VERSION ""

NS_ :

BS_:

BU_: SteeringControlModule SteeringController SteeringColumnUnit RearAxleSteeringController Engine ChassisController

BO_ 2583299326 GNSSSatsInView: 27 Vector__XXX
 SG_ PRNStatusN : 208|4@1+ (1,0) [0|15] "" Vector__XXX
 SG_ RangeResidualsN : 176|32@1- (1E-005,0) [-21470|21470] "m" Vector__XXX
 SG_ SNRN : 160|16@1- (0.01,0) [-327.64|327.64] "dB" Vector__XXX
 SG_ AzimuthN : 144|16@1+ (0.0001,0) [0|6.28318] "rad" Vector__XXX
 SG_ ElevationN : 128|16@1- (0.0001,0) [-3.14159|3.14159] "rad" Vector__XXX
 SG_ PRNN : 120|8@1+ (1,0) [0|252] "" Vector__XXX
 SG_ PRNStatus1 : 112|4@1+ (1,0) [0|15] "" Vector__XXX
 SG_ RangeResiduals1 : 80|32@1- (1E-005,0) [-21470|21470] "m" Vector__XXX
 SG_ SNR1 : 64|16@1- (0.01,0) [-327.64|327.64] "dB" Vector__XXX
 SG_ Azimuth1 : 48|16@1+ (0.0001,0) [0|6.28318] "rad" Vector__XXX
 SG_ Elevation1 : 32|16@1- (0.0001,0) [-3.14159|3.14159] "rad" Vector__XXX
 SG_ PRN1 : 24|8@1+ (1,0) [0|252] "" Vector__XXX
 SG_ NumberOfSVs_ : 16|8@1+ (1,0) [0|252] "" Vector__XXX
 SG_ SID : 0|8@1+ (1,0) [0|252] "" Vector__XXX
 SG_ RangeResidualMode : 8|2@1- (1,0) [0|3] "" Vector__XXX

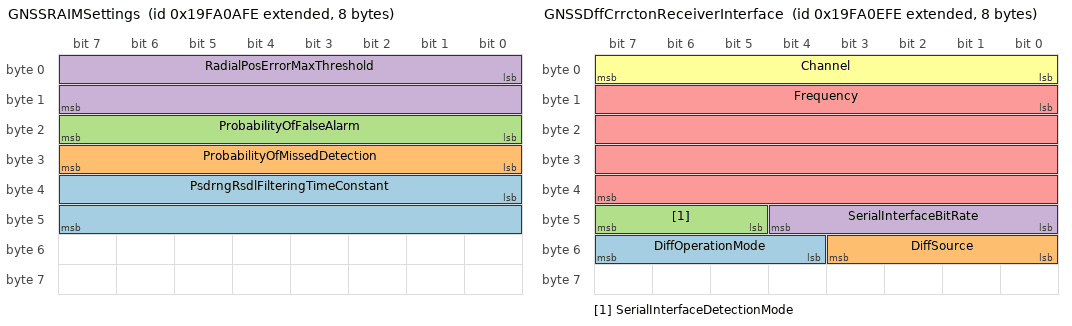
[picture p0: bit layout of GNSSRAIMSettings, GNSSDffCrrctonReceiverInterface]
BO_ 2583300862 GNSSRAIMSettings: 8 Vector__XXX
 SG_ PsdrngRsdlFilteringTimeConstant : 32|16@1+ (1,0) [0|65532] "sec" Vector__XXX
 SG_ ProbabilityOfMissedDetection : 24|8@1- (1,0) [-124|124] "%" Vector__XXX
 SG_ ProbabilityOfFalseAlarm : 16|8@1- (1,0) [-124|124] "" Vector__XXX
 SG_ RadialPosErrorMaxThreshold : 0|16@1+ (0.01,0) [0|655.32] "m" Vector__XXX

BO_ 2583300606 GNSSRAIMOutput: 15 Vector__XXX
 SG_ StdDeviationOfBias : 104|16@1- (0.01,0) [-327.64|327.64] "m" Vector__XXX
 SG_ EstimateOfPseudorangeBias : 88|16@1- (0.01,0) [-327.64|327.64] "m" Vector__XXX
 SG_ ProbabilityOfMissedDetection : 72|8@1- (1,0) [-124|124] "%" Vector__XXX
 SG_ SVIDOfMostLikelyFailedSat : 64|8@1+ (1,0) [0|252] "" Vector__XXX
 SG_ AltitudeExpectedError : 48|16@1- (0.01,0) [-327.64|327.64] "m" Vector__XXX
 SG_ LongitudeExpectedError : 32|16@1- (0.01,0) [-327.64|327.64] "m" Vector__XXX
 SG_ LatitudeExpectedError : 16|16@1- (0.01,0) [-327.64|327.64] "m" Vector__XXX
 SG_ IntegrityFlag : 8|2@1+ (1,0) [0|3] "" Vector__XXX
 SG_ SequenceID_ : 0|8@1+ (1,0) [0|252] "" Vector__XXX

BO_ 2583299838 GNSSPseudorangeNoiseStatistics: 15 Vector__XXX
 SG_ STDOfAltError : 104|16@1+ (0.01,0) [0|655.32] "m" Vector__XXX
 SG_ STDOfLonError : 88|16@1+ (0.01,0) [0|655.32] "m" Vector__XXX
 SG_ STDOfLatError : 72|16@1+ (0.01,0) [0|655.32] "m" Vector__XXX
 SG_ OrientationOfMajorAxis : 56|16@1+ (0.0001,0) [0|6.28318] "rad" Vector__XXX
 SG_ STDOfMinorAxis : 40|16@1+ (0.01,0) [0|655.32] "m" Vector__XXX
 SG_ STDOfMajorAxis : 24|16@1+ (0.01,0) [0|655.32] "m" Vector__XXX
 SG_ RMSOfPosUncertainty : 8|16@1+ (0.01,0) [0|655.32] "m" Vector__XXX
 SG_ SID : 0|8@1+ (1,0) [0|252] "" Vector__XXX

BO_ 2583301118 GNSSPseudorangeErrorStatistics: 15 Vector__XXX
 SG_ StdDevAltitudeError : 104|16@1+ (0.01,0) [0|655.32] "m" Vector__XXX
 SG_ StdDevLongitudeError : 88|16@1+ (0.01,0) [0|655.32] "m" Vector__XXX
 SG_ StdDevLatitudeError : 72|16@1+ (0.01,0) [0|655.32] "m" Vector__XXX
 SG_ OrientationOfErrorEllipse : 56|16@1+ (0.0001,0) [0|6.28318] "rad" Vector__XXX
 SG_ StdDevMinorErrorEllipse : 40|16@1+ (0.01,0) [0|655.32] "m" Vector__XXX
 SG_ StdDevMajorErrorEllipse : 24|16@1+ (0.01,0) [0|655.32] "m" Vector__XXX
 SG_ RMSStdDevOfRangeInputs : 8|16@1+ (0.01,0) [0|655.32] "m" Vector__XXX
 SG_ SequenceID_ : 0|8@1+ (1,0) [0|252] "" Vector__XXX

BO_ 2381841918 GNSSPosData: 51 Vector__XXX
 SG_ AgeOfDGNSSReferenceStationN : 392|16@1+ (0.01,0) [0|655.32] "sec" Vector__XXX
 SG_ ReferenceStationIDN : 380|12@1+ (1,0) [0|4095] "" Vector__XXX
 SG_ ReferenceStationTypeN : 376|4@1+ (1,0) [0|15] "" Vector__XXX
 SG_ AgeOfDGNSSCorrections1_ : 360|16@1+ (0.01,0) [0|655.32] "sec" Vector__XXX
 SG_ ReferenceStationID1_ : 348|12@1+ (1,0) [0|4095] "" Vector__XXX
 SG_ ReferenceStationType1 : 344|4@1+ (1,0) [0|15] "" Vector__XXX
 SG_ NumberOfReferenceStations_ : 336|8@1+ (1,0) [0|252] "" Vector__XXX
 SG_ GeoidalSeparation_ : 304|32@1- (0.01,0) [-21470000|21470000] "m" Vector__XXX
 SG_ PDOP_ : 288|16@1- (0.01,0) [-327.64|327.64] "" Vector__XXX
 SG_ HDOP_ : 272|16@1- (0.01,0) [-327.64|327.64] "" Vector__XXX
 SG_ NumberOfSVs_ : 264|8@1+ (1,0) [0|252] "" Vector__XXX
 SG_ Integrity : 256|2@1+ (1,0) [0|3] "" Vector__XXX
 SG_ MethodGNSS : 252|4@1+ (1,0) [0|15] "" Vector__XXX
 SG_ TypeOfSystem_ : 248|4@1+ (1,0) [0|15] "" Vector__XXX
 SG_ Altitude_high : 216|32@1- (4294.967296,0) [-9223000000000|9223000000000] "m" Vector__XXX
 SG_ Altitude_low : 184|32@1+ (1E-006,0) [0|4294.967295] "m" Vector__XXX
 SG_ Longitude_high : 152|32@1- (4.294967296E-007,0) [-180|180] "deg" Vector__XXX
 SG_ Longitude_low : 120|32@1+ (1E-016,0) [0|4.294967295E-007] "deg" Vector__XXX
 SG_ Latitude_high : 88|32@1- (4.294967296E-007,0) [-90|90] "deg" Vector__XXX
 SG_ Latitude_low : 56|32@1+ (1E-016,0) [0|4.294967295E-007] "deg" Vector__XXX
 SG_ PosTime : 24|32@1+ (0.0001,0) [0|86401] "sec" Vector__XXX
 SG_ PosDate : 8|16@1+ (1,0) [0|65532] "day" Vector__XXX
 SG_ SID : 0|8@1+ (1,0) [0|252] "" Vector__XXX

BO_ 2583301886 GNSSDffCrrctonReceiverInterface: 8 Vector__XXX
 SG_ DiffOperationMode : 52|4@1+ (1,0) [0|15] "" Vector__XXX
 SG_ DiffSource : 48|4@1+ (1,0) [0|15] "" Vector__XXX
 SG_ SerialInterfaceDetectionMode : 45|3@1+ (1,0) [0|7] "" Vector__XXX
 SG_ SerialInterfaceBitRate : 40|5@1+ (1,0) [0|31] "" Vector__XXX
 SG_ Frequency : 8|32@1+ (10,0) [0|327040] "Hz" Vector__XXX
 SG_ Channel : 0|8@1+ (1,0) [0|252] "" Vector__XXX

BO_ 2583302142 GNSSDffCorrectionReceiverSignal: 21 Vector__XXX
 SG_ SatelliteServiceIDNo : 147|16@1+ (1,0) [0|65535] "" Vector__XXX
 SG_ TimeSinceLastSatDiffSync : 131|16@1+ (0.01,0) [0|655.32] "sec" Vector__XXX
 SG_ DiffSource : 127|4@1+ (1,0) [0|15] "" Vector__XXX
 SG_ UsedAsCorrectionSource : 123|2@1+ (1,0) [0|3] "" Vector__XXX
 SG_ DiffSignalDetectionMode : 117|6@1+ (1,0) [0|63] "" Vector__XXX
 SG_ DiffSignalBitRate : 112|5@1+ (1,0) [0|31] "" Vector__XXX
 SG_ StationID : 100|12@1+ (1,0) [0|4095] "" Vector__XXX
 SG_ StationType : 96|4@1+ (1,0) [0|15] "" Vector__XXX
 SG_ Frequency : 64|32@1+ (10,0) [0|327040] "Hz" Vector__XXX
 SG_ SignalSNR : 48|16@1- (0.01,0) [-327.64|327.64] "dB" Vector__XXX
 SG_ SignalStrength : 16|32@1- (0.01,0) [-327.64|327.64] "dB re: uV/m" Vector__XXX
 SG_ Channel : 8|8@1+ (1,0) [0|252] "" Vector__XXX
 SG_ SID : 0|8@1+ (1,0) [0|252] "" Vector__XXX

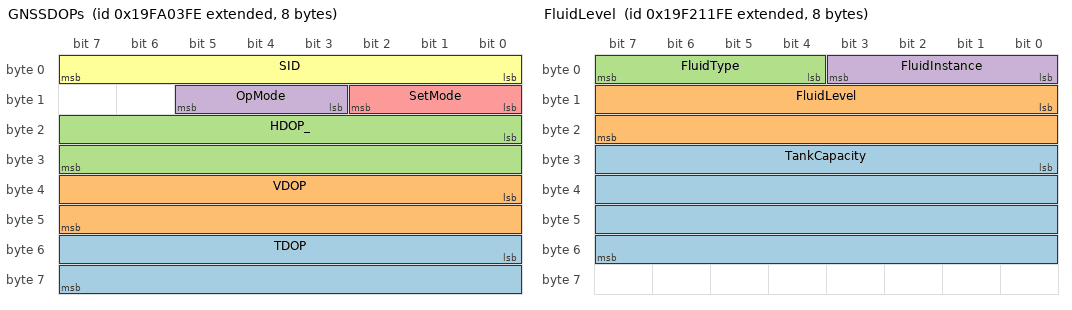
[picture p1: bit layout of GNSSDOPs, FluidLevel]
BO_ 2583299070 GNSSDOPs: 8 Vector__XXX
 SG_ TDOP : 48|16@1- (0.01,0) [-327.64|327.64] "" Vector__XXX
 SG_ VDOP : 32|16@1- (0.01,0) [-327.64|327.64] "" Vector__XXX
 SG_ HDOP_ : 16|16@1- (0.01,0) [-327.64|327.64] "" Vector__XXX
 SG_ OpMode : 11|3@1+ (1,0) [0|7] "" Vector__XXX
 SG_ SetMode : 8|3@1+ (1,0) [0|7] "" Vector__XXX
 SG_ SID : 0|8@1+ (1,0) [0|252] "" Vector__XXX

BO_ 2583298814 GNSSCtrlStatus: 16 Vector__XXX
 SG_ UseAntennaAltitudeFor2DMode : 120|2@1+ (1,0) [0|3] "" Vector__XXX
 SG_ AntennaAltitudeFor2DMode : 88|32@1- (0.01,0) [-21470000|21470000] "m" Vector__XXX
 SG_ MaxCorrectionAge : 72|16@1+ (0.01,0) [0|655.32] "sec" Vector__XXX
 SG_ Pos_VelocityFilter : 70|2@1+ (1,0) [0|3] "" Vector__XXX
 SG_ DGNSSMode : 67|3@1+ (1,0) [0|7] "" Vector__XXX
 SG_ GNSSMode : 64|3@1+ (1,0) [0|7] "" Vector__XXX
 SG_ SNRMask : 48|16@1- (0.01,0) [-327.64|327.64] "dB" Vector__XXX
 SG_ PDOPSwitch : 32|16@1- (0.01,0) [-327.64|327.64] "" Vector__XXX
 SG_ PDOPMask : 16|16@1- (0.01,0) [-327.64|327.64] "" Vector__XXX
 SG_ SVElevationMask : 0|16@1- (0.0001,0) [-3.14159|3.14159] "rad" Vector__XXX

BO_ 2583303422 GLONASSAlmanacData: 26 Vector__XXX
 SG_ tnA2 : 196|12@1+ (1,0) [0|4095] "" Vector__XXX
 SG_ tcA : 168|28@1+ (1,0) [0|268435455] "" Vector__XXX
 SG_ inA : 144|24@1+ (1,0) [0|16777215] "" Vector__XXX
 SG_ nA3 : 120|24@1+ (1,0) [0|16777215] "" Vector__XXX
 SG_ tnA : 96|24@1+ (1,0) [0|16777215] "" Vector__XXX
 SG_ TnA : 72|24@1+ (1,0) [0|16777215] "" Vector__XXX
 SG_ nA2 : 56|16@1+ (1,0) [0|65535] "" Vector__XXX
 SG_ DOT : 48|8@1+ (1,0) [0|255] "" Vector__XXX
 SG_ nA : 32|16@1+ (1,0) [0|65535] "" Vector__XXX
 SG_ HnA : 27|5@1+ (1,0) [0|31] "" Vector__XXX
 SG_ CnA : 26|1@1+ (1,0) [0|1] "" Vector__XXX
 SG_ NA : 8|16@1+ (1,0) [0|65532] "" Vector__XXX
 SG_ PRN : 0|8@1+ (1,0) [0|252] "" Vector__XXX

BO_ 2582778366 FluidLevel: 8 Vector__XXX
 SG_ TankCapacity : 24|32@1+ (0.0001,0) [0|429600] "cu m" Vector__XXX
 SG_ FluidLevel : 8|16@1- (1,0) [-124|124] "" Vector__XXX
 SG_ FluidType : 4|4@1+ (1,0) [0|15] "" Vector__XXX
 SG_ FluidInstance : 0|4@1+ (1,0) [0|15] "" Vector__XXX

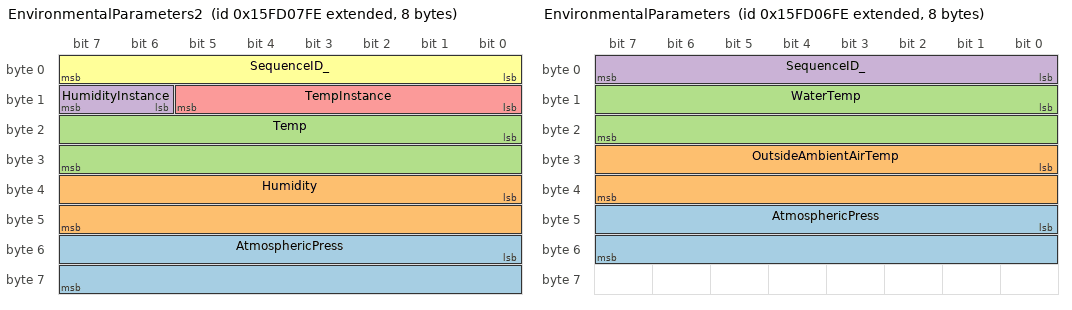
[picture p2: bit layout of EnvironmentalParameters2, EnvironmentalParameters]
BO_ 2516387838 EnvironmentalParameters2: 8 Vector__XXX
 SG_ AtmosphericPress : 48|16@1+ (100,0) [0|6553200] "Pa" Vector__XXX
 SG_ Humidity : 32|16@1- (1,0) [-124|124] "" Vector__XXX
 SG_ Temp : 16|16@1+ (0.01,0) [0|655.32] "°K" Vector__XXX
 SG_ HumidityInstance : 14|2@1+ (1,0) [0|3] "" Vector__XXX
 SG_ TempInstance : 8|6@1+ (1,0) [0|63] "" Vector__XXX
 SG_ SequenceID_ : 0|8@1+ (1,0) [0|252] "" Vector__XXX

BO_ 2516387582 EnvironmentalParameters: 8 Vector__XXX
 SG_ AtmosphericPress : 40|16@1+ (100,0) [0|6553200] "Pa" Vector__XXX
 SG_ OutsideAmbientAirTemp : 24|16@1+ (0.01,0) [0|655.32] "°K" Vector__XXX
 SG_ WaterTemp : 8|16@1+ (0.01,0) [0|655.32] "°K" Vector__XXX
 SG_ SequenceID_ : 0|8@1+ (1,0) [0|252] "" Vector__XXX

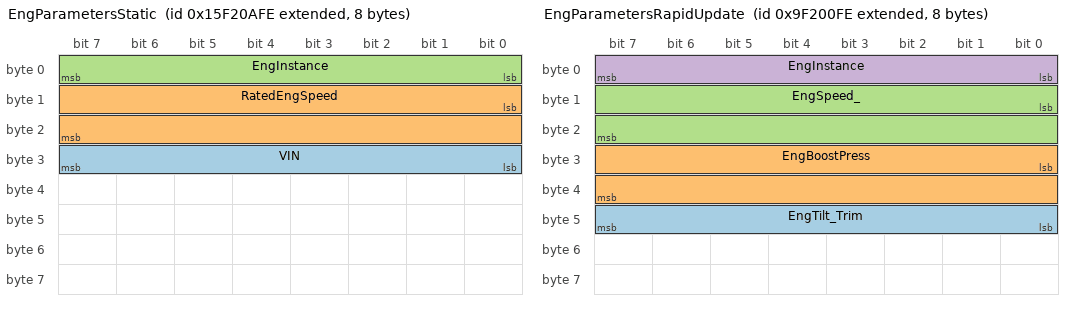
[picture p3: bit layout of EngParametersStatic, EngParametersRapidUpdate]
BO_ 2515667710 EngParametersStatic: 8 Vector__XXX
 SG_ VIN : 24|8@1+ (1,0) [0|255] "ASCII" Vector__XXX
 SG_ RatedEngSpeed : 8|16@1+ (1,0) [0|16383] "rpm" Vector__XXX
 SG_ EngInstance : 0|8@1+ (1,0) [0|255] "" Vector__XXX

BO_ 2314338558 EngParametersRapidUpdate: 8 Vector__XXX
 SG_ EngTilt_Trim : 40|8@1- (1,0) [-124|124] "" Vector__XXX
 SG_ EngBoostPress : 24|16@1+ (100,0) [0|6553200] "Pa" Vector__XXX
 SG_ EngSpeed_ : 8|16@1+ (1,0) [0|16383] "rpm" Vector__XXX
 SG_ EngInstance : 0|8@1+ (1,0) [0|255] "" Vector__XXX

BO_ 2314338814 EngParametersDynamic: 26 Vector__XXX
 SG_ PercentEngTorque : 200|8@1- (1,0) [-124|124] "" Vector__XXX
 SG_ PercentEngLoad : 192|8@1- (1,0) [-124|124] "" Vector__XXX
 SG_ EngDiscreteStatus2 : 176|16@1+ (1,0) [0|65535] "" Vector__XXX
 SG_ EngDiscreteStatus1 : 160|16@1+ (1,0) [0|65535] "" Vector__XXX
 SG_ FuelPress : 136|16@1+ (1000,0) [0|65532000] "Pa" Vector__XXX
 SG_ EngCoolantPress_ : 120|16@1+ (100,0) [0|6553200] "Pa" Vector__XXX
 SG_ TotalEngHours : 88|32@1+ (1,0) [0|32704] "sec" Vector__XXX
 SG_ FuelRate : 72|16@1- (0.0001,0) [-3.2764|3.2764] "(cu m)/hr" Vector__XXX
 SG_ AltPotential : 56|16@1- (0.01,0) [-327.64|327.64] "V" Vector__XXX
 SG_ EngTemp : 40|16@1+ (0.01,0) [0|655.32] "°K" Vector__XXX
 SG_ EngOilTemp : 24|16@1+ (0.1,0) [0|6553.2] "°K" Vector__XXX
 SG_ EngOilPress_ : 8|16@1+ (100,0) [0|6553200] "Pa" Vector__XXX
 SG_ EngInstance : 0|8@1+ (1,0) [0|255] "" Vector__XXX

BO_ 2582975486 DistanceLog: 14 Vector__XXX
 SG_ DistanceSinceLastReset : 80|32@1+ (1,0) [0|32704] "m" Vector__XXX
 SG_ TotalCumulativeDistance : 48|32@1+ (1,0) [0|32704] "m" Vector__XXX
 SG_ MeasurementTime : 16|32@1+ (0.0001,0) [0|86401] "sec" Vector__XXX
 SG_ MeasurementDate : 0|16@1+ (1,0) [0|65532] "day" Vector__XXX

BO_ 2382238206 DirectionData: 14 Vector__XXX
 SG_ Drift : 96|16@1+ (0.01,0) [0|655.32] "m/s" Vector__XXX
 SG_ Set : 80|16@1+ (0.0001,0) [0|6.28318] "rad" Vector__XXX
 SG_ SpeedThroughWater : 64|16@1+ (0.01,0) [0|655.32] "m/s" Vector__XXX
 SG_ Heading : 48|16@1+ (0.0001,0) [0|6.28318] "rad" Vector__XXX
 SG_ SpeedOverGround : 32|16@1+ (0.01,0) [0|655.32] "m/s" Vector__XXX
 SG_ CourseOverGround : 16|16@1+ (0.0001,0) [0|6.28318] "rad" Vector__XXX
 SG_ SID : 8|8@1+ (1,0) [0|252] "" Vector__XXX
 SG_ Set_COG_HeadingRef : 4|2@1+ (1,0) [0|3] "" Vector__XXX
 SG_ DataMode : 0|4@1+ (1,0) [0|15] "" Vector__XXX

BO_ 2583172350 Datum: 8 Vector__XXX
 SG_ LocalDatum : 0|8@1+ (1,0) [0|255] "ASCII" Vector__XXX

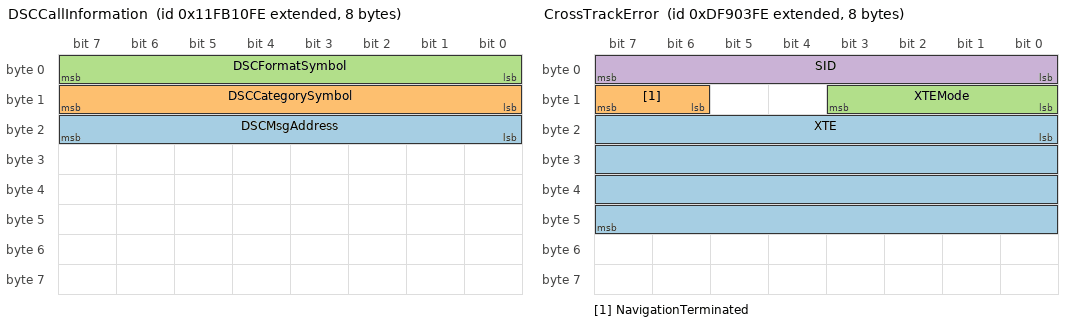
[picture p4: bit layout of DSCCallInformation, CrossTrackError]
BO_ 2449150206 DSCCallInformation: 8 Vector__XXX
 SG_ DSCMsgAddress : 16|8@1+ (1,0) [0|255] "ASCII" Vector__XXX
 SG_ DSCCategorySymbol : 8|8@1+ (1,0) [0|252] "" Vector__XXX
 SG_ DSCFormatSymbol : 0|8@1+ (1,0) [0|252] "" Vector__XXX

BO_ 2583301630 DGNSSCorrections: 16 Vector__XXX
 SG_ IOD : 120|8@1+ (1,0) [0|252] "" Vector__XXX
 SG_ UDRE : 104|16@1+ (0.01,0) [0|655.32] "m" Vector__XXX
 SG_ RRC : 88|16@1- (0.0001,0) [-3.2764|3.2764] "m/s" Vector__XXX
 SG_ PRC : 56|32@1- (0.0001,0) [-214700|214700] "m" Vector__XXX
 SG_ SatelliteID : 48|8@1+ (1,0) [0|252] "" Vector__XXX
 SG_ StationHealth : 40|4@1+ (1,0) [0|15] "" Vector__XXX
 SG_ TimeOfCorrections : 24|16@1+ (1,0) [0|6553.2] "sec" Vector__XXX
 SG_ ReferenceStationType : 20|4@1+ (1,0) [0|15] "" Vector__XXX
 SG_ ReferenceStationID : 8|12@1+ (1,0) [0|4095] "" Vector__XXX
 SG_ SequenceID_ : 0|8@1+ (1,0) [0|252] "" Vector__XXX

BO_ 2583499518 CurrentStationData: 26 Vector__XXX
 SG_ StationIDString : 200|8@1+ (1,0) [0|255] "ASCII" Vector__XXX
 SG_ WaterTemp : 184|16@1+ (0.01,0) [0|655.32] "°K" Vector__XXX
 SG_ CurrentFlowDirection : 168|16@1+ (0.0001,0) [0|6.28318] "rad" Vector__XXX
 SG_ CurrentSpeed : 152|16@1+ (0.01,0) [0|655.32] "m/s" Vector__XXX
 SG_ MeasurementDepth : 120|32@1+ (0.01,0) [0|42950000] "m" Vector__XXX
 SG_ StationLocationLongitude : 88|32@1- (1E-007,0) [-180|180] "deg" Vector__XXX
 SG_ StationLocationLatitude : 56|32@1- (1E-007,0) [-90|90] "deg" Vector__XXX
 SG_ MeasurementTime : 24|32@1+ (0.0001,0) [0|86401] "sec" Vector__XXX
 SG_ MeasurementDate : 8|16@1+ (1,0) [0|65532] "day" Vector__XXX
 SG_ State : 4|3@1+ (1,0) [0|7] "" Vector__XXX
 SG_ Mode : 0|4@1+ (1,0) [0|15] "" Vector__XXX

BO_ 2381906942 CrossTrackError: 8 Vector__XXX
 SG_ XTE : 16|32@1- (0.01,0) [-21470000|21470000] "m" Vector__XXX
 SG_ NavigationTerminated : 14|2@1+ (1,0) [0|3] "" Vector__XXX
 SG_ XTEMode : 8|4@1+ (1,0) [0|15] "" Vector__XXX
 SG_ SID : 0|8@1+ (1,0) [0|252] "" Vector__XXX

BO_ 2582648574 ConfigInformation: 8 Vector__XXX
 SG_ InstallationDescriptionField1 : 0|8@1+ (1,0) [0|255] "ASCII" Vector__XXX

BO_ 2583238398 BringAndDistanceBetweenTwoMarks: 17 Vector__XXX
 SG_ DestinationMarkID : 104|32@1+ (1,0) [0|4294967292] "" Vector__XXX
 SG_ OriginMarkId : 72|32@1+ (1,0) [0|4294967292] "" Vector__XXX
 SG_ DestinationMarkType : 68|4@1+ (1,0) [0|15] "" Vector__XXX
 SG_ OriginMarkType : 64|4@1+ (1,0) [0|15] "" Vector__XXX
 SG_ Distance : 32|32@1- (0.01,0) [-21470000|21470000] "m" Vector__XXX
 SG_ BearingiginToDestination : 16|16@1+ (0.0001,0) [0|6.28318] "rad" Vector__XXX
 SG_ CalculationType : 10|2@1+ (1,0) [0|3] "" Vector__XXX
 SG_ BearingRef : 8|2@1+ (1,0) [0|3] "" Vector__XXX
 SG_ SID : 0|8@1+ (1,0) [0|252] "" Vector__XXX

BO_ 2381450750 BinarySwitchBankStatus: 8 Vector__XXX
 SG_ Indic28 : 62|2@1+ (1,0) [0|3] "" Vector__XXX
 SG_ Indic27 : 60|2@1+ (1,0) [0|3] "" Vector__XXX
 SG_ Indic26 : 58|2@1+ (1,0) [0|3] "" Vector__XXX
 SG_ Indic25 : 56|2@1+ (1,0) [0|3] "" Vector__XXX
 SG_ Indic24 : 54|2@1+ (1,0) [0|3] "" Vector__XXX
 SG_ Indic23 : 52|2@1+ (1,0) [0|3] "" Vector__XXX
 SG_ Indic22 : 50|2@1+ (1,0) [0|3] "" Vector__XXX
 SG_ Indic21 : 48|2@1+ (1,0) [0|3] "" Vector__XXX
 SG_ Indic20 : 46|2@1+ (1,0) [0|3] "" Vector__XXX
 SG_ Indic19 : 44|2@1+ (1,0) [0|3] "" Vector__XXX
 SG_ Indic18 : 42|2@1+ (1,0) [0|3] "" Vector__XXX
 SG_ Indic17 : 40|2@1+ (1,0) [0|3] "" Vector__XXX
 SG_ Indic16 : 38|2@1+ (1,0) [0|3] "" Vector__XXX
 SG_ Indic15 : 36|2@1+ (1,0) [0|3] "" Vector__XXX
 SG_ Indic14 : 34|2@1+ (1,0) [0|3] "" Vector__XXX
 SG_ Indic13 : 32|2@1+ (1,0) [0|3] "" Vector__XXX
 SG_ Indic12 : 30|2@1+ (1,0) [0|3] "" Vector__XXX
 SG_ Indic11 : 28|2@1+ (1,0) [0|3] "" Vector__XXX
 SG_ Indic10 : 26|2@1+ (1,0) [0|3] "" Vector__XXX
 SG_ Indic9 : 24|2@1+ (1,0) [0|3] "" Vector__XXX
 SG_ Indic8 : 22|2@1+ (1,0) [0|3] "" Vector__XXX
 SG_ Indic7 : 20|2@1+ (1,0) [0|3] "" Vector__XXX
 SG_ Indic6 : 18|2@1+ (1,0) [0|3] "" Vector__XXX
 SG_ Indic5 : 16|2@1+ (1,0) [0|3] "" Vector__XXX
 SG_ Indic4 : 14|2@1+ (1,0) [0|3] "" Vector__XXX
 SG_ Indic3 : 12|2@1+ (1,0) [0|3] "" Vector__XXX
 SG_ Indic2 : 10|2@1+ (1,0) [0|3] "" Vector__XXX
 SG_ Indic1 : 8|2@1+ (1,0) [0|3] "" Vector__XXX
 SG_ IndicatorBankInstance : 0|8@1+ (1,0) [0|252] "" Vector__XXX

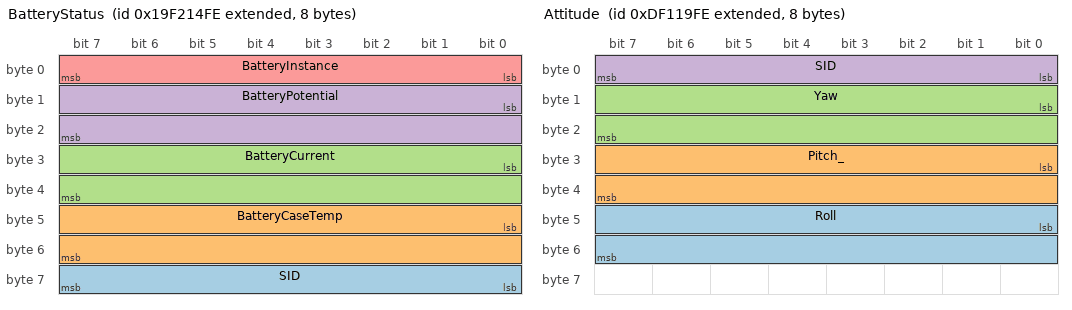
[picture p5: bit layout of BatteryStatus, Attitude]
BO_ 2582779134 BatteryStatus: 8 Vector__XXX
 SG_ SID : 56|8@1+ (1,0) [0|252] "" Vector__XXX
 SG_ BatteryCaseTemp : 40|16@1+ (0.01,0) [0|655.32] "°K" Vector__XXX
 SG_ BatteryCurrent : 24|16@1- (0.1,0) [-3276.4|3276.4] "A" Vector__XXX
 SG_ BatteryPotential : 8|16@1- (0.01,0) [-327.64|327.64] "V" Vector__XXX
 SG_ BatteryInstance : 0|8@1+ (1,0) [0|252] "" Vector__XXX

BO_ 2381388286 Attitude: 8 Vector__XXX
 SG_ Roll : 40|16@1- (0.0001,0) [-3.14159|3.14159] "rad" Vector__XXX
 SG_ Pitch_ : 24|16@1+ (0.0001,0) [-3.14159|3.14159] "rad" Vector__XXX
 SG_ Yaw : 8|16@1- (0.0001,0) [-3.14159|3.14159] "rad" Vector__XXX
 SG_ SID : 0|8@1+ (1,0) [0|252] "" Vector__XXX

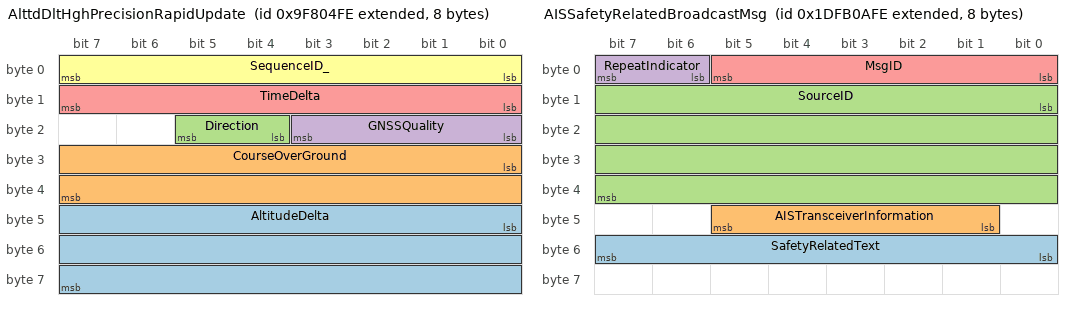
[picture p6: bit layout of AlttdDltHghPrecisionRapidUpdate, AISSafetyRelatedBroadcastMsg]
BO_ 2314732798 AlttdDltHghPrecisionRapidUpdate: 8 Vector__XXX
 SG_ AltitudeDelta : 40|24@1- (0.001,0) [-8388|8388] "m" Vector__XXX
 SG_ CourseOverGround : 24|16@1+ (0.0001,0) [0|6.28318] "rad" Vector__XXX
 SG_ Direction : 20|2@1+ (1,0) [0|3] "" Vector__XXX
 SG_ GNSSQuality : 16|4@1+ (1,0) [0|15] "" Vector__XXX
 SG_ TimeDelta : 8|8@1+ (0.005,0) [0|1.26] "sec" Vector__XXX
 SG_ SequenceID_ : 0|8@1+ (1,0) [0|252] "" Vector__XXX

BO_ 2650474750 AISUTC_DateInquiry: 11 Vector__XXX
 SG_ DestinationID : 48|32@1+ (1,0) [0|4294967292] "" Vector__XXX
 SG_ AISTransceiverInformation : 41|5@1+ (1,0) [0|31] "" Vector__XXX
 SG_ SourceID : 8|32@1+ (1,0) [0|4294967292] "" Vector__XXX
 SG_ RepeatIndicator : 6|2@1+ (1,0) [0|3] "" Vector__XXX
 SG_ MsgID : 0|6@1+ (1,0) [0|63] "" Vector__XXX

BO_ 2650472958 AISUTCAndDateReport: 26 Vector__XXX
 SG_ TypeOfElectronicPosingDevice : 188|4@1+ (1,0) [0|15] "" Vector__XXX
 SG_ PosDate : 168|16@1+ (1,0) [0|65532] "day" Vector__XXX
 SG_ AISTransceiverInformation : 163|5@1+ (1,0) [0|31] "" Vector__XXX
 SG_ CommunicationState : 144|19@1+ (1,0) [0|524287] "" Vector__XXX
 SG_ PosTime : 112|32@1+ (0.0001,0) [0|86401] "sec" Vector__XXX
 SG_ RAIMflag : 105|1@1+ (1,0) [0|1] "" Vector__XXX
 SG_ PosAccuracy : 104|1@1+ (1,0) [0|1] "" Vector__XXX
 SG_ Latitude_ : 72|32@1- (1E-007,0) [-90|90] "deg" Vector__XXX
 SG_ Longitude_ : 40|32@1- (1E-007,0) [-180|180] "deg" Vector__XXX
 SG_ UserID : 8|32@1+ (1,0) [0|4294967292] "" Vector__XXX
 SG_ RepeatIndicator : 6|2@1+ (1,0) [0|3] "" Vector__XXX
 SG_ MsgID : 0|6@1+ (1,0) [0|63] "" Vector__XXX

BO_ 2650475262 AISSafetyRelatedBroadcastMsg: 8 Vector__XXX
 SG_ SafetyRelatedText : 48|8@1+ (1,0) [0|255] "ASCII" Vector__XXX
 SG_ AISTransceiverInformation : 41|5@1+ (1,0) [0|31] "" Vector__XXX
 SG_ SourceID : 8|32@1+ (1,0) [0|4294967292] "" Vector__XXX
 SG_ RepeatIndicator : 6|2@1+ (1,0) [0|3] "" Vector__XXX
 SG_ MsgID : 0|6@1+ (1,0) [0|63] "" Vector__XXX

BO_ 2650474238 AISSARAircraftPosReport: 27 Vector__XXX
 SG_ DataTerminalEquipment : 208|1@1+ (1,0) [0|1] "" Vector__XXX
 SG_ Altitude_ : 168|32@1- (0.01,0) [-21470000|21470000] "m" Vector__XXX
 SG_ AISTransceiverInformation : 163|5@1+ (1,0) [0|31] "" Vector__XXX
 SG_ CommunicationState : 144|19@1+ (1,0) [0|524287] "" Vector__XXX
 SG_ SOG : 128|16@1+ (0.01,0) [0|655.32] "m/s" Vector__XXX
 SG_ COG : 112|16@1+ (0.0001,0) [0|6.28318] "rad" Vector__XXX
 SG_ TimeStamp : 106|6@1+ (1,0) [0|63] "" Vector__XXX
 SG_ RAIMFlag : 105|1@1+ (1,0) [0|1] "" Vector__XXX
 SG_ PosAccuracy : 104|1@1+ (1,0) [0|1] "" Vector__XXX
 SG_ Latitude_ : 72|32@1- (1E-007,0) [-90|90] "deg" Vector__XXX
 SG_ Longitude_ : 40|32@1- (1E-007,0) [-180|180] "deg" Vector__XXX
 SG_ UserID : 8|32@1+ (1,0) [0|4294967292] "" Vector__XXX
 SG_ RepeatIndicator : 6|2@1+ (1,0) [0|3] "" Vector__XXX
 SG_ MsgID : 0|6@1+ (1,0) [0|63] "" Vector__XXX

BO_ 2650475518 AISInterrogation: 25 Vector__XXX
 SG_ SlotOffset21 : 176|16@1+ (1,0) [0|65532] "" Vector__XXX
 SG_ MsgID21 : 170|6@1+ (1,0) [0|63] "" Vector__XXX
 SG_ DestinationID2 : 136|32@1+ (1,0) [0|4294967292] "" Vector__XXX
 SG_ SlotOffset12 : 112|16@1+ (1,0) [0|65532] "" Vector__XXX
 SG_ MsgID12 : 106|6@1+ (1,0) [0|63] "" Vector__XXX
 SG_ SlotOffset11 : 88|16@1+ (1,0) [0|65532] "" Vector__XXX
 SG_ MsgID11 : 82|6@1+ (1,0) [0|63] "" Vector__XXX
 SG_ DestinationID1 : 48|32@1+ (1,0) [0|4294967292] "" Vector__XXX
 SG_ AISTransceiverInformation : 41|5@1+ (1,0) [0|31] "" Vector__XXX
 SG_ SourceID : 8|32@1+ (1,0) [0|4294967292] "" Vector__XXX
 SG_ RepeatIndicator : 6|2@1+ (1,0) [0|3] "" Vector__XXX
 SG_ MsgID : 0|6@1+ (1,0) [0|63] "" Vector__XXX

BO_ 2650476030 AISDataLinkManagementMsg: 31 Vector__XXX
 SG_ Increment4 : 224|16@1+ (1,0) [0|65532] "" Vector__XXX
 SG_ TimeOut4 : 216|8@1+ (1,0) [0|252] "" Vector__XXX
 SG_ NumberOfSlots4 : 208|8@1+ (1,0) [0|252] "" Vector__XXX
 SG_ OffsetNumber4 : 192|16@1+ (1,0) [0|65532] "" Vector__XXX
 SG_ Increment3 : 176|16@1+ (1,0) [0|65532] "" Vector__XXX
 SG_ TimeOut3 : 168|8@1+ (1,0) [0|252] "" Vector__XXX
 SG_ NumberOfSlots3 : 160|8@1+ (1,0) [0|252] "" Vector__XXX
 SG_ OffsetNumber3 : 144|16@1+ (1,0) [0|65532] "" Vector__XXX
 SG_ Increment2 : 128|16@1+ (1,0) [0|65532] "" Vector__XXX
 SG_ TimeOut2 : 120|8@1+ (1,0) [0|252] "" Vector__XXX
 SG_ NumberOfSlots2 : 112|8@1+ (1,0) [0|252] "" Vector__XXX
 SG_ OffsetNumber2 : 96|16@1+ (1,0) [0|65532] "" Vector__XXX
 SG_ Increment1 : 80|16@1+ (1,0) [0|65532] "" Vector__XXX
 SG_ TimeOut1 : 72|8@1+ (1,0) [0|252] "" Vector__XXX
 SG_ NumberOfSlots1 : 64|8@1+ (1,0) [0|252] "" Vector__XXX
 SG_ OffsetNumber1 : 48|16@1+ (1,0) [0|65532] "" Vector__XXX
 SG_ AISTransceiverInformation : 41|5@1+ (1,0) [0|31] "" Vector__XXX
 SG_ SourceStationID : 8|32@1+ (1,0) [0|4294967292] "" Vector__XXX
 SG_ RepeatIndicator : 6|2@1+ (1,0) [0|3] "" Vector__XXX
 SG_ MsgID : 0|6@1+ (1,0) [0|63] "" Vector__XXX

BO_ 2583363838 AISDGNSSBroadcastBinaryMsg: 17 Vector__XXX
 SG_ NumberOfBitsInBinaryDataField : 120|16@1+ (1,0) [0|65532] "" Vector__XXX
 SG_ Latitude_ : 80|32@1- (1E-007,0) [-90|90] "deg" Vector__XXX
 SG_ Longitude_ : 48|32@1- (1E-007,0) [-180|180] "deg" Vector__XXX
 SG_ AISTransceiverInformation : 41|5@1+ (1,0) [0|31] "" Vector__XXX
 SG_ SourceID : 8|32@1+ (1,0) [0|4294967292] "" Vector__XXX
 SG_ RepeatIndicator : 6|2@1+ (1,0) [0|3] "" Vector__XXX
 SG_ MsgID : 0|6@1+ (1,0) [0|63] "" Vector__XXX

BO_ 2650473214 AISClssASttcAndVyageRelatedData: 10 Vector__XXX
 SG_ CallSign : 72|8@1+ (1,0) [0|255] "ASCII" Vector__XXX
 SG_ IMO : 40|32@1+ (1,0) [0|4294967292] "" Vector__XXX
 SG_ UserID : 8|32@1+ (1,0) [0|4294967292] "" Vector__XXX
 SG_ RepeatIndicator : 6|2@1+ (1,0) [0|3] "" Vector__XXX
 SG_ MsgID : 0|6@1+ (1,0) [0|63] "" Vector__XXX

BO_ 2448953342 AISClassBPosReport: 26 Vector__XXX
 SG_ ComminicationStateSelectorFlag : 200|1@1+ (1,0) [0|1] "" Vector__XXX
 SG_ TrueHeading : 168|16@1+ (0.0001,0) [0|6.28318] "rad" Vector__XXX
 SG_ AISTransceiverInformation : 163|5@1+ (1,0) [0|31] "" Vector__XXX
 SG_ CommunicationState : 144|19@1+ (1,0) [0|524287] "" Vector__XXX
 SG_ SOG : 128|16@1+ (0.01,0) [0|655.32] "m/s" Vector__XXX
 SG_ COG : 112|16@1+ (0.0001,0) [0|6.28318] "rad" Vector__XXX
 SG_ TimeStamp : 106|6@1+ (1,0) [0|63] "" Vector__XXX
 SG_ RAIMflag : 105|1@1+ (1,0) [0|1] "" Vector__XXX
 SG_ PosAccuracy : 104|1@1+ (1,0) [0|1] "" Vector__XXX
 SG_ Latitude_ : 72|32@1- (1E-007,0) [-90|90] "deg" Vector__XXX
 SG_ Longitude_ : 40|32@1- (1E-007,0) [-180|180] "deg" Vector__XXX
 SG_ UserID : 8|32@1+ (1,0) [0|4294967292] "" Vector__XXX
 SG_ RepeatIndicator : 6|2@1+ (1,0) [0|3] "" Vector__XXX
 SG_ MsgID : 0|6@1+ (1,0) [0|63] "" Vector__XXX

BO_ 2448953598 AISClassBExPosReport: 33 Vector__XXX
 SG_ Name : 256|8@1+ (1,0) [0|255] "ASCII" Vector__XXX
 SG_ PosReferencePointAftOfShipsBow : 240|16@1+ (0.1,0) [0|6553.2] "m" Vector__XXX
 SG_ PosReferencePointFromStarboard : 224|16@1+ (0.1,0) [0|6553.2] "m" Vector__XXX
 SG_ ShipBeam : 208|16@1+ (0.1,0) [0|6553.2] "m" Vector__XXX
 SG_ ShipLength : 192|16@1+ (0.1,0) [0|6553.2] "m" Vector__XXX
 SG_ TypeOfElectronicPosingDevice : 188|4@1+ (1,0) [0|15] "" Vector__XXX
 SG_ TrueHeading : 168|16@1+ (0.0001,0) [0|6.28318] "rad" Vector__XXX
 SG_ Ship_CargoType : 160|8@1+ (1,0) [0|255] "" Vector__XXX
 SG_ SOG : 128|16@1+ (0.01,0) [0|655.32] "m/s" Vector__XXX
 SG_ COG : 112|16@1+ (0.0001,0) [0|6.28318] "rad" Vector__XXX
 SG_ TimeStamp : 106|6@1+ (1,0) [0|63] "" Vector__XXX
 SG_ RAIMflag : 105|1@1+ (1,0) [0|1] "" Vector__XXX
 SG_ PosAccuracy : 104|1@1+ (1,0) [0|1] "" Vector__XXX
 SG_ Latitude_ : 72|32@1- (1E-007,0) [-90|90] "deg" Vector__XXX
 SG_ Longitude_ : 40|32@1- (1E-007,0) [-180|180] "deg" Vector__XXX
 SG_ UserID : 8|32@1+ (1,0) [0|4294967292] "" Vector__XXX
 SG_ RepeatIndicator : 6|2@1+ (1,0) [0|3] "" Vector__XXX
 SG_ MsgID : 0|6@1+ (1,0) [0|63] "" Vector__XXX

BO_ 2448953086 AISClassAPosReport: 27 Vector__XXX
 SG_ NavigationalStatus : 200|4@1+ (1,0) [0|15] "" Vector__XXX
 SG_ RateOfTurn : 184|16@1- (1,0) [-32768|32767] "rad/s" Vector__XXX
 SG_ TrueHeading : 168|16@1+ (0.0001,0) [0|6.28318] "rad" Vector__XXX
 SG_ AISTransceiverInformation : 163|5@1+ (1,0) [0|31] "" Vector__XXX
 SG_ CommunicationState : 144|19@1+ (1,0) [0|524287] "" Vector__XXX
 SG_ SOG : 128|16@1+ (0.01,0) [0|655.32] "m/s" Vector__XXX
 SG_ COG : 112|16@1+ (0.0001,0) [0|6.28318] "rad" Vector__XXX
 SG_ TimeStamp : 106|6@1+ (1,0) [0|63] "" Vector__XXX
 SG_ RAIMflag : 105|1@1+ (1,0) [0|1] "" Vector__XXX
 SG_ PosAccuracy : 104|1@1+ (1,0) [0|1] "" Vector__XXX
 SG_ Latitude_ : 72|32@1- (1E-007,0) [-90|90] "deg" Vector__XXX
 SG_ Longitude_ : 40|32@1- (1E-007,0) [-180|180] "deg" Vector__XXX
 SG_ UserID : 8|32@1+ (1,0) [0|4294967292] "" Vector__XXX
 SG_ RepeatIndicator : 6|2@1+ (1,0) [0|3] "" Vector__XXX
 SG_ MsgID : 0|6@1+ (1,0) [0|63] "" Vector__XXX

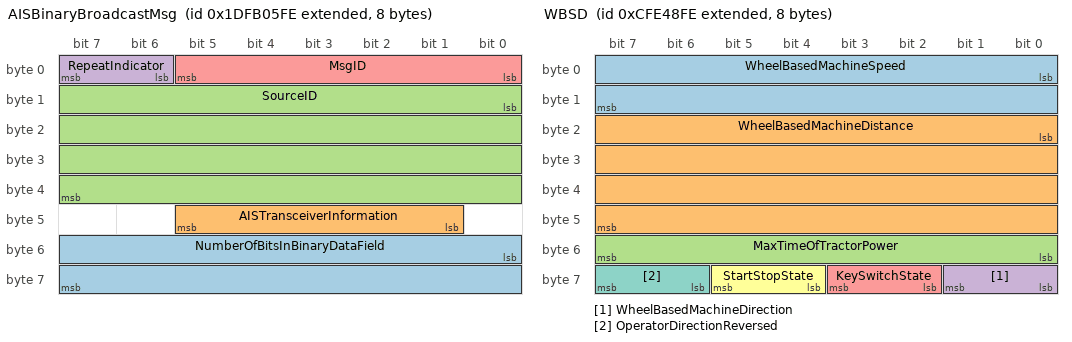
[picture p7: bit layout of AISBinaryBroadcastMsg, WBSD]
BO_ 2650473982 AISBinaryBroadcastMsg: 8 Vector__XXX
 SG_ NumberOfBitsInBinaryDataField : 48|16@1+ (1,0) [0|65532] "" Vector__XXX
 SG_ AISTransceiverInformation : 41|5@1+ (1,0) [0|31] "" Vector__XXX
 SG_ SourceID : 8|32@1+ (1,0) [0|4294967292] "" Vector__XXX
 SG_ RepeatIndicator : 6|2@1+ (1,0) [0|3] "" Vector__XXX
 SG_ MsgID : 0|6@1+ (1,0) [0|63] "" Vector__XXX

BO_ 2650475774 AISAssignmentModeCmd: 23 Vector__XXX
 SG_ IncrementB : 160|16@1+ (1,0) [0|65532] "" Vector__XXX
 SG_ OffsetB : 144|16@1+ (1,0) [0|65532] "" Vector__XXX
 SG_ DestinationIDB : 112|32@1+ (1,0) [0|4294967292] "" Vector__XXX
 SG_ IncrementA : 96|16@1+ (1,0) [0|65532] "" Vector__XXX
 SG_ OffsetA : 80|16@1+ (1,0) [0|65532] "" Vector__XXX
 SG_ DestinationIDA : 48|32@1+ (1,0) [0|4294967292] "" Vector__XXX
 SG_ AISTransceiverInformation : 41|5@1+ (1,0) [0|31] "" Vector__XXX
 SG_ SourceID : 8|32@1+ (1,0) [0|4294967292] "" Vector__XXX
 SG_ RepeatIndicator : 6|2@1+ (1,0) [0|3] "" Vector__XXX
 SG_ MsgID : 0|6@1+ (1,0) [0|63] "" Vector__XXX

BO_ 2650475006 AISAddressedSafetyRelatedMsg: 12 Vector__XXX
 SG_ SafetyRelatedText : 88|8@1+ (1,0) [0|255] "ASCII" Vector__XXX
 SG_ RetransmitFlag : 86|1@1+ (1,0) [0|1] "" Vector__XXX
 SG_ DestinationID : 48|32@1+ (1,0) [0|4294967292] "" Vector__XXX
 SG_ SequenceNumber_ : 46|2@1+ (1,0) [0|3] "" Vector__XXX
 SG_ AISTransceiverInformation : 41|5@1+ (1,0) [0|31] "" Vector__XXX
 SG_ SourceID : 8|32@1+ (1,0) [0|4294967292] "" Vector__XXX
 SG_ RepeatIndicator : 6|2@1+ (1,0) [0|3] "" Vector__XXX
 SG_ MsgID : 0|6@1+ (1,0) [0|63] "" Vector__XXX

BO_ 2650473470 AISAddressedBinaryMsg: 13 Vector__XXX
 SG_ NumberOfBitsInBinaryDataField : 88|16@1+ (1,0) [0|65532] "" Vector__XXX
 SG_ RetransmitFlag : 86|1@1+ (1,0) [0|1] "" Vector__XXX
 SG_ DestinationID : 48|32@1+ (1,0) [0|4294967292] "" Vector__XXX
 SG_ SequenceNumber_ : 46|2@1+ (1,0) [0|3] "" Vector__XXX
 SG_ AISTransceiverInformation : 41|5@1+ (1,0) [0|31] "" Vector__XXX
 SG_ SourceID : 8|32@1+ (1,0) [0|4294967292] "" Vector__XXX
 SG_ RepeatIndicator : 6|2@1+ (1,0) [0|3] "" Vector__XXX
 SG_ MsgID : 0|6@1+ (1,0) [0|63] "" Vector__XXX

BO_ 2650473726 AISAcknowledge: 12 Vector__XXX
 SG_ SequenceNumberForIDn : 94|2@1+ (1,0) [0|3] "" Vector__XXX
 SG_ SequenceNumberForID1 : 86|2@1+ (1,0) [0|3] "" Vector__XXX
 SG_ DestinationID1 : 48|32@1+ (1,0) [0|4294967292] "" Vector__XXX
 SG_ AISTransceiverInformation : 41|5@1+ (1,0) [0|31] "" Vector__XXX
 SG_ SourceID : 8|32@1+ (1,0) [0|4294967292] "" Vector__XXX
 SG_ RepeatIndicator : 6|2@1+ (1,0) [0|3] "" Vector__XXX
 SG_ MsgID : 0|6@1+ (1,0) [0|63] "" Vector__XXX

BO_ 2365475070 WBSD: 8 Vector__XXX
 SG_ WheelBasedMachineSpeed : 0|16@1+ (0.001,0) [0|64.255] "m/s" Vector__XXX
 SG_ WheelBasedMachineDistance : 16|32@1+ (0.001,0) [0|4211081.215] "m" Vector__XXX
 SG_ MaxTimeOfTractorPower : 48|8@1+ (1,0) [0|250] "min" Vector__XXX
 SG_ WheelBasedMachineDirection : 56|2@1+ (1,0) [0|3] "" Vector__XXX
 SG_ KeySwitchState : 58|2@1+ (1,0) [0|3] "" Vector__XXX
 SG_ StartStopState : 60|2@1+ (1,0) [0|4] "" Vector__XXX
 SG_ OperatorDirectionReversed : 62|2@1+ (1,0) [0|3] "" Vector__XXX

CM_ BO_ 2583299326 "GNSS information on current satellites in view tagged by sequence ID.Information includes PRN,elevation,azimuth,and SNR.Field 4 defines number of satellites.Fields 5 thru 11 define satellite number and information.These fields sequentially repeated for ea";
CM_ SG_ 2583299326 PRNStatusN "0   = Not Tracked,
  1   = Tracked but not used in solution,
  2   = Used in solution without Diff corrections,
  3   = Diff Corrections available,
  4   = Tracked with Diff Corrections,
  5   = used with Diff Corrections,
6-13 =Reserved,
14    = E";
CM_ SG_ 2583299326 AzimuthN "Degrees clockwise relative to True North.";
CM_ SG_ 2583299326 ElevationN "Angle above or below the horizon. -90° to +90°; negative below the horizon";
CM_ SG_ 2583299326 PRNN "0 = value not used,
  1-32 = GPS,
33-64 = SBAS,Satellite,Based Augmentation System(ie WAAS)
65-96 = GLONASS.
For GLONASS,satellites are identified by 64+satellite slot number.slot numbers are 1 through 24 for full GLONASS constellation of 24 satellite";
CM_ SG_ 2583299326 PRNStatus1 "0   = Not Tracked,
  1   = Tracked but not used in solution,
  2   = Used in solution without Diff corrections,
  3   = Diff Corrections available,
  4   = Tracked with Diff Corrections,
  5   = used with Diff Corrections,
6-13 =Reserved,
14    = E";
CM_ SG_ 2583299326 Azimuth1 "Degrees clockwise relative to True North.";
CM_ SG_ 2583299326 Elevation1 "Angle above or below the horizon. -90° to +90°; negative below the horizon";
CM_ SG_ 2583299326 PRN1 "0 = value not used,
  1-32 = GPS,
33-64 = SBAS,Satellite,Based Augmentation System(ie WAAS)
65-96 = GLONASS.
For GLONASS,satellites are identified by 64+satellite slot number.slot numbers are 1 through 24 for full GLONASS constellation of 24 satellite";
CM_ SG_ 2583299326 NumberOfSVs_ "Numeric count, event counter, sequence counter";
CM_ SG_ 2583299326 SID "An upward counting number used to tie related information together between different PGNs.For example,SID would be used to tie together COG,SOG and RAIM values to a given Pos.255=no valid Pos fix to tie it to.Range 0 to 250 for valid Pos fixes.";
CM_ BO_ 2583300862 "This PGN is used to report the control parameters for a GNSS Receiver Autonomous Integrity Monitoring (RAIM) process.  The Command Group Function PGN 126208 provides the means to set these values over the network.";
CM_ SG_ 2583300862 RadialPosErrorMaxThreshold "Error distances expressed in meters.";
CM_ BO_ 2583300606 "This PGN is used to provide the output from a GNSS Receiver's Receiver Autonomous Integrity Monitoring (RAIM) process.  The Integrity field value is based upon the parameters set in PGN 130059 GNS RAIM Settings.";
CM_ SG_ 2583300606 SVIDOfMostLikelyFailedSat "0 = value not used,
  1-32 = GPS,
33-64 = SBAS,Satellite,Based Augmentation System(ie WAAS)
65-96 = GLONASS.
For GLONASS,satellites are identified by 64+satellite slot number.slot numbers are 1 through 24 for full GLONASS constellation of 24 satellite";
CM_ SG_ 2583300606 IntegrityFlag "0 = No Integrity checking,*
1 = Safe,
2 = Caution,
3 = Unsafe
  * means the receiver does not have this capability";
CM_ SG_ 2583300606 SequenceID_ "An upward counting number used to tie related information together between different PGNs.For example,SID would be used to tie together COG,SOG and RAIM values to a given Pos.255=no valid Pos fix to tie it to.Range 0 to 250 for valid Pos fixes.";
CM_ BO_ 2583299838 "GNSS pseudorange measurement noise statistics can be translated in the position domain in order to give statistical measures of the quality of the position solution. Intended for use with a Receiver Autonomous Integrity Monitoring (RAIM) application.";
CM_ SG_ 2583299838 STDOfAltError "Error distances expressed in meters.";
CM_ SG_ 2583299838 STDOfLonError "Error distances expressed in meters.";
CM_ SG_ 2583299838 STDOfLatError "Error distances expressed in meters.";
CM_ SG_ 2583299838 OrientationOfMajorAxis "Degrees clockwise relative to True North.";
CM_ SG_ 2583299838 STDOfMinorAxis "Error distances expressed in meters.";
CM_ SG_ 2583299838 STDOfMajorAxis "Error distances expressed in meters.";
CM_ SG_ 2583299838 RMSOfPosUncertainty "Error distances expressed in meters.";
CM_ SG_ 2583299838 SID "An upward counting number used to tie related information together between different PGNs.For example,SID would be used to tie together COG,SOG and RAIM values to a given Pos.255=no valid Pos fix to tie it to.Range 0 to 250 for valid Pos fixes.";
CM_ BO_ 2583301118 "This parameter group is used to support Receiver Autononmous Integrity Monitoring (RAIM).  Pseudorange measurement error statistics can be translated in the position domain in order to give statistical measures of the quality of the position solution.";
CM_ SG_ 2583301118 OrientationOfErrorEllipse "Degrees clockwise relative to True North.";
CM_ SG_ 2583301118 SequenceID_ "An upward counting number used to tie related information together between different PGNs.For example,SID would be used to tie together COG,SOG and RAIM values to a given Pos.255=no valid Pos fix to tie it to.Range 0 to 250 for valid Pos fixes.";
CM_ BO_ 2381841918 "This PGN conveys a comprehensive set of Global Navigation Satellite System (GNSS) parameters, including position information.  Equipment transmitting this PGN would typically also transmit PGN 129025 (Position – Rapid Update).";
CM_ SG_ 2381841918 AgeOfDGNSSReferenceStationN "Age of Differential corrections";
CM_ SG_ 2381841918 ReferenceStationIDN "Reference Station ID.  Reference Station number as provided by the Service Provider.[Reference document required]";
CM_ SG_ 2381841918 ReferenceStationTypeN "Reference Station Type. 
0x0=GPS; 
0x1=GLONASS; 
0x3 to 0xD=Reserved; 
0XE=Error; 
0XF=Null";
CM_ SG_ 2381841918 AgeOfDGNSSCorrections1_ "Age of Differential corrections";
CM_ SG_ 2381841918 ReferenceStationID1_ "Reference Station ID.  Reference Station number as provided by the Service Provider.[Reference document required]";
CM_ SG_ 2381841918 ReferenceStationType1 "Reference Station Type. 
0x0=GPS; 
0x1=GLONASS; 
0x3 to 0xD=Reserved; 
0XE=Error; 
0XF=Null";
CM_ SG_ 2381841918 NumberOfReferenceStations_ "Numeric count, event counter, sequence counter";
CM_ SG_ 2381841918 GeoidalSeparation_ "The difference between the earth ellipsoid and mean-sea-level (geoid) defined by the reference datum used in the position solution, '-' = mean-sea-level below ellipsoid.  Reference datum is defined in this packet.";
CM_ SG_ 2381841918 PDOP_ "Dilution of Precision(DOP)indicates contribution of satellite Config geometry to Posing error.A lower DOP value is preferred because less error is being introduced.Reported as components:HDOP(Horizontal),VDOP(Vertical),TDOP(Time).Min DOP value is 1.0(no e";
CM_ SG_ 2381841918 HDOP_ "Dilution of Precision(DOP)indicates contribution of satellite Config geometry to Posing error.A lower DOP value is preferred because less error is being introduced.Reported as components:HDOP(Horizontal),VDOP(Vertical),TDOP(Time).Min DOP value is 1.0(no e";
CM_ SG_ 2381841918 NumberOfSVs_ "Numeric count, event counter, sequence counter";
CM_ SG_ 2381841918 Integrity "0 = No Integrity checking,*
1 = Safe,
2 = Caution,
3 = Unsafe
  * means the receiver does not have this capability";
CM_ SG_ 2381841918 MethodGNSS "0 = no GPS,
1 = GNSS fix,
2 = DGNSS fix,
3 = Precise GNSS*,
4 = RTK Fixed Integer,
5 = RTK Float,
6 = Est(DR)mode,
7 = Manual Input,
8 = Simulate mode,
9-13 = Reserved,
14 = Error,
15 = Null.*Precise GNSS means no deliberate degradation(such as";
CM_ SG_ 2381841918 TypeOfSystem_ "0x00 = GPS
0x01 = GLONASS
0x02 = GPS+GLONASS
0x03 = GPS+SBAS(WAAS)
0x04 = GPS+SBAS+GLONASS
0x05 - 0x15 = Reserved for future combinations";
CM_ SG_ 2381841918 PosTime "24 hour clock, 0 =  midnight,  time is in UTC";
CM_ SG_ 2381841918 PosDate "Days since January 1, 1970,   Date is relative to UTC Time.";
CM_ SG_ 2381841918 SID "An upward counting number used to tie related information together between different PGNs.For example,SID would be used to tie together COG,SOG and RAIM values to a given Pos.255=no valid Pos fix to tie it to.Range 0 to 250 for valid Pos fixes.";
CM_ BO_ 2583301886 "GNSS common differential correction receiver parameter status.";
CM_ SG_ 2583301886 DiffOperationMode "0  = Manual, 
  1  = Auto Power, 
  2  = Auto Range, 
3-13 = Reserved, 
 14 = Error, 
 15 = No Selection";
CM_ SG_ 2583301886 DiffSource "0  = Auto Select,
  1 = Loran Communications 
  2  = MSK Beacon,
  3  = FM Subcarrier,
  4  = AIS(Automatic Identification System),
  5  = Other Ground-based Radio,
  6  = SBAS(Satellite Based Augmentation System,
  7  = Other Satellite,
8-13 = Re";
CM_ SG_ 2583301886 SerialInterfaceDetectionMode "This is the mode of operation for the correction receiver.  
0 = Auto bit rate set, 
1 = Manual bit rate set,  
2-5  = Reserved
6 = Error, 
7 = Null.";
CM_ SG_ 2583301886 SerialInterfaceBitRate "This is bit rate of correction receiver.
 0 = 25bps,
 1 = 50bps,
 2 = 100bps,
 3 = 200bps,
 4 = 300bps,
 5 = 500bps,
 6 = 1200bps,
 7 = 2400bps,
 8 = 4800bps,
 9 = 9600bps
10 = 19200bps,
11 = 38400bps,
12 = 57600bps,
13-29 = Reserved,
30 = ";
CM_ SG_ 2583301886 Frequency "This is the input frequency of the correction receiver.";
CM_ SG_ 2583301886 Channel "The channel number of the correction receiver.  If the receiver only has one beacon input channel, this value shall be 1; 0 is undefined.";
CM_ BO_ 2583302142 "GNSS differential correction receiver status tagged by sequence ID. Status information includes frequency, SNR, and use as a correction source.";
CM_ SG_ 2583302142 SatelliteServiceIDNo "Satellite Service ID number as provided by the Service Provider.[Reference document required]";
CM_ SG_ 2583302142 TimeSinceLastSatDiffSync "Age of Differential corrections";
CM_ SG_ 2583302142 DiffSource "0  = Auto Select,
  1 = Loran Communications 
  2  = MSK Beacon,
  3  = FM Subcarrier,
  4  = AIS(Automatic Identification System),
  5  = Other Ground-based Radio,
  6  = SBAS(Satellite Based Augmentation System,
  7  = Other Satellite,
8-13 = Re";
CM_ SG_ 2583302142 UsedAsCorrectionSource "MSB/LSB: 
00 = [No, Off, Disabled, Reset, '0'], 
01 = [Yes, On, Enabled, Set, '1'], 
10 = Error, 
11= [Unavailable, Unknown]";
CM_ SG_ 2583302142 DiffSignalDetectionMode "This is the mode of operation for the correction receiver.  
0 = Auto bit rate set, 
1 = Manual bit rate set,  
2-5  = Reserved
6 = Error, 
7 = Null.";
CM_ SG_ 2583302142 DiffSignalBitRate "This is bit rate of correction receiver.
 0 = 25bps,
 1 = 50bps,
 2 = 100bps,
 3 = 200bps,
 4 = 300bps,
 5 = 500bps,
 6 = 1200bps,
 7 = 2400bps,
 8 = 4800bps,
 9 = 9600bps
10 = 19200bps,
11 = 38400bps,
12 = 57600bps,
13-29 = Reserved,
30 = ";
CM_ SG_ 2583302142 StationID "Reference Station ID.  Reference Station number as provided by the Service Provider.[Reference document required]";
CM_ SG_ 2583302142 StationType "Reference Station Type. 
0x0=GPS; 
0x1=GLONASS; 
0x3 to 0xD=Reserved; 
0XE=Error; 
0XF=Null";
CM_ SG_ 2583302142 Frequency "This is the input frequency of the correction receiver.";
CM_ SG_ 2583302142 SignalStrength "This is the signal strength expressed in dB with respect to 1uV/m.";
CM_ SG_ 2583302142 Channel "The channel number of the correction receiver.  If the receiver only has one beacon input channel, this value shall be 1; 0 is undefined.";
CM_ SG_ 2583302142 SID "An upward counting number used to tie related information together between different PGNs.For example,SID would be used to tie together COG,SOG and RAIM values to a given Pos.255=no valid Pos fix to tie it to.Range 0 to 250 for valid Pos fixes.";
CM_ BO_ 2583299070 "This PGN provides a single Trans containing GNSS status and dilution of precision components(DOP)that indicate contribution of satellite geometry to overall Posing error.There are three DOP parameters reported,horizontal(HDOP),Vertical(VDOP)and time(TDOP)";
CM_ SG_ 2583299070 TDOP "Dilution of Precision(DOP)indicates contribution of satellite Config geometry to Posing error.A lower DOP value is preferred because less error is being introduced.Reported as components:HDOP(Horizontal),VDOP(Vertical),TDOP(Time).Min DOP value is 1.0(no e";
CM_ SG_ 2583299070 VDOP "Dilution of Precision(DOP)indicates contribution of satellite Config geometry to Posing error.A lower DOP value is preferred because less error is being introduced.Reported as components:HDOP(Horizontal),VDOP(Vertical),TDOP(Time).Min DOP value is 1.0(no e";
CM_ SG_ 2583299070 HDOP_ "Dilution of Precision(DOP)indicates contribution of satellite Config geometry to Posing error.A lower DOP value is preferred because less error is being introduced.Reported as components:HDOP(Horizontal),VDOP(Vertical),TDOP(Time).Min DOP value is 1.0(no e";
CM_ SG_ 2583299070 OpMode "0 = 1D, 
 1 = 2D, 
 2 = 3D, 
 3 = Auto, 
4-5 = Reserved, 
 6 = Error, 
 7 = Null";
CM_ SG_ 2583299070 SetMode "0 = 1D, 
 1 = 2D, 
 2 = 3D, 
 3 = Auto, 
4-5 = Reserved, 
 6 = Error, 
 7 = Null";
CM_ SG_ 2583299070 SID "An upward counting number used to tie related information together between different PGNs.For example,SID would be used to tie together COG,SOG and RAIM values to a given Pos.255=no valid Pos fix to tie it to.Range 0 to 250 for valid Pos fixes.";
CM_ BO_ 2583298814 "GNSS common satellite receiver parameter status";
CM_ SG_ 2583298814 UseAntennaAltitudeFor2DMode "MSB/LSB: 
00 = [No, Off, Disabled, Reset, '0'], 
01 = [Yes, On, Enabled, Set, '1'], 
10 = Error, 
11= [Unavailable, Unknown]";
CM_ SG_ 2583298814 MaxCorrectionAge "Age of Differential corrections";
CM_ SG_ 2583298814 Pos_VelocityFilter "MSB/LSB: 
00 = [No, Off, Disabled, Reset, '0'], 
01 = [Yes, On, Enabled, Set, '1'], 
10 = Error, 
11= [Unavailable, Unknown]";
CM_ SG_ 2583298814 DGNSSMode "0 = Off,
1 = Auto,
2 = RTCM SC104 Pseudorange Corrections,
3 = RTCA SC159 Network Corrections,
4 = RTK Differential Corrections,
5 = Reserved,
6 = Error; 
7 = Null";
CM_ SG_ 2583298814 GNSSMode "0 = 1D, 
 1 = 2D, 
 2 = 3D, 
 3 = Auto, 
4-5 = Reserved, 
 6 = Error, 
 7 = Null";
CM_ SG_ 2583298814 PDOPSwitch "Dilution of Precision(DOP)indicates contribution of satellite Config geometry to Posing error.A lower DOP value is preferred because less error is being introduced.Reported as components:HDOP(Horizontal),VDOP(Vertical),TDOP(Time).Min DOP value is 1.0(no e";
CM_ SG_ 2583298814 PDOPMask "Dilution of Precision(DOP)indicates contribution of satellite Config geometry to Posing error.A lower DOP value is preferred because less error is being introduced.Reported as components:HDOP(Horizontal),VDOP(Vertical),TDOP(Time).Min DOP value is 1.0(no e";
CM_ SG_ 2583298814 SVElevationMask "Angle above or below the horizon. -90° to +90°; negative below the horizon";
CM_ BO_ 2583303422 "This PGN provides a single Trans that contains relevant almanac data for Glonass products.almanac contains satellite vehicle coursebital parameters.This information is not considered precise and is only valid for several months at a time.Glonass products ";
CM_ SG_ 2583303422 tnA2 "Course value of the time scale shift, reference GLONASS ICD Section 4.5 Table 4.3 (fill unused bits with zeros).";
CM_ SG_ 2583303422 tcA "System time scale correction, reference GLONASS ICD Section 4.5 Table 4.3 (fill unused bits with zeros).";
CM_ SG_ 2583303422 inA "Correction to the average value of the inclination angle, reference GLONASS ICD Section 4.5 Table 4.3 (fill unused bits with zeros).";
CM_ SG_ 2583303422 nA3 "Greenwich longitude of the ascension node, reference GLONASS ICD Section 4.5 Table 4.3 (fill unused bits with zeros).";
CM_ SG_ 2583303422 tnA "Time of the ascension node, almanac reference time, reference GLONASS ICD Section 4.5 Table 4.3 (fill unused bits with zeros).";
CM_ SG_ 2583303422 TnA "Correction to the average value of the draconitic circling time, reference GLONASS ICD Section 4.5 Table 4.3 (fill unused bits with zeros).";
CM_ SG_ 2583303422 nA2 "Argument of Perigee, reference GLONASS ICD Section 4.5 Table 4.3 (fill unused bits with zeros).";
CM_ SG_ 2583303422 DOT "Rate of change of the draconitic circling time, reference GLONASS ICD Section 4.5 Table 4.3 (fill unused bits with zeros).";
CM_ SG_ 2583303422 nA "Eccentricity, reference GLONASS ICD Section 4.5 Table 4.3 (fill unused bits with zeros).";
CM_ SG_ 2583303422 HnA "Carrier frequency number respectively, reference GLONASS ICD.";
CM_ SG_ 2583303422 CnA "Generalized health of the Satellite, reference GLONASS ICD.";
CM_ SG_ 2583303422 NA "Calendar day count within the four year period beginning with the previous leap year";
CM_ SG_ 2583303422 PRN "0 = value not used,
  1-32 = GPS,
33-64 = SBAS,Satellite,Based Augmentation System(ie WAAS)
65-96 = GLONASS.
For GLONASS,satellites are identified by 64+satellite slot number.slot numbers are 1 through 24 for full GLONASS constellation of 24 satellite";
CM_ BO_ 2582778366 "Fluid Level contains an instance number, type of fluid, level of fluid, and tank capacity.  For example the fluid instance may be the level of fuel in a tank or the level of water in the bilge.  Used primarily by display or instrumentation devices.";
CM_ SG_ 2582778366 FluidType "0x00 = Fuel,
0x01 = Fresh Water,
0x02 = Waste Water,
0x03 = Live Well,
0x04 = Oil, 
0x05 = Black Water (Sewage)
0x06 = Reserved,
  thru
0x0D = Reserved,
0x0E = Error, 
0x0F = Data not available";
CM_ SG_ 2582778366 FluidInstance "0x0 to 0xF = Instance number 0 to 15;";
CM_ BO_ 2516387838 "Environmental Conditions contains Temperature, Humidity, and Atmospheric Pressure.  This PGN is a rework of PGN 130310 and is to be used for new designs.";
CM_ SG_ 2516387838 HumidityInstance "0x00 = Inside Humidity,
0x01 = Outside Humidity,
0x02 = reserved,
0x03 = Data Not Available";
CM_ SG_ 2516387838 TempInstance "0x00 = Sea Temperature,
0x01 = Outside Temperature,
0x02 = Inside Temperature,
0x03 = Engine Room Temperature,
0x04 = Main Cabin Temperature,
0x05 = Reserve,
 thru
0x3E = Reserve,
0x3F = Data Not Available";
CM_ SG_ 2516387838 SequenceID_ "An upward counting number used to tie related information together between different PGNs.For example,SID would be used to tie together COG,SOG and RAIM values to a given Pos.255=no valid Pos fix to tie it to.Range 0 to 250 for valid Pos fixes.";
CM_ BO_ 2516387582 "Local atmospheric environmental conditions";
CM_ SG_ 2516387582 SequenceID_ "An upward counting number used to tie related information together between different PGNs.For example,SID would be used to tie together COG,SOG and RAIM values to a given Pos.255=no valid Pos fix to tie it to.Range 0 to 250 for valid Pos fixes.";
CM_ BO_ 2515667710 "Provides identification information and rated engine speed for the engine indicated by the engine instance field. Used primarily by display devices.";
CM_ SG_ 2515667710 VIN "Name of place, route, waypoint, destination, vessel, vehicle, etc.";
CM_ SG_ 2515667710 EngInstance "For Engs:
0 = Instance 0;          0 = Single Eng Dual Eng Port
1 = Instance 1;          1 = Dual Eng StarBoard  
                                  (for Multiple Engs,Instances will start 
        thru                            from Bow,Port(0)to Ste";
CM_ BO_ 2314338558 "Provides data with a high update rate for a specific engine in a single frame message.  The first field provides information as to which engine.  This PGN if  used with PGN 127489 will provide most Engine data.";
CM_ SG_ 2314338558 EngInstance "For Engs:
0 = Instance 0;          0 = Single Eng Dual Eng Port
1 = Instance 1;          1 = Dual Eng StarBoard  
                                  (for Multiple Engs,Instances will start 
        thru                            from Bow,Port(0)to Ste";
CM_ BO_ 2314338814 "Used to provide real-time operational data and status relevant to a specific engine,  indicated by the engine instance field.  This message would normally be broadcasted periodically to provide information for instrumentation or control functions.";
CM_ SG_ 2314338814 EngDiscreteStatus2 "xxxx xxxx xxxx xxx1 = Warning Level 1,
xxxx xxxx xxxx xx1x = Warning Level 2,
xxxx xxxx xxxx x1xx = Power Reduction,
xxxx xxxx xxxx 1xxx = Maintenance Needed,
xxxx xxxx xxx1 xxxx = Eng Comm Error,
xxxx xxxx xx1x xxxx = Sub Second Throttle,
xxxx xxxx";
CM_ SG_ 2314338814 EngDiscreteStatus1 "xxxx xxxx  xxxx xxx1 = Check Eng,
xxxx xxxx  xxxx xx1x = Over Temp,
xxxx xxxx  xxxx x1xx = Low Oil Press,
xxxx xxxx  xxxx 1xxx = Low Oil Level,
xxxx xxxx  xxx1 xxxx = Low Fuel Press,
xxxx xxxx  xx1x xxxx = Low System Voltage,
xxxx xxxx  x1xx xxxx = ";
CM_ SG_ 2314338814 EngInstance "For Engs:
0 = Instance 0;          0 = Single Eng Dual Eng Port
1 = Instance 1;          1 = Dual Eng StarBoard  
                                  (for Multiple Engs,Instances will start 
        thru                            from Bow,Port(0)to Ste";
CM_ BO_ 2582975486 "This PGN provides cumulative voyage distance traveled since last reset.distance is tagged with time and date of distance measurement.distances through water are accumulated and values stored during power down and resume counting after power up.
  
-Tota";
CM_ SG_ 2582975486 MeasurementTime "24 hour clock, 0 =  midnight,  time is in UTC";
CM_ SG_ 2582975486 MeasurementDate "Days since January 1, 1970,   Date is relative to UTC Time.";
CM_ BO_ 2382238206 "purpose of this PGN is to group three fundamental vectors related to vessel motion,

-Speed and heading referenced to water
-Speed and course referenced to ground
-Current speed and flow direction

Products that are primary form of navigation would ";
CM_ SG_ 2382238206 Set "Direction towards which current flows.  Degrees relative to True North.";
CM_ SG_ 2382238206 Heading "The horizontal direction in which a ship actually points or heads at any instant, expressed in angular units from a reference direction, usually from 000 at the reference direction clockwise through 359 degrees.";
CM_ SG_ 2382238206 CourseOverGround "The direction of the path over ground actually followed by a vessel.";
CM_ SG_ 2382238206 SID "An upward counting number used to tie related information together between different PGNs.For example,SID would be used to tie together COG,SOG and RAIM values to a given Pos.255=no valid Pos fix to tie it to.Range 0 to 250 for valid Pos fixes.";
CM_ SG_ 2382238206 Set_COG_HeadingRef "0 = True, 
1 = Magnetic, 
2 = Error, 
3 = Null";
CM_ SG_ 2382238206 DataMode "0x0 = Autonomous mode, 
0x1 = Differential, enhanced mode, 
0x2 = Estimated mode, 
0x3 = Simulator mode, 
0x4 = Manual mode, 
0xE = Error, 
0xF = Data not available";
CM_ BO_ 2583172350 "Local geodetic datum and datum offsets from a reference datum. This PGN is used to define the datum to which a position location output by the same device in other PGNs is referenced.";
CM_ SG_ 2583172350 LocalDatum "4-character code for datum currently being output for Pos solution.datum's are defined in IHO Publication S-60,Appendices B and C.first three chars are datum ID as per IHO tables.fourth char is local datum subdivision code.A null char indicates datum subd";
CM_ BO_ 2449150206 "This PGN provides Digital Selective Calling(DSC)data according to ITU M.493-9 with optional expansion according to ITU M.821-1.
DSC is a paging system that is used to automate distress alerts sent over terrestrial communication systems such as VHF,MF and";
CM_ SG_ 2449150206 DSCMsgAddress "Individual characters having only decimal values in range 0 to 127 for DSC symbols defined by ITU-R M.493 are used to code address geographic area as defined in ITU-R M.493-9 Section 5.This may represent an individual MMSI,a group MMSI,or a geographic are";
CM_ SG_ 2449150206 DSCCategorySymbol "Integer numbers within the range 000 to 127 representing DSC Symbols defined by ITU-R M.493 Table 3 for: Phasing and Unique Functions; Format Specifier; Category; Nature of Distress; First Telecommand; Second Telecommand";
CM_ SG_ 2449150206 DSCFormatSymbol "Integer numbers within the range 000 to 127 representing DSC Symbols defined by ITU-R M.493 Table 3 for: Phasing and Unique Functions; Format Specifier; Category; Nature of Distress; First Telecommand; Second Telecommand";
CM_ BO_ 2583301630 "This PGN provides a means to pass Diff GNSS corrections between NMEA 2000 devices.Passing DGNSS data this way allows for more flexibility than traditional methods.One Diff correction receiver could supply multiple GNSS receivers.Multiple Diff correction r";
CM_ SG_ 2583301630 IOD "Number of route, waypoint, event, mark, etc.";
CM_ SG_ 2583301630 UDRE "Dependent upon PG Field definition.";
CM_ SG_ 2583301630 SatelliteID "0 = value not used,
  1-32 = GPS,
33-64 = SBAS,Satellite,Based Augmentation System(ie WAAS)
65-96 = GLONASS.
For GLONASS,satellites are identified by 64+satellite slot number.slot numbers are 1 through 24 for full GLONASS constellation of 24 satellite";
CM_ SG_ 2583301630 StationHealth "0x00 = Not Working,
0x01 = Unmonitored,
0x02 = Healthy & Operational,
0x03 = Healthy & in Test Mode,
0x04 = In Test Mode - DO NOT USE,
0x05 - 0x15 = Reserved";
CM_ SG_ 2583301630 ReferenceStationType "Reference Station Type. 
0x0=GPS; 
0x1=GLONASS; 
0x3 to 0xD=Reserved; 
0XE=Error; 
0XF=Null";
CM_ SG_ 2583301630 ReferenceStationID "Reference Station ID.  Reference Station number as provided by the Service Provider.[Reference document required]";
CM_ SG_ 2583301630 SequenceID_ "An upward counting number used to tie related information together between different PGNs.For example,SID would be used to tie together COG,SOG and RAIM values to a given Pos.255=no valid Pos fix to tie it to.Range 0 to 250 for valid Pos fixes.";
CM_ BO_ 2583499518 "Current station measurement data including station location, numeric identifier, and name.";
CM_ SG_ 2583499518 StationIDString "Name of place, route, waypoint, destination, vessel, vehicle, etc.";
CM_ SG_ 2583499518 CurrentFlowDirection "Direction towards which current flows.  Degrees relative to True North.";
CM_ SG_ 2583499518 MeasurementDepth "Water depth measured from the water surface";
CM_ SG_ 2583499518 MeasurementTime "24 hour clock, 0 =  midnight,  time is in UTC";
CM_ SG_ 2583499518 MeasurementDate "Days since January 1, 1970,   Date is relative to UTC Time.";
CM_ SG_ 2583499518 State "000 = Flood, 
001 = Slack, 
010 = Ebb, 
011 = Reserved, 
100 = Reserved, 
101 = Reserved, 
110 = Error, 
111 = Unavailable, Unknown";
CM_ SG_ 2583499518 Mode "Range Residual used in position calculation or range residuals were calculated after the position.  
0=range residuals were used to calculate data; 
1=range residuals were calculated after the position., 
2=Error, 
3=Null";
CM_ BO_ 2381906942 "This PGN provides the magnitude of position error perpendicular to the desired course.";
CM_ SG_ 2381906942 XTE "Cross-track-error of a route.  '-' = Left of track, need to steer right";
CM_ SG_ 2381906942 NavigationTerminated "MSB/LSB: 
00 = [No, Off, Disabled, Reset, '0'], 
01 = [Yes, On, Enabled, Set, '1'], 
10 = Error, 
11= [Unavailable, Unknown]";
CM_ SG_ 2381906942 XTEMode "0x0 = Autonomous mode, 
0x1 = Differential, enhanced mode, 
0x2 = Estimated mode, 
0x3 = Simulator mode, 
0x4 = Manual mode, 
0xE = Error, 
0xF = Data not available";
CM_ SG_ 2381906942 SID "An upward counting number used to tie related information together between different PGNs.For example,SID would be used to tie together COG,SOG and RAIM values to a given Pos.255=no valid Pos fix to tie it to.Range 0 to 250 for valid Pos fixes.";
CM_ BO_ 2582648574 "Free-form alphanumeric fields describing the installation  (e.g., starboard engine room location) of the device and installation notes (e.g., calibration data)";
CM_ SG_ 2582648574 InstallationDescriptionField1 "Name of place, route, waypoint, destination, vessel, vehicle, etc.";
CM_ BO_ 2583238398 "Bearing and distance from the origin mark to the destination mark, calculated at the origin mark, for any two arbitrary generic marks. The calculation type (Rhumb Line, Great Circle) is specified, as well as the bearing reference (Mag, True).";
CM_ SG_ 2583238398 DestinationMarkID "Number of route, waypoint, event, mark, etc.";
CM_ SG_ 2583238398 OriginMarkId "Number of route, waypoint, event, mark, etc.";
CM_ SG_ 2583238398 DestinationMarkType "0   = Collision, 
  1   = Turning Point, 
  2   = Reference (general), 
  3   = Wheelover, 
  4   = Waypoint, 
5-13 = Reserved, 
 14  = Error, 
 15  = Null";
CM_ SG_ 2583238398 OriginMarkType "0   = Collision, 
  1   = Turning Point, 
  2   = Reference (general), 
  3   = Wheelover, 
  4   = Waypoint, 
5-13 = Reserved, 
 14  = Error, 
 15  = Null";
CM_ SG_ 2583238398 BearingiginToDestination "The horizontal direction of one terrestrial point from another, expressed as the angular distance from a reference direction, measured from 000 at the reference direction clockwise through 359 degrees.";
CM_ SG_ 2583238398 CalculationType "0 = Great Circle calculations, 
1 = Rhumb Line calculations, 
2 = Error, 
3 = Null";
CM_ SG_ 2583238398 BearingRef "0 = True, 
1 = Magnetic, 
2 = Error, 
3 = Null";
CM_ SG_ 2583238398 SID "An upward counting number used to tie related information together between different PGNs.For example,SID would be used to tie together COG,SOG and RAIM values to a given Pos.255=no valid Pos fix to tie it to.Range 0 to 250 for valid Pos fixes.";
CM_ BO_ 2381450750 "Universal status report for multiple banks of two-state indicators.";
CM_ SG_ 2381450750 Indic28 "MSB/LSB: 
00 = [No, Off, Disabled, Reset, '0'], 
01 = [Yes, On, Enabled, Set, '1'], 
10 = Error, 
11= [Unavailable, Unknown]";
CM_ SG_ 2381450750 Indic27 "MSB/LSB: 
00 = [No, Off, Disabled, Reset, '0'], 
01 = [Yes, On, Enabled, Set, '1'], 
10 = Error, 
11= [Unavailable, Unknown]";
CM_ SG_ 2381450750 Indic26 "MSB/LSB: 
00 = [No, Off, Disabled, Reset, '0'], 
01 = [Yes, On, Enabled, Set, '1'], 
10 = Error, 
11= [Unavailable, Unknown]";
CM_ SG_ 2381450750 Indic25 "MSB/LSB: 
00 = [No, Off, Disabled, Reset, '0'], 
01 = [Yes, On, Enabled, Set, '1'], 
10 = Error, 
11= [Unavailable, Unknown]";
CM_ SG_ 2381450750 Indic24 "MSB/LSB: 
00 = [No, Off, Disabled, Reset, '0'], 
01 = [Yes, On, Enabled, Set, '1'], 
10 = Error, 
11= [Unavailable, Unknown]";
CM_ SG_ 2381450750 Indic23 "MSB/LSB: 
00 = [No, Off, Disabled, Reset, '0'], 
01 = [Yes, On, Enabled, Set, '1'], 
10 = Error, 
11= [Unavailable, Unknown]";
CM_ SG_ 2381450750 Indic22 "MSB/LSB: 
00 = [No, Off, Disabled, Reset, '0'], 
01 = [Yes, On, Enabled, Set, '1'], 
10 = Error, 
11= [Unavailable, Unknown]";
CM_ SG_ 2381450750 Indic21 "MSB/LSB: 
00 = [No, Off, Disabled, Reset, '0'], 
01 = [Yes, On, Enabled, Set, '1'], 
10 = Error, 
11= [Unavailable, Unknown]";
CM_ SG_ 2381450750 Indic20 "MSB/LSB: 
00 = [No, Off, Disabled, Reset, '0'], 
01 = [Yes, On, Enabled, Set, '1'], 
10 = Error, 
11= [Unavailable, Unknown]";
CM_ SG_ 2381450750 Indic19 "MSB/LSB: 
00 = [No, Off, Disabled, Reset, '0'], 
01 = [Yes, On, Enabled, Set, '1'], 
10 = Error, 
11= [Unavailable, Unknown]";
CM_ SG_ 2381450750 Indic18 "MSB/LSB: 
00 = [No, Off, Disabled, Reset, '0'], 
01 = [Yes, On, Enabled, Set, '1'], 
10 = Error, 
11= [Unavailable, Unknown]";
CM_ SG_ 2381450750 Indic17 "MSB/LSB: 
00 = [No, Off, Disabled, Reset, '0'], 
01 = [Yes, On, Enabled, Set, '1'], 
10 = Error, 
11= [Unavailable, Unknown]";
CM_ SG_ 2381450750 Indic16 "MSB/LSB: 
00 = [No, Off, Disabled, Reset, '0'], 
01 = [Yes, On, Enabled, Set, '1'], 
10 = Error, 
11= [Unavailable, Unknown]";
CM_ SG_ 2381450750 Indic15 "MSB/LSB: 
00 = [No, Off, Disabled, Reset, '0'], 
01 = [Yes, On, Enabled, Set, '1'], 
10 = Error, 
11= [Unavailable, Unknown]";
CM_ SG_ 2381450750 Indic14 "MSB/LSB: 
00 = [No, Off, Disabled, Reset, '0'], 
01 = [Yes, On, Enabled, Set, '1'], 
10 = Error, 
11= [Unavailable, Unknown]";
CM_ SG_ 2381450750 Indic13 "MSB/LSB: 
00 = [No, Off, Disabled, Reset, '0'], 
01 = [Yes, On, Enabled, Set, '1'], 
10 = Error, 
11= [Unavailable, Unknown]";
CM_ SG_ 2381450750 Indic12 "MSB/LSB: 
00 = [No, Off, Disabled, Reset, '0'], 
01 = [Yes, On, Enabled, Set, '1'], 
10 = Error, 
11= [Unavailable, Unknown]";
CM_ SG_ 2381450750 Indic11 "MSB/LSB: 
00 = [No, Off, Disabled, Reset, '0'], 
01 = [Yes, On, Enabled, Set, '1'], 
10 = Error, 
11= [Unavailable, Unknown]";
CM_ SG_ 2381450750 Indic10 "MSB/LSB: 
00 = [No, Off, Disabled, Reset, '0'], 
01 = [Yes, On, Enabled, Set, '1'], 
10 = Error, 
11= [Unavailable, Unknown]";
CM_ SG_ 2381450750 Indic9 "MSB/LSB: 
00 = [No, Off, Disabled, Reset, '0'], 
01 = [Yes, On, Enabled, Set, '1'], 
10 = Error, 
11= [Unavailable, Unknown]";
CM_ SG_ 2381450750 Indic8 "MSB/LSB: 
00 = [No, Off, Disabled, Reset, '0'], 
01 = [Yes, On, Enabled, Set, '1'], 
10 = Error, 
11= [Unavailable, Unknown]";
CM_ SG_ 2381450750 Indic7 "MSB/LSB: 
00 = [No, Off, Disabled, Reset, '0'], 
01 = [Yes, On, Enabled, Set, '1'], 
10 = Error, 
11= [Unavailable, Unknown]";
CM_ SG_ 2381450750 Indic6 "MSB/LSB: 
00 = [No, Off, Disabled, Reset, '0'], 
01 = [Yes, On, Enabled, Set, '1'], 
10 = Error, 
11= [Unavailable, Unknown]";
CM_ SG_ 2381450750 Indic5 "MSB/LSB: 
00 = [No, Off, Disabled, Reset, '0'], 
01 = [Yes, On, Enabled, Set, '1'], 
10 = Error, 
11= [Unavailable, Unknown]";
CM_ SG_ 2381450750 Indic4 "MSB/LSB: 
00 = [No, Off, Disabled, Reset, '0'], 
01 = [Yes, On, Enabled, Set, '1'], 
10 = Error, 
11= [Unavailable, Unknown]";
CM_ SG_ 2381450750 Indic3 "MSB/LSB: 
00 = [No, Off, Disabled, Reset, '0'], 
01 = [Yes, On, Enabled, Set, '1'], 
10 = Error, 
11= [Unavailable, Unknown]";
CM_ SG_ 2381450750 Indic2 "MSB/LSB: 
00 = [No, Off, Disabled, Reset, '0'], 
01 = [Yes, On, Enabled, Set, '1'], 
10 = Error, 
11= [Unavailable, Unknown]";
CM_ SG_ 2381450750 Indic1 "MSB/LSB: 
00 = [No, Off, Disabled, Reset, '0'], 
01 = [Yes, On, Enabled, Set, '1'], 
10 = Error, 
11= [Unavailable, Unknown]";
CM_ SG_ 2381450750 IndicatorBankInstance "Number of route, waypoint, event, mark, etc.";
CM_ BO_ 2582779134 "Provides parametric data for a specific battery, indicated by the battery instance field. Used primarily by display or instrumentation devices, but may also be used by battery management controls.";
CM_ SG_ 2582779134 SID "An upward counting number used to tie related information together between different PGNs.For example,SID would be used to tie together COG,SOG and RAIM values to a given Pos.255=no valid Pos fix to tie it to.Range 0 to 250 for valid Pos fixes.";
CM_ SG_ 2582779134 BatteryCurrent "+ = current consumed, - = current supplied";
CM_ SG_ 2582779134 BatteryInstance "Number of route, waypoint, event, mark, etc.";
CM_ BO_ 2381388286 "This PGN provides a single Trans that describes Pos of a vessel relative to both horizontal and vertical planes.This would typically be used for vessel stabilization,vessel Ctrl and onboard platform stabilization.

Products that directly interface to pi";
CM_ SG_ 2381388286 Roll "Oscillation of ship about it's longitudinal axis.  Roll to the starboard is positive.";
CM_ SG_ 2381388286 Pitch_ "Oscillation of ship about it's latitudinal axis.  Bow moving up is positive.";
CM_ SG_ 2381388286 Yaw "Oscillation of ship about it's vertical axis.  Bow moving to starboard is positive.";
CM_ SG_ 2381388286 SID "An upward counting number used to tie related information together between different PGNs.For example,SID would be used to tie together COG,SOG and RAIM values to a given Pos.255=no valid Pos fix to tie it to.Range 0 to 250 for valid Pos fixes.";
CM_ BO_ 2314732798 "The'Altitude Delta,High Precision Rapid Update'Parameter Group is intended for Apps where very high precision and very fast update rates are needed for altitude and course over ground data.This PG can provide delta altitude changes down to 1 millimeter,a ";
CM_ SG_ 2314732798 CourseOverGround "The direction of the path over ground actually followed by a vessel.";
CM_ SG_ 2314732798 Direction "0 = True, 
1 = Magnetic, 
2 = Error, 
3 = Null";
CM_ SG_ 2314732798 GNSSQuality "0 = no GPS,
1 = GNSS fix,
2 = DGNSS fix,
3 = Precise GNSS*,
4 = RTK Fixed Integer,
5 = RTK Float,
6 = Est(DR)mode,
7 = Manual Input,
8 = Simulate mode,
9-13 = Reserved,
14 = Error,
15 = Null.*Precise GNSS means no deliberate degradation(such as";
CM_ SG_ 2314732798 SequenceID_ "An upward counting number used to tie related information together between different PGNs.For example,SID would be used to tie together COG,SOG and RAIM values to a given Pos.255=no valid Pos fix to tie it to.Range 0 to 250 for valid Pos fixes.";
CM_ BO_ 2650474750 "This parameter group provides data associated with ITU-R M.1371 Msg 10 UTC and Date Inquiry Msg used to Rq current UTC and date.An AIS device may generate this parameter group either upon receiving a VHF data link Msg 10,or upon receipt of an ISO NMEA Rq ";
CM_ SG_ 2650474750 DestinationID "Number of route, waypoint, event, mark, etc.";
CM_ SG_ 2650474750 AISTransceiverInformation "0 = Channel A VDL reception,
1 = Channel B VDL reception,
2 = Channel A VDL transmission,
3 = Channel B VDL transmission,
4 = Own information not broadcast,
5-31 = Reserved.";
CM_ SG_ 2650474750 SourceID "Number of route, waypoint, event, mark, etc.";
CM_ SG_ 2650474750 RepeatIndicator "Used by the repeater to indicate how many times a message has been repeated (range of 0 to 3).

0 = Default
1 = First retransmission
2 = Second retransmission
3 = Final retransmission

See ITU-R M.1371-1 for more information.";
CM_ SG_ 2650474750 MsgID "Message Identifier (range of 0 to 63).

See ITU-R M.1371-1 for more information.";
CM_ BO_ 2650472958 "This parameter group provides data from ITU-R M.1371 Msg 4 Base Station Report providing Pos,time,date,and current slot number of a base station,and 11 UTC and date Resp Msg providing current UTC and date if available.An AIS device may generate this param";
CM_ SG_ 2650472958 TypeOfElectronicPosingDevice "0=Undefined (default), 
1=GPS, 
2=GLONASS, 
3=Combined GPS/GLONASS, 
4=Loran-C, 
5=Chayka, 
6=Integrated Navigation System, 
7=Surveyed (Base Station), 
8-15=Reserve for future use.

See ITU-R M.1371-1 for more information.";
CM_ SG_ 2650472958 PosDate "Days since January 1, 1970,   Date is relative to UTC Time.";
CM_ SG_ 2650472958 AISTransceiverInformation "0 = Channel A VDL reception,
1 = Channel B VDL reception,
2 = Channel A VDL transmission,
3 = Channel B VDL transmission,
4 = Own information not broadcast,
5-31 = Reserved.";
CM_ SG_ 2650472958 CommunicationState "The Communication State contains information used by the various TDMA slot allocation algorithms and synchronization information

See ITU-R M.1371-1 for more information.";
CM_ SG_ 2650472958 PosTime "24 hour clock, 0 =  midnight,  time is in UTC";
CM_ SG_ 2650472958 RAIMflag "0 = RAIM not in use (default),
1 = RAIM in use

See ITU-R M.1371-1 for more information.";
CM_ SG_ 2650472958 PosAccuracy "0=low accuracy>10m such as nondifferential GNSS (default), 
1=high accuracy <10m such as DGNSS

See ITU-R M.1371-1 for more information.";
CM_ SG_ 2650472958 UserID "Number of route, waypoint, event, mark, etc.";
CM_ SG_ 2650472958 RepeatIndicator "Used by the repeater to indicate how many times a message has been repeated (range of 0 to 3).

0 = Default
1 = First retransmission
2 = Second retransmission
3 = Final retransmission

See ITU-R M.1371-1 for more information.";
CM_ SG_ 2650472958 MsgID "Message Identifier (range of 0 to 63).

See ITU-R M.1371-1 for more information.";
CM_ BO_ 2650475262 "This parameter group provides data associated with ITU-R M.1371 Msg 14 Safety Related Broadcast Msg supporting broadcast communication of safety related data.An AIS device may generate this parameter group either upon receiving a VHF data link Msg 14,or u";
CM_ SG_ 2650475262 SafetyRelatedText "Name of place, route, waypoint, destination, vessel, vehicle, etc.";
CM_ SG_ 2650475262 AISTransceiverInformation "0 = Channel A VDL reception,
1 = Channel B VDL reception,
2 = Channel A VDL transmission,
3 = Channel B VDL transmission,
4 = Own information not broadcast,
5-31 = Reserved.";
CM_ SG_ 2650475262 SourceID "Number of route, waypoint, event, mark, etc.";
CM_ SG_ 2650475262 RepeatIndicator "Used by the repeater to indicate how many times a message has been repeated (range of 0 to 3).

0 = Default
1 = First retransmission
2 = Second retransmission
3 = Final retransmission

See ITU-R M.1371-1 for more information.";
CM_ SG_ 2650475262 MsgID "Message Identifier (range of 0 to 63).

See ITU-R M.1371-1 for more information.";
CM_ BO_ 2650474238 "This parameter group provides data associated with ITU-R M.1371 Msg 9 SAR Aircraft Pos Report Msg for Airborne AIS units conducting Search and Rescue operations.An AIS device may generate this parameter group either upon receiving a VHF data link Msg 9,or";
CM_ SG_ 2650474238 DataTerminalEquipment "0=Available,
1=not available.

See ITU-R M.1371-1 for more information.";
CM_ SG_ 2650474238 AISTransceiverInformation "0 = Channel A VDL reception,
1 = Channel B VDL reception,
2 = Channel A VDL transmission,
3 = Channel B VDL transmission,
4 = Own information not broadcast,
5-31 = Reserved.";
CM_ SG_ 2650474238 CommunicationState "The Communication State contains information used by the various TDMA slot allocation algorithms and synchronization information

See ITU-R M.1371-1 for more information.";
CM_ SG_ 2650474238 COG "The direction of the path over ground actually followed by a vessel.";
CM_ SG_ 2650474238 TimeStamp "0-59=UTC second when report was generated,
60=time stamp not available(default),
61=Posing system is in manual input mode,
62=Electronic Pos fixing system operates in Est(dead reckoning)mode,
63=Posing system is inoperative

See ITU-R M.1371-1 for m";
CM_ SG_ 2650474238 RAIMFlag "0 = RAIM not in use (default),
1 = RAIM in use

See ITU-R M.1371-1 for more information.";
CM_ SG_ 2650474238 PosAccuracy "0=low accuracy>10m such as nondifferential GNSS (default), 
1=high accuracy <10m such as DGNSS

See ITU-R M.1371-1 for more information.";
CM_ SG_ 2650474238 UserID "Number of route, waypoint, event, mark, etc.";
CM_ SG_ 2650474238 RepeatIndicator "Used by the repeater to indicate how many times a message has been repeated (range of 0 to 3).

0 = Default
1 = First retransmission
2 = Second retransmission
3 = Final retransmission

See ITU-R M.1371-1 for more information.";
CM_ SG_ 2650474238 MsgID "Message Identifier (range of 0 to 63).

See ITU-R M.1371-1 for more information.";
CM_ BO_ 2650475518 "This parameter group provides data associated with ITU-R M.1371 Msg 15 Interrogation Msg used to Rq a specific ITU-R M.1371 Msg resulting in Resps from one more AIS mobile units.An AIS device may generate this parameter group either upon receiving a VHF d";
CM_ SG_ 2650475518 SlotOffset21 "Number of route, waypoint, event, mark, etc.";
CM_ SG_ 2650475518 MsgID21 "Message Identifier (range of 0 to 63).

See ITU-R M.1371-1 for more information.";
CM_ SG_ 2650475518 DestinationID2 "Number of route, waypoint, event, mark, etc.";
CM_ SG_ 2650475518 SlotOffset12 "Number of route, waypoint, event, mark, etc.";
CM_ SG_ 2650475518 MsgID12 "Message Identifier (range of 0 to 63).

See ITU-R M.1371-1 for more information.";
CM_ SG_ 2650475518 SlotOffset11 "Number of route, waypoint, event, mark, etc.";
CM_ SG_ 2650475518 MsgID11 "Message Identifier (range of 0 to 63).

See ITU-R M.1371-1 for more information.";
CM_ SG_ 2650475518 DestinationID1 "Number of route, waypoint, event, mark, etc.";
CM_ SG_ 2650475518 AISTransceiverInformation "0 = Channel A VDL reception,
1 = Channel B VDL reception,
2 = Channel A VDL transmission,
3 = Channel B VDL transmission,
4 = Own information not broadcast,
5-31 = Reserved.";
CM_ SG_ 2650475518 SourceID "Number of route, waypoint, event, mark, etc.";
CM_ SG_ 2650475518 RepeatIndicator "Used by the repeater to indicate how many times a message has been repeated (range of 0 to 3).

0 = Default
1 = First retransmission
2 = Second retransmission
3 = Final retransmission

See ITU-R M.1371-1 for more information.";
CM_ SG_ 2650475518 MsgID "Message Identifier (range of 0 to 63).

See ITU-R M.1371-1 for more information.";
CM_ BO_ 2650476030 "This parameter group provides data associated with ITU-R M.1371 Msg 20 Data Link Management Msg for reserving slots for base stations.An AIS device may generate this parameter group either upon receiving a VHF data link Msg 20,or upon receipt of an ISO NM";
CM_ SG_ 2650476030 Increment4 "Number of route, waypoint, event, mark, etc.";
CM_ SG_ 2650476030 TimeOut4 "Number of route, waypoint, event, mark, etc.";
CM_ SG_ 2650476030 NumberOfSlots4 "Number of route, waypoint, event, mark, etc.";
CM_ SG_ 2650476030 OffsetNumber4 "Number of route, waypoint, event, mark, etc.";
CM_ SG_ 2650476030 Increment3 "Number of route, waypoint, event, mark, etc.";
CM_ SG_ 2650476030 TimeOut3 "Number of route, waypoint, event, mark, etc.";
CM_ SG_ 2650476030 NumberOfSlots3 "Number of route, waypoint, event, mark, etc.";
CM_ SG_ 2650476030 OffsetNumber3 "Number of route, waypoint, event, mark, etc.";
CM_ SG_ 2650476030 Increment2 "Number of route, waypoint, event, mark, etc.";
CM_ SG_ 2650476030 TimeOut2 "Number of route, waypoint, event, mark, etc.";
CM_ SG_ 2650476030 NumberOfSlots2 "Number of route, waypoint, event, mark, etc.";
CM_ SG_ 2650476030 OffsetNumber2 "Number of route, waypoint, event, mark, etc.";
CM_ SG_ 2650476030 Increment1 "Number of route, waypoint, event, mark, etc.";
CM_ SG_ 2650476030 TimeOut1 "Number of route, waypoint, event, mark, etc.";
CM_ SG_ 2650476030 NumberOfSlots1 "Number of route, waypoint, event, mark, etc.";
CM_ SG_ 2650476030 OffsetNumber1 "Number of route, waypoint, event, mark, etc.";
CM_ SG_ 2650476030 AISTransceiverInformation "0 = Channel A VDL reception,
1 = Channel B VDL reception,
2 = Channel A VDL transmission,
3 = Channel B VDL transmission,
4 = Own information not broadcast,
5-31 = Reserved.";
CM_ SG_ 2650476030 SourceStationID "Number of route, waypoint, event, mark, etc.";
CM_ SG_ 2650476030 RepeatIndicator "Used by the repeater to indicate how many times a message has been repeated (range of 0 to 3).

0 = Default
1 = First retransmission
2 = Second retransmission
3 = Final retransmission

See ITU-R M.1371-1 for more information.";
CM_ SG_ 2650476030 MsgID "Message Identifier (range of 0 to 63).

See ITU-R M.1371-1 for more information.";
CM_ BO_ 2583363838 "This parameter group provides data associated with ITU-R M.1371 Msg 17 GNSS Broadcast Binary Msg containing DGNSS corrections from a base station.An AIS device may generate this parameter group either upon receiving a VHF data link Msg 17,or upon receipt ";
CM_ SG_ 2583363838 NumberOfBitsInBinaryDataField "Number of route, waypoint, event, mark, etc.";
CM_ SG_ 2583363838 AISTransceiverInformation "0 = Channel A VDL reception,
1 = Channel B VDL reception,
2 = Channel A VDL transmission,
3 = Channel B VDL transmission,
4 = Own information not broadcast,
5-31 = Reserved.";
CM_ SG_ 2583363838 SourceID "Number of route, waypoint, event, mark, etc.";
CM_ SG_ 2583363838 RepeatIndicator "Used by the repeater to indicate how many times a message has been repeated (range of 0 to 3).

0 = Default
1 = First retransmission
2 = Second retransmission
3 = Final retransmission

See ITU-R M.1371-1 for more information.";
CM_ SG_ 2583363838 MsgID "Message Identifier (range of 0 to 63).

See ITU-R M.1371-1 for more information.";
CM_ BO_ 2650473214 "This parameter group provides data associated with ITU-R M.1371 Msg 5 Ship Static and Voyage Related Data Msg.An AIS device may generate this parameter group either upon receiving a VHF data link Msg 5,or upon receipt of an ISO NMEA Rq PGN.Cmd Group Funct";
CM_ SG_ 2650473214 CallSign "Length specified by PGN field definition.";
CM_ SG_ 2650473214 IMO "Number of route, waypoint, event, mark, etc.";
CM_ SG_ 2650473214 UserID "Number of route, waypoint, event, mark, etc.";
CM_ SG_ 2650473214 RepeatIndicator "Used by the repeater to indicate how many times a message has been repeated (range of 0 to 3).

0 = Default
1 = First retransmission
2 = Second retransmission
3 = Final retransmission

See ITU-R M.1371-1 for more information.";
CM_ SG_ 2650473214 MsgID "Message Identifier (range of 0 to 63).

See ITU-R M.1371-1 for more information.";
CM_ BO_ 2448953342 "This parameter group provides data associated with ITU-R M.1371 Msg 18 Standard Class B Equipment Pos Report.An AIS device may generate this parameter group either upon receiving a VHF data link Msg 18,or upon receipt of an ISO NMEA Rq PGN(see ITU-R M.137";
CM_ SG_ 2448953342 ComminicationStateSelectorFlag "0=SOTDMA communication state,
1=ITDMA communication state follows.

See ITU-R M.1371-1 for more information.";
CM_ SG_ 2448953342 TrueHeading "Degrees clockwise relative to True North.";
CM_ SG_ 2448953342 AISTransceiverInformation "0 = Channel A VDL reception,
1 = Channel B VDL reception,
2 = Channel A VDL transmission,
3 = Channel B VDL transmission,
4 = Own information not broadcast,
5-31 = Reserved.";
CM_ SG_ 2448953342 CommunicationState "The Communication State contains information used by the various TDMA slot allocation algorithms and synchronization information

See ITU-R M.1371-1 for more information.";
CM_ SG_ 2448953342 COG "The direction of the path over ground actually followed by a vessel.";
CM_ SG_ 2448953342 TimeStamp "0-59=UTC second when report was generated,
60=time stamp not available(default),
61=Posing system is in manual input mode,
62=Electronic Pos fixing system operates in Est(dead reckoning)mode,
63=Posing system is inoperative

See ITU-R M.1371-1 for m";
CM_ SG_ 2448953342 RAIMflag "0 = RAIM not in use (default),
1 = RAIM in use

See ITU-R M.1371-1 for more information.";
CM_ SG_ 2448953342 PosAccuracy "0=low accuracy>10m such as nondifferential GNSS (default), 
1=high accuracy <10m such as DGNSS

See ITU-R M.1371-1 for more information.";
CM_ SG_ 2448953342 UserID "Number of route, waypoint, event, mark, etc.";
CM_ SG_ 2448953342 RepeatIndicator "Used by the repeater to indicate how many times a message has been repeated (range of 0 to 3).

0 = Default
1 = First retransmission
2 = Second retransmission
3 = Final retransmission

See ITU-R M.1371-1 for more information.";
CM_ SG_ 2448953342 MsgID "Message Identifier (range of 0 to 63).

See ITU-R M.1371-1 for more information.";
CM_ BO_ 2448953598 "This parameter group provides data associated with ITU-R M.1371 Msg 19 Ex Class B Equipment Pos Report containing Pos and static information.An AIS device may generate this parameter group either upon receiving a VHF data link Msg 19,or upon receipt of an";
CM_ SG_ 2448953598 Name "Name of place, route, waypoint, destination, vessel, vehicle, etc.";
CM_ SG_ 2448953598 PosReferencePointAftOfShipsBow "Dependent upon PG Field definition.";
CM_ SG_ 2448953598 PosReferencePointFromStarboard "Dependent upon PG Field definition.";
CM_ SG_ 2448953598 ShipBeam "Dependent upon PG Field definition.";
CM_ SG_ 2448953598 ShipLength "Dependent upon PG Field definition.";
CM_ SG_ 2448953598 TypeOfElectronicPosingDevice "0=Undefined (default), 
1=GPS, 
2=GLONASS, 
3=Combined GPS/GLONASS, 
4=Loran-C, 
5=Chayka, 
6=Integrated Navigation System, 
7=Surveyed (Base Station), 
8-15=Reserve for future use.

See ITU-R M.1371-1 for more information.";
CM_ SG_ 2448953598 TrueHeading "Degrees clockwise relative to True North.";
CM_ SG_ 2448953598 Ship_CargoType "0=Not Available or no ship (default), 
1-99= (See ITU-R M.1371-1 Section 3.3.8.2.3.2 Table 18), 
100-199=Reserved for Regional (See ITU-R M.1371-1), 
200-255=Reserved for future (See ITU-R M.1371-1).";
CM_ SG_ 2448953598 COG "The direction of the path over ground actually followed by a vessel.";
CM_ SG_ 2448953598 TimeStamp "0-59=UTC second when report was generated,
60=time stamp not available(default),
61=Posing system is in manual input mode,
62=Electronic Pos fixing system operates in Est(dead reckoning)mode,
63=Posing system is inoperative

See ITU-R M.1371-1 for m";
CM_ SG_ 2448953598 RAIMflag "0 = RAIM not in use (default),
1 = RAIM in use

See ITU-R M.1371-1 for more information.";
CM_ SG_ 2448953598 PosAccuracy "0=low accuracy>10m such as nondifferential GNSS (default), 
1=high accuracy <10m such as DGNSS

See ITU-R M.1371-1 for more information.";
CM_ SG_ 2448953598 UserID "Number of route, waypoint, event, mark, etc.";
CM_ SG_ 2448953598 RepeatIndicator "Used by the repeater to indicate how many times a message has been repeated (range of 0 to 3).

0 = Default
1 = First retransmission
2 = Second retransmission
3 = Final retransmission

See ITU-R M.1371-1 for more information.";
CM_ SG_ 2448953598 MsgID "Message Identifier (range of 0 to 63).

See ITU-R M.1371-1 for more information.";
CM_ BO_ 2448953086 "This parameter group provides data associated with ITU-R M.1371 Msgs 1,2,and 3 Pos Reports,autonomous,assigned,and Resp to interrogation,respectively.An AIS device may generate this parameter group either upon receiving a VHF data link Msg 1,2 3,or upon r";
CM_ SG_ 2448953086 NavigationalStatus "0 = under way using Eng,
1 = at anchor,
2 = not under Cmd,
3 = restricted manoeuvrability,
4 = constrained by her draught,
5 = moored,
6 = aground,
7 = engaged in fishing,
8 = under way sailing,
9 = reserved for future amendment of navigational s";
CM_ SG_ 2448953086 RateOfTurn "+ = Bow turning to starboard, 1 deg/min = .00029 rad/sec";
CM_ SG_ 2448953086 TrueHeading "Degrees clockwise relative to True North.";
CM_ SG_ 2448953086 AISTransceiverInformation "0 = Channel A VDL reception,
1 = Channel B VDL reception,
2 = Channel A VDL transmission,
3 = Channel B VDL transmission,
4 = Own information not broadcast,
5-31 = Reserved.";
CM_ SG_ 2448953086 CommunicationState "The Communication State contains information used by the various TDMA slot allocation algorithms and synchronization information

See ITU-R M.1371-1 for more information.";
CM_ SG_ 2448953086 COG "The direction of the path over ground actually followed by a vessel.";
CM_ SG_ 2448953086 TimeStamp "0-59=UTC second when report was generated,
60=time stamp not available(default),
61=Posing system is in manual input mode,
62=Electronic Pos fixing system operates in Est(dead reckoning)mode,
63=Posing system is inoperative

See ITU-R M.1371-1 for m";
CM_ SG_ 2448953086 RAIMflag "0 = RAIM not in use (default),
1 = RAIM in use

See ITU-R M.1371-1 for more information.";
CM_ SG_ 2448953086 PosAccuracy "0=low accuracy>10m such as nondifferential GNSS (default), 
1=high accuracy <10m such as DGNSS

See ITU-R M.1371-1 for more information.";
CM_ SG_ 2448953086 UserID "Number of route, waypoint, event, mark, etc.";
CM_ SG_ 2448953086 RepeatIndicator "Used by the repeater to indicate how many times a message has been repeated (range of 0 to 3).

0 = Default
1 = First retransmission
2 = Second retransmission
3 = Final retransmission

See ITU-R M.1371-1 for more information.";
CM_ SG_ 2448953086 MsgID "Message Identifier (range of 0 to 63).

See ITU-R M.1371-1 for more information.";
CM_ BO_ 2650473982 "This parameter group provides data associated with ITU-R M.1371 Msg 8 Binary Broadcast Msg supporting broadcast communication of binary data.An AIS device may generate this parameter group either upon receiving a VHF data link Msg 8,or upon receipt of an ";
CM_ SG_ 2650473982 NumberOfBitsInBinaryDataField "Number of route, waypoint, event, mark, etc.";
CM_ SG_ 2650473982 AISTransceiverInformation "0 = Channel A VDL reception,
1 = Channel B VDL reception,
2 = Channel A VDL transmission,
3 = Channel B VDL transmission,
4 = Own information not broadcast,
5-31 = Reserved.";
CM_ SG_ 2650473982 SourceID "Number of route, waypoint, event, mark, etc.";
CM_ SG_ 2650473982 RepeatIndicator "Used by the repeater to indicate how many times a message has been repeated (range of 0 to 3).

0 = Default
1 = First retransmission
2 = Second retransmission
3 = Final retransmission

See ITU-R M.1371-1 for more information.";
CM_ SG_ 2650473982 MsgID "Message Identifier (range of 0 to 63).

See ITU-R M.1371-1 for more information.";
CM_ BO_ 2650475774 "This parameter group provides data associated with ITU-R M.1371 Msg 16 Assigned Mode Cmd Msg for assigning specific behavior by a competent authority.An AIS device may generate this parameter group either upon receiving a VHF data link Msg 16,or upon rece";
CM_ SG_ 2650475774 IncrementB "Number of route, waypoint, event, mark, etc.";
CM_ SG_ 2650475774 OffsetB "Number of route, waypoint, event, mark, etc.";
CM_ SG_ 2650475774 DestinationIDB "Number of route, waypoint, event, mark, etc.";
CM_ SG_ 2650475774 IncrementA "Number of route, waypoint, event, mark, etc.";
CM_ SG_ 2650475774 OffsetA "Number of route, waypoint, event, mark, etc.";
CM_ SG_ 2650475774 DestinationIDA "Number of route, waypoint, event, mark, etc.";
CM_ SG_ 2650475774 AISTransceiverInformation "0 = Channel A VDL reception,
1 = Channel B VDL reception,
2 = Channel A VDL transmission,
3 = Channel B VDL transmission,
4 = Own information not broadcast,
5-31 = Reserved.";
CM_ SG_ 2650475774 SourceID "Number of route, waypoint, event, mark, etc.";
CM_ SG_ 2650475774 RepeatIndicator "Used by the repeater to indicate how many times a message has been repeated (range of 0 to 3).

0 = Default
1 = First retransmission
2 = Second retransmission
3 = Final retransmission

See ITU-R M.1371-1 for more information.";
CM_ SG_ 2650475774 MsgID "Message Identifier (range of 0 to 63).

See ITU-R M.1371-1 for more information.";
CM_ BO_ 2650475006 "This parameter group provides data associated with ITU-R M.1371 Msg 12 Addressed Safety Related Msg supporting addressed communication of safety related data.An AIS device may generate this parameter group either upon receiving a VHF data link Msg 12,or u";
CM_ SG_ 2650475006 SafetyRelatedText "Name of place, route, waypoint, destination, vessel, vehicle, etc.";
CM_ SG_ 2650475006 RetransmitFlag "0=No retransmission,
1=retransmitted.

See ITU-R M.1371-1 for more information.";
CM_ SG_ 2650475006 DestinationID "Number of route, waypoint, event, mark, etc.";
CM_ SG_ 2650475006 SequenceNumber_ "Range 0-3

See ITU-R M.1371-1 for more information.";
CM_ SG_ 2650475006 AISTransceiverInformation "0 = Channel A VDL reception,
1 = Channel B VDL reception,
2 = Channel A VDL transmission,
3 = Channel B VDL transmission,
4 = Own information not broadcast,
5-31 = Reserved.";
CM_ SG_ 2650475006 SourceID "Number of route, waypoint, event, mark, etc.";
CM_ SG_ 2650475006 RepeatIndicator "Used by the repeater to indicate how many times a message has been repeated (range of 0 to 3).

0 = Default
1 = First retransmission
2 = Second retransmission
3 = Final retransmission

See ITU-R M.1371-1 for more information.";
CM_ SG_ 2650475006 MsgID "Message Identifier (range of 0 to 63).

See ITU-R M.1371-1 for more information.";
CM_ BO_ 2650473470 "This parameter group provides data associated with ITU-R M.1371 Msg 6 Addressed Binary Msg supporting address communication of binary data.An AIS device may generate this parameter group either upon receiving a VHF data link Msg 6,or upon receipt of an IS";
CM_ SG_ 2650473470 NumberOfBitsInBinaryDataField "Number of route, waypoint, event, mark, etc.";
CM_ SG_ 2650473470 RetransmitFlag "0=No retransmission,
1=retransmitted.

See ITU-R M.1371-1 for more information.";
CM_ SG_ 2650473470 DestinationID "Number of route, waypoint, event, mark, etc.";
CM_ SG_ 2650473470 SequenceNumber_ "Range 0-3

See ITU-R M.1371-1 for more information.";
CM_ SG_ 2650473470 AISTransceiverInformation "0 = Channel A VDL reception,
1 = Channel B VDL reception,
2 = Channel A VDL transmission,
3 = Channel B VDL transmission,
4 = Own information not broadcast,
5-31 = Reserved.";
CM_ SG_ 2650473470 SourceID "Number of route, waypoint, event, mark, etc.";
CM_ SG_ 2650473470 RepeatIndicator "Used by the repeater to indicate how many times a message has been repeated (range of 0 to 3).

0 = Default
1 = First retransmission
2 = Second retransmission
3 = Final retransmission

See ITU-R M.1371-1 for more information.";
CM_ SG_ 2650473470 MsgID "Message Identifier (range of 0 to 63).

See ITU-R M.1371-1 for more information.";
CM_ BO_ 2650473726 "This parameter group provides data associated with ITU-R M.1371 Msgs 7 Binary Acknowledge Msg and 13 Safety Related Acknowledge Msg.Msg 7 acknowledges receipt of Msg 6 while Msg 13 acknowledges receipt of Msg 14.An AIS device may generate this parameter g";
CM_ SG_ 2650473726 SequenceNumberForIDn "Range 0-3

See ITU-R M.1371-1 for more information.";
CM_ SG_ 2650473726 SequenceNumberForID1 "Range 0-3

See ITU-R M.1371-1 for more information.";
CM_ SG_ 2650473726 DestinationID1 "Number of route, waypoint, event, mark, etc.";
CM_ SG_ 2650473726 AISTransceiverInformation "0 = Channel A VDL reception,
1 = Channel B VDL reception,
2 = Channel A VDL transmission,
3 = Channel B VDL transmission,
4 = Own information not broadcast,
5-31 = Reserved.";
CM_ SG_ 2650473726 SourceID "Number of route, waypoint, event, mark, etc.";
CM_ SG_ 2650473726 RepeatIndicator "Used by the repeater to indicate how many times a message has been repeated (range of 0 to 3).

0 = Default
1 = First retransmission
2 = Second retransmission
3 = Final retransmission

See ITU-R M.1371-1 for more information.";
CM_ SG_ 2650473726 MsgID "Message Identifier (range of 0 to 63).

See ITU-R M.1371-1 for more information.";
CM_ BO_ 2365475070 "Wheel-based Speed and Distance";
CM_ SG_ 2365475070 OperatorDirectionReversed "This parameter indicates whether the reported direction is reversed from the perspective of the operator.";
BA_DEF_ BO_  "GenMsgCycleTimeFast" INT 0 3600000;
BA_DEF_ SG_  "SigType" ENUM  "Default","Range","RangeSigned","ASCII","Discrete","Control","ReferencePGN","DTC","StringDelimiter","StringLength","StringLengthControl";
BA_DEF_ SG_  "GenSigStartValue" INT 0 10000;
BA_DEF_ SG_  "GenSigSendType" ENUM  "Cyclic","OnWrite","reserved","OnChange","reserved","reserved","reserved","NoSigSendType";
BA_DEF_ SG_  "GenSigILSupport" ENUM  "Yes","No";
BA_DEF_ SG_  "GenSigEVName" STRING ;
BA_DEF_ SG_  "SPN" INT 0 524287;
BA_DEF_ SG_  "DDI" INT 0 65535;
BA_DEF_ SG_  "SAEDocument" STRING ;
BA_DEF_ BO_  "GenMsgStartDelayTime" INT 0 100000;
BA_DEF_ BO_  "GenMsgILSupport" ENUM  "Yes","No";
BA_DEF_ BO_  "GenMsgRequestable" INT 0 1;
BA_DEF_ BO_  "GenMsgSendType" ENUM  "cyclic","reserved","cyclicIfActive","reserved","reserved","reserved","reserved","reserved","noMsgSendType";
BA_DEF_ BO_  "VFrameFormat" ENUM  "StandardCAN","ExtendedCAN","reserved","J1939PG";
BA_DEF_ BO_  "SingleFrame" INT 0 1;
BA_DEF_ BO_  "GenMsgCycleTime" INT 0 3600000;
BA_DEF_ BO_  "SAE_Document" STRING ;
BA_DEF_ SG_  "SystemSignalLongSymbol" STRING ;
BA_DEF_DEF_  "GenMsgCycleTimeFast" 0;
BA_DEF_DEF_  "SigType" "Default";
BA_DEF_DEF_  "GenSigStartValue" 0;
BA_DEF_DEF_  "GenSigSendType" "NoSigSendType";
BA_DEF_DEF_  "GenSigILSupport" "Yes";
BA_DEF_DEF_  "GenSigEVName" "Env@Nodename_@Signame";
BA_DEF_DEF_  "SPN" 0;
BA_DEF_DEF_  "DDI" 0;
BA_DEF_DEF_  "SAEDocument" "";
BA_DEF_DEF_  "GenMsgStartDelayTime" 0;
BA_DEF_DEF_  "GenMsgILSupport" "Yes";
BA_DEF_DEF_  "GenMsgRequestable" 1;
BA_DEF_DEF_  "GenMsgSendType" "noMsgSendType";
BA_DEF_DEF_  "VFrameFormat" "J1939PG";
BA_DEF_DEF_  "SingleFrame" 1;
BA_DEF_DEF_  "GenMsgCycleTime" 0;
BA_DEF_DEF_  "SAE_Document" "";
BA_DEF_DEF_  "SystemSignalLongSymbol" "";
BA_ "SAE_Document" BO_ 2583299326 "NMEA2000";
BA_ "GenMsgCycleTime" BO_ 2583299326 1000;
BA_ "SingleFrame" BO_ 2583299326 0;
BA_ "SAE_Document" BO_ 2583300862 "NMEA2000";
BA_ "SAE_Document" BO_ 2583300606 "NMEA2000";
BA_ "SingleFrame" BO_ 2583300606 0;
BA_ "SAE_Document" BO_ 2583299838 "NMEA2000";
BA_ "GenMsgCycleTime" BO_ 2583299838 1000;
BA_ "SingleFrame" BO_ 2583299838 0;
BA_ "SAE_Document" BO_ 2583301118 "NMEA2000";
BA_ "SingleFrame" BO_ 2583301118 0;
BA_ "GenMsgRequestable" BO_ 2583301118 0;
BA_ "SAE_Document" BO_ 2381841918 "NMEA2000";
BA_ "GenMsgCycleTime" BO_ 2381841918 1000;
BA_ "SingleFrame" BO_ 2381841918 0;
BA_ "SAE_Document" BO_ 2583301886 "NMEA2000";
BA_ "SAE_Document" BO_ 2583302142 "NMEA2000";
BA_ "SingleFrame" BO_ 2583302142 0;
BA_ "SAE_Document" BO_ 2583299070 "NMEA2000";
BA_ "GenMsgCycleTime" BO_ 2583299070 1000;
BA_ "SAE_Document" BO_ 2583298814 "NMEA2000";
BA_ "SingleFrame" BO_ 2583298814 0;
BA_ "SAE_Document" BO_ 2583303422 "NMEA2000";
BA_ "SingleFrame" BO_ 2583303422 0;
BA_ "SAE_Document" BO_ 2582778366 "NMEA2000";
BA_ "GenMsgCycleTime" BO_ 2582778366 2500;
BA_ "SAE_Document" BO_ 2516387838 "NMEA2000";
BA_ "GenMsgCycleTime" BO_ 2516387838 500;
BA_ "SAE_Document" BO_ 2516387582 "NMEA2000";
BA_ "GenMsgCycleTime" BO_ 2516387582 500;
BA_ "SAE_Document" BO_ 2515667710 "NMEA2000";
BA_ "SingleFrame" BO_ 2515667710 0;
BA_ "SAE_Document" BO_ 2314338558 "NMEA2000";
BA_ "GenMsgCycleTime" BO_ 2314338558 100;
BA_ "SAE_Document" BO_ 2314338814 "NMEA2000";
BA_ "GenMsgCycleTime" BO_ 2314338814 500;
BA_ "SingleFrame" BO_ 2314338814 0;
BA_ "SAE_Document" BO_ 2582975486 "NMEA2000";
BA_ "GenMsgCycleTime" BO_ 2582975486 1000;
BA_ "SingleFrame" BO_ 2582975486 0;
BA_ "SAE_Document" BO_ 2382238206 "NMEA2000";
BA_ "GenMsgCycleTime" BO_ 2382238206 1000;
BA_ "SingleFrame" BO_ 2382238206 0;
BA_ "SAE_Document" BO_ 2583172350 "NMEA2000";
BA_ "GenMsgCycleTime" BO_ 2583172350 10000;
BA_ "SingleFrame" BO_ 2583172350 0;
BA_ "SAE_Document" BO_ 2449150206 "NMEA2000";
BA_ "SingleFrame" BO_ 2449150206 0;
BA_ "SAE_Document" BO_ 2583301630 "NMEA2000";
BA_ "SingleFrame" BO_ 2583301630 0;
BA_ "SAE_Document" BO_ 2583499518 "NMEA2000";
BA_ "GenMsgCycleTime" BO_ 2583499518 1000;
BA_ "SingleFrame" BO_ 2583499518 0;
BA_ "SAE_Document" BO_ 2381906942 "NMEA2000";
BA_ "GenMsgCycleTime" BO_ 2381906942 1000;
BA_ "SAE_Document" BO_ 2582648574 "NMEA2000";
BA_ "SingleFrame" BO_ 2582648574 0;
BA_ "SAE_Document" BO_ 2583238398 "NMEA2000";
BA_ "SingleFrame" BO_ 2583238398 0;
BA_ "SAE_Document" BO_ 2381450750 "NMEA2000";
BA_ "SAE_Document" BO_ 2582779134 "NMEA2000";
BA_ "GenMsgCycleTime" BO_ 2582779134 1500;
BA_ "SAE_Document" BO_ 2381388286 "NMEA2000";
BA_ "GenMsgCycleTime" BO_ 2381388286 1000;
BA_ "SAE_Document" BO_ 2314732798 "NMEA2000";
BA_ "GenMsgCycleTime" BO_ 2314732798 100;
BA_ "GenMsgRequestable" BO_ 2314732798 0;
BA_ "SAE_Document" BO_ 2650474750 "NMEA2000";
BA_ "SingleFrame" BO_ 2650474750 0;
BA_ "GenMsgRequestable" BO_ 2650474750 0;
BA_ "SAE_Document" BO_ 2650472958 "NMEA2000";
BA_ "SingleFrame" BO_ 2650472958 0;
BA_ "GenMsgRequestable" BO_ 2650472958 0;
BA_ "SAE_Document" BO_ 2650475262 "NMEA2000";
BA_ "SingleFrame" BO_ 2650475262 0;
BA_ "GenMsgRequestable" BO_ 2650475262 0;
BA_ "SAE_Document" BO_ 2650474238 "NMEA2000";
BA_ "SingleFrame" BO_ 2650474238 0;
BA_ "GenMsgRequestable" BO_ 2650474238 0;
BA_ "SAE_Document" BO_ 2650475518 "NMEA2000";
BA_ "SingleFrame" BO_ 2650475518 0;
BA_ "GenMsgRequestable" BO_ 2650475518 0;
BA_ "SAE_Document" BO_ 2650476030 "NMEA2000";
BA_ "SingleFrame" BO_ 2650476030 0;
BA_ "GenMsgRequestable" BO_ 2650476030 0;
BA_ "SAE_Document" BO_ 2583363838 "NMEA2000";
BA_ "SingleFrame" BO_ 2583363838 0;
BA_ "GenMsgRequestable" BO_ 2583363838 0;
BA_ "SAE_Document" BO_ 2650473214 "NMEA2000";
BA_ "SingleFrame" BO_ 2650473214 0;
BA_ "GenMsgRequestable" BO_ 2650473214 0;
BA_ "SAE_Document" BO_ 2448953342 "NMEA2000";
BA_ "SingleFrame" BO_ 2448953342 0;
BA_ "GenMsgRequestable" BO_ 2448953342 0;
BA_ "SAE_Document" BO_ 2448953598 "NMEA2000";
BA_ "SingleFrame" BO_ 2448953598 0;
BA_ "GenMsgRequestable" BO_ 2448953598 0;
BA_ "SAE_Document" BO_ 2448953086 "NMEA2000";
BA_ "SingleFrame" BO_ 2448953086 0;
BA_ "GenMsgRequestable" BO_ 2448953086 0;
BA_ "SAE_Document" BO_ 2650473982 "NMEA2000";
BA_ "SingleFrame" BO_ 2650473982 0;
BA_ "GenMsgRequestable" BO_ 2650473982 0;
BA_ "SAE_Document" BO_ 2650475774 "NMEA2000";
BA_ "SingleFrame" BO_ 2650475774 0;
BA_ "GenMsgRequestable" BO_ 2650475774 0;
BA_ "SAE_Document" BO_ 2650475006 "NMEA2000";
BA_ "SingleFrame" BO_ 2650475006 0;
BA_ "GenMsgRequestable" BO_ 2650475006 0;
BA_ "SAE_Document" BO_ 2650473470 "NMEA2000";
BA_ "SingleFrame" BO_ 2650473470 0;
BA_ "GenMsgRequestable" BO_ 2650473470 0;
BA_ "SAE_Document" BO_ 2650473726 "NMEA2000";
BA_ "SingleFrame" BO_ 2650473726 0;
BA_ "GenMsgRequestable" BO_ 2650473726 0;
BA_ "GenMsgCycleTime" BO_ 2365475070 100;
BA_ "SAEDocument" SG_ 2583299326 PRNStatusN "NMEA2000";
BA_ "SAEDocument" SG_ 2583299326 RangeResidualsN "NMEA2000";
BA_ "SigType" SG_ 2583299326 RangeResidualsN 2;
BA_ "SAEDocument" SG_ 2583299326 SNRN "NMEA2000";
BA_ "SigType" SG_ 2583299326 SNRN 2;
BA_ "SAEDocument" SG_ 2583299326 AzimuthN "NMEA2000";
BA_ "SigType" SG_ 2583299326 AzimuthN 1;
BA_ "SAEDocument" SG_ 2583299326 ElevationN "NMEA2000";
BA_ "SigType" SG_ 2583299326 ElevationN 2;
BA_ "SAEDocument" SG_ 2583299326 PRNN "NMEA2000";
BA_ "SigType" SG_ 2583299326 PRNN 1;
BA_ "SAEDocument" SG_ 2583299326 PRNStatus1 "NMEA2000";
BA_ "SAEDocument" SG_ 2583299326 RangeResiduals1 "NMEA2000";
BA_ "SigType" SG_ 2583299326 RangeResiduals1 2;
BA_ "SAEDocument" SG_ 2583299326 SNR1 "NMEA2000";
BA_ "SigType" SG_ 2583299326 SNR1 2;
BA_ "SAEDocument" SG_ 2583299326 Azimuth1 "NMEA2000";
BA_ "SigType" SG_ 2583299326 Azimuth1 1;
BA_ "SAEDocument" SG_ 2583299326 Elevation1 "NMEA2000";
BA_ "SigType" SG_ 2583299326 Elevation1 2;
BA_ "SAEDocument" SG_ 2583299326 PRN1 "NMEA2000";
BA_ "SigType" SG_ 2583299326 PRN1 1;
BA_ "SAEDocument" SG_ 2583299326 NumberOfSVs_ "NMEA2000";
BA_ "SigType" SG_ 2583299326 NumberOfSVs_ 1;
BA_ "SAEDocument" SG_ 2583299326 SID "NMEA2000";
BA_ "SigType" SG_ 2583299326 SID 1;
BA_ "SAEDocument" SG_ 2583299326 RangeResidualMode "NMEA2000";
BA_ "SigType" SG_ 2583299326 RangeResidualMode 4;
BA_ "SAEDocument" SG_ 2583300862 PsdrngRsdlFilteringTimeConstant "NMEA2000";
BA_ "SigType" SG_ 2583300862 PsdrngRsdlFilteringTimeConstant 1;
BA_ "SAEDocument" SG_ 2583300862 ProbabilityOfMissedDetection "NMEA2000";
BA_ "SigType" SG_ 2583300862 ProbabilityOfMissedDetection 2;
BA_ "SAEDocument" SG_ 2583300862 ProbabilityOfFalseAlarm "NMEA2000";
BA_ "SigType" SG_ 2583300862 ProbabilityOfFalseAlarm 2;
BA_ "SAEDocument" SG_ 2583300862 RadialPosErrorMaxThreshold "NMEA2000";
BA_ "SigType" SG_ 2583300862 RadialPosErrorMaxThreshold 1;
BA_ "SAEDocument" SG_ 2583300606 StdDeviationOfBias "NMEA2000";
BA_ "SigType" SG_ 2583300606 StdDeviationOfBias 2;
BA_ "SAEDocument" SG_ 2583300606 EstimateOfPseudorangeBias "NMEA2000";
BA_ "SigType" SG_ 2583300606 EstimateOfPseudorangeBias 2;
BA_ "SAEDocument" SG_ 2583300606 ProbabilityOfMissedDetection "NMEA2000";
BA_ "SigType" SG_ 2583300606 ProbabilityOfMissedDetection 2;
BA_ "SAEDocument" SG_ 2583300606 SVIDOfMostLikelyFailedSat "NMEA2000";
BA_ "SigType" SG_ 2583300606 SVIDOfMostLikelyFailedSat 1;
BA_ "SAEDocument" SG_ 2583300606 AltitudeExpectedError "NMEA2000";
BA_ "SigType" SG_ 2583300606 AltitudeExpectedError 2;
BA_ "SAEDocument" SG_ 2583300606 LongitudeExpectedError "NMEA2000";
BA_ "SigType" SG_ 2583300606 LongitudeExpectedError 2;
BA_ "SAEDocument" SG_ 2583300606 LatitudeExpectedError "NMEA2000";
BA_ "SigType" SG_ 2583300606 LatitudeExpectedError 2;
BA_ "SAEDocument" SG_ 2583300606 IntegrityFlag "NMEA2000";
BA_ "SAEDocument" SG_ 2583300606 SequenceID_ "NMEA2000";
BA_ "SigType" SG_ 2583300606 SequenceID_ 1;
BA_ "SAEDocument" SG_ 2583299838 STDOfAltError "NMEA2000";
BA_ "SigType" SG_ 2583299838 STDOfAltError 1;
BA_ "SAEDocument" SG_ 2583299838 STDOfLonError "NMEA2000";
BA_ "SigType" SG_ 2583299838 STDOfLonError 1;
BA_ "SAEDocument" SG_ 2583299838 STDOfLatError "NMEA2000";
BA_ "SigType" SG_ 2583299838 STDOfLatError 1;
BA_ "SAEDocument" SG_ 2583299838 OrientationOfMajorAxis "NMEA2000";
BA_ "SigType" SG_ 2583299838 OrientationOfMajorAxis 1;
BA_ "SAEDocument" SG_ 2583299838 STDOfMinorAxis "NMEA2000";
BA_ "SigType" SG_ 2583299838 STDOfMinorAxis 1;
BA_ "SAEDocument" SG_ 2583299838 STDOfMajorAxis "NMEA2000";
BA_ "SigType" SG_ 2583299838 STDOfMajorAxis 1;
BA_ "SAEDocument" SG_ 2583299838 RMSOfPosUncertainty "NMEA2000";
BA_ "SigType" SG_ 2583299838 RMSOfPosUncertainty 1;
BA_ "SAEDocument" SG_ 2583299838 SID "NMEA2000";
BA_ "SigType" SG_ 2583299838 SID 1;
BA_ "SAEDocument" SG_ 2583301118 StdDevAltitudeError "NMEA2000";
BA_ "SigType" SG_ 2583301118 StdDevAltitudeError 1;
BA_ "SAEDocument" SG_ 2583301118 StdDevLongitudeError "NMEA2000";
BA_ "SigType" SG_ 2583301118 StdDevLongitudeError 1;
BA_ "SAEDocument" SG_ 2583301118 StdDevLatitudeError "NMEA2000";
BA_ "SigType" SG_ 2583301118 StdDevLatitudeError 1;
BA_ "SAEDocument" SG_ 2583301118 OrientationOfErrorEllipse "NMEA2000";
BA_ "SigType" SG_ 2583301118 OrientationOfErrorEllipse 1;
BA_ "SAEDocument" SG_ 2583301118 StdDevMinorErrorEllipse "NMEA2000";
BA_ "SigType" SG_ 2583301118 StdDevMinorErrorEllipse 1;
BA_ "SAEDocument" SG_ 2583301118 StdDevMajorErrorEllipse "NMEA2000";
BA_ "SigType" SG_ 2583301118 StdDevMajorErrorEllipse 1;
BA_ "SAEDocument" SG_ 2583301118 RMSStdDevOfRangeInputs "NMEA2000";
BA_ "SigType" SG_ 2583301118 RMSStdDevOfRangeInputs 1;
BA_ "SAEDocument" SG_ 2583301118 SequenceID_ "NMEA2000";
BA_ "SigType" SG_ 2583301118 SequenceID_ 1;
BA_ "SAEDocument" SG_ 2381841918 AgeOfDGNSSReferenceStationN "NMEA2000";
BA_ "SigType" SG_ 2381841918 AgeOfDGNSSReferenceStationN 1;
BA_ "SAEDocument" SG_ 2381841918 ReferenceStationIDN "NMEA2000";
BA_ "SigType" SG_ 2381841918 ReferenceStationIDN 1;
BA_ "SAEDocument" SG_ 2381841918 ReferenceStationTypeN "NMEA2000";
BA_ "SAEDocument" SG_ 2381841918 AgeOfDGNSSCorrections1_ "NMEA2000";
BA_ "SigType" SG_ 2381841918 AgeOfDGNSSCorrections1_ 1;
BA_ "SAEDocument" SG_ 2381841918 ReferenceStationID1_ "NMEA2000";
BA_ "SigType" SG_ 2381841918 ReferenceStationID1_ 1;
BA_ "SAEDocument" SG_ 2381841918 ReferenceStationType1 "NMEA2000";
BA_ "SAEDocument" SG_ 2381841918 NumberOfReferenceStations_ "NMEA2000";
BA_ "SigType" SG_ 2381841918 NumberOfReferenceStations_ 1;
BA_ "SAEDocument" SG_ 2381841918 GeoidalSeparation_ "NMEA2000";
BA_ "SigType" SG_ 2381841918 GeoidalSeparation_ 2;
BA_ "SAEDocument" SG_ 2381841918 PDOP_ "NMEA2000";
BA_ "SigType" SG_ 2381841918 PDOP_ 2;
BA_ "SAEDocument" SG_ 2381841918 HDOP_ "NMEA2000";
BA_ "SigType" SG_ 2381841918 HDOP_ 2;
BA_ "SAEDocument" SG_ 2381841918 NumberOfSVs_ "NMEA2000";
BA_ "SigType" SG_ 2381841918 NumberOfSVs_ 1;
BA_ "SAEDocument" SG_ 2381841918 Integrity "NMEA2000";
BA_ "SAEDocument" SG_ 2381841918 MethodGNSS "NMEA2000";
BA_ "SAEDocument" SG_ 2381841918 TypeOfSystem_ "NMEA2000";
BA_ "SAEDocument" SG_ 2381841918 Altitude_high "NMEA2000";
BA_ "SigType" SG_ 2381841918 Altitude_high 2;
BA_ "SAEDocument" SG_ 2381841918 Altitude_low "NMEA2000";
BA_ "SigType" SG_ 2381841918 Altitude_low 1;
BA_ "SAEDocument" SG_ 2381841918 Longitude_high "NMEA2000";
BA_ "SigType" SG_ 2381841918 Longitude_high 2;
BA_ "SAEDocument" SG_ 2381841918 Longitude_low "NMEA2000";
BA_ "SigType" SG_ 2381841918 Longitude_low 1;
BA_ "SAEDocument" SG_ 2381841918 Latitude_high "NMEA2000";
BA_ "SigType" SG_ 2381841918 Latitude_high 2;
BA_ "SAEDocument" SG_ 2381841918 Latitude_low "NMEA2000";
BA_ "SigType" SG_ 2381841918 Latitude_low 1;
BA_ "SAEDocument" SG_ 2381841918 PosTime "NMEA2000";
BA_ "SigType" SG_ 2381841918 PosTime 1;
BA_ "SAEDocument" SG_ 2381841918 PosDate "NMEA2000";
BA_ "SigType" SG_ 2381841918 PosDate 1;
BA_ "SAEDocument" SG_ 2381841918 SID "NMEA2000";
BA_ "SigType" SG_ 2381841918 SID 1;
BA_ "SAEDocument" SG_ 2583301886 DiffOperationMode "NMEA2000";
BA_ "SAEDocument" SG_ 2583301886 DiffSource "NMEA2000";
BA_ "SAEDocument" SG_ 2583301886 SerialInterfaceDetectionMode "NMEA2000";
BA_ "SAEDocument" SG_ 2583301886 SerialInterfaceBitRate "NMEA2000";
BA_ "SAEDocument" SG_ 2583301886 Frequency "NMEA2000";
BA_ "SigType" SG_ 2583301886 Frequency 1;
BA_ "SAEDocument" SG_ 2583301886 Channel "NMEA2000";
BA_ "SigType" SG_ 2583301886 Channel 1;
BA_ "SAEDocument" SG_ 2583302142 SatelliteServiceIDNo "NMEA2000";
BA_ "SigType" SG_ 2583302142 SatelliteServiceIDNo 1;
BA_ "SAEDocument" SG_ 2583302142 TimeSinceLastSatDiffSync "NMEA2000";
BA_ "SigType" SG_ 2583302142 TimeSinceLastSatDiffSync 1;
BA_ "SAEDocument" SG_ 2583302142 DiffSource "NMEA2000";
BA_ "SAEDocument" SG_ 2583302142 UsedAsCorrectionSource "NMEA2000";
BA_ "SigType" SG_ 2583302142 UsedAsCorrectionSource 4;
BA_ "SAEDocument" SG_ 2583302142 DiffSignalDetectionMode "NMEA2000";
BA_ "SAEDocument" SG_ 2583302142 DiffSignalBitRate "NMEA2000";
BA_ "SAEDocument" SG_ 2583302142 StationID "NMEA2000";
BA_ "SigType" SG_ 2583302142 StationID 1;
BA_ "SAEDocument" SG_ 2583302142 StationType "NMEA2000";
BA_ "SAEDocument" SG_ 2583302142 Frequency "NMEA2000";
BA_ "SigType" SG_ 2583302142 Frequency 1;
BA_ "SAEDocument" SG_ 2583302142 SignalSNR "NMEA2000";
BA_ "SigType" SG_ 2583302142 SignalSNR 2;
BA_ "SAEDocument" SG_ 2583302142 SignalStrength "NMEA2000";
BA_ "SigType" SG_ 2583302142 SignalStrength 2;
BA_ "SAEDocument" SG_ 2583302142 Channel "NMEA2000";
BA_ "SigType" SG_ 2583302142 Channel 1;
BA_ "SAEDocument" SG_ 2583302142 SID "NMEA2000";
BA_ "SigType" SG_ 2583302142 SID 1;
BA_ "SAEDocument" SG_ 2583299070 TDOP "NMEA2000";
BA_ "SigType" SG_ 2583299070 TDOP 2;
BA_ "SAEDocument" SG_ 2583299070 VDOP "NMEA2000";
BA_ "SigType" SG_ 2583299070 VDOP 2;
BA_ "SAEDocument" SG_ 2583299070 HDOP_ "NMEA2000";
BA_ "SigType" SG_ 2583299070 HDOP_ 2;
BA_ "SAEDocument" SG_ 2583299070 OpMode "NMEA2000";
BA_ "SAEDocument" SG_ 2583299070 SetMode "NMEA2000";
BA_ "SAEDocument" SG_ 2583299070 SID "NMEA2000";
BA_ "SigType" SG_ 2583299070 SID 1;
BA_ "SAEDocument" SG_ 2583298814 UseAntennaAltitudeFor2DMode "NMEA2000";
BA_ "SigType" SG_ 2583298814 UseAntennaAltitudeFor2DMode 4;
BA_ "SAEDocument" SG_ 2583298814 AntennaAltitudeFor2DMode "NMEA2000";
BA_ "SigType" SG_ 2583298814 AntennaAltitudeFor2DMode 2;
BA_ "SAEDocument" SG_ 2583298814 MaxCorrectionAge "NMEA2000";
BA_ "SigType" SG_ 2583298814 MaxCorrectionAge 1;
BA_ "SAEDocument" SG_ 2583298814 Pos_VelocityFilter "NMEA2000";
BA_ "SigType" SG_ 2583298814 Pos_VelocityFilter 4;
BA_ "SAEDocument" SG_ 2583298814 DGNSSMode "NMEA2000";
BA_ "SAEDocument" SG_ 2583298814 GNSSMode "NMEA2000";
BA_ "SAEDocument" SG_ 2583298814 SNRMask "NMEA2000";
BA_ "SigType" SG_ 2583298814 SNRMask 2;
BA_ "SAEDocument" SG_ 2583298814 PDOPSwitch "NMEA2000";
BA_ "SigType" SG_ 2583298814 PDOPSwitch 2;
BA_ "SAEDocument" SG_ 2583298814 PDOPMask "NMEA2000";
BA_ "SigType" SG_ 2583298814 PDOPMask 2;
BA_ "SAEDocument" SG_ 2583298814 SVElevationMask "NMEA2000";
BA_ "SigType" SG_ 2583298814 SVElevationMask 2;
BA_ "SAEDocument" SG_ 2583303422 tnA2 "NMEA2000";
BA_ "SigType" SG_ 2583303422 tnA2 1;
BA_ "SAEDocument" SG_ 2583303422 tcA "NMEA2000";
BA_ "SigType" SG_ 2583303422 tcA 1;
BA_ "SAEDocument" SG_ 2583303422 inA "NMEA2000";
BA_ "SigType" SG_ 2583303422 inA 1;
BA_ "SAEDocument" SG_ 2583303422 nA3 "NMEA2000";
BA_ "SigType" SG_ 2583303422 nA3 1;
BA_ "SAEDocument" SG_ 2583303422 tnA "NMEA2000";
BA_ "SigType" SG_ 2583303422 tnA 1;
BA_ "SAEDocument" SG_ 2583303422 TnA "NMEA2000";
BA_ "SigType" SG_ 2583303422 TnA 1;
BA_ "SAEDocument" SG_ 2583303422 nA2 "NMEA2000";
BA_ "SigType" SG_ 2583303422 nA2 1;
BA_ "SAEDocument" SG_ 2583303422 DOT "NMEA2000";
BA_ "SigType" SG_ 2583303422 DOT 1;
BA_ "SAEDocument" SG_ 2583303422 nA "NMEA2000";
BA_ "SigType" SG_ 2583303422 nA 1;
BA_ "SAEDocument" SG_ 2583303422 HnA "NMEA2000";
BA_ "SAEDocument" SG_ 2583303422 CnA "NMEA2000";
BA_ "SAEDocument" SG_ 2583303422 NA "NMEA2000";
BA_ "SigType" SG_ 2583303422 NA 1;
BA_ "SAEDocument" SG_ 2583303422 PRN "NMEA2000";
BA_ "SigType" SG_ 2583303422 PRN 1;
BA_ "SAEDocument" SG_ 2582778366 TankCapacity "NMEA2000";
BA_ "SigType" SG_ 2582778366 TankCapacity 1;
BA_ "SAEDocument" SG_ 2582778366 FluidLevel "NMEA2000";
BA_ "SigType" SG_ 2582778366 FluidLevel 2;
BA_ "SAEDocument" SG_ 2582778366 FluidType "NMEA2000";
BA_ "SAEDocument" SG_ 2582778366 FluidInstance "NMEA2000";
BA_ "SAEDocument" SG_ 2516387838 AtmosphericPress "NMEA2000";
BA_ "SigType" SG_ 2516387838 AtmosphericPress 1;
BA_ "SAEDocument" SG_ 2516387838 Humidity "NMEA2000";
BA_ "SigType" SG_ 2516387838 Humidity 2;
BA_ "SAEDocument" SG_ 2516387838 Temp "NMEA2000";
BA_ "SigType" SG_ 2516387838 Temp 1;
BA_ "SAEDocument" SG_ 2516387838 HumidityInstance "NMEA2000";
BA_ "SigType" SG_ 2516387838 HumidityInstance 4;
BA_ "SAEDocument" SG_ 2516387838 TempInstance "NMEA2000";
BA_ "SAEDocument" SG_ 2516387838 SequenceID_ "NMEA2000";
BA_ "SigType" SG_ 2516387838 SequenceID_ 1;
BA_ "SAEDocument" SG_ 2516387582 AtmosphericPress "NMEA2000";
BA_ "SigType" SG_ 2516387582 AtmosphericPress 1;
BA_ "SAEDocument" SG_ 2516387582 OutsideAmbientAirTemp "NMEA2000";
BA_ "SigType" SG_ 2516387582 OutsideAmbientAirTemp 1;
BA_ "SAEDocument" SG_ 2516387582 WaterTemp "NMEA2000";
BA_ "SigType" SG_ 2516387582 WaterTemp 1;
BA_ "SAEDocument" SG_ 2516387582 SequenceID_ "NMEA2000";
BA_ "SigType" SG_ 2516387582 SequenceID_ 1;
BA_ "SAEDocument" SG_ 2515667710 VIN "NMEA2000";
BA_ "SigType" SG_ 2515667710 VIN 1;
BA_ "SAEDocument" SG_ 2515667710 RatedEngSpeed "NMEA2000";
BA_ "SigType" SG_ 2515667710 RatedEngSpeed 1;
BA_ "SAEDocument" SG_ 2515667710 EngInstance "NMEA2000";
BA_ "SigType" SG_ 2515667710 EngInstance 1;
BA_ "SAEDocument" SG_ 2314338558 EngTilt_Trim "NMEA2000";
BA_ "SigType" SG_ 2314338558 EngTilt_Trim 2;
BA_ "SAEDocument" SG_ 2314338558 EngBoostPress "NMEA2000";
BA_ "SigType" SG_ 2314338558 EngBoostPress 1;
BA_ "SAEDocument" SG_ 2314338558 EngSpeed_ "NMEA2000";
BA_ "SigType" SG_ 2314338558 EngSpeed_ 1;
BA_ "SAEDocument" SG_ 2314338558 EngInstance "NMEA2000";
BA_ "SigType" SG_ 2314338558 EngInstance 1;
BA_ "SAEDocument" SG_ 2314338814 PercentEngTorque "NMEA2000";
BA_ "SigType" SG_ 2314338814 PercentEngTorque 2;
BA_ "SAEDocument" SG_ 2314338814 PercentEngLoad "NMEA2000";
BA_ "SigType" SG_ 2314338814 PercentEngLoad 2;
BA_ "SAEDocument" SG_ 2314338814 EngDiscreteStatus2 "NMEA2000";
BA_ "SigType" SG_ 2314338814 EngDiscreteStatus2 1;
BA_ "SAEDocument" SG_ 2314338814 EngDiscreteStatus1 "NMEA2000";
BA_ "SigType" SG_ 2314338814 EngDiscreteStatus1 1;
BA_ "SAEDocument" SG_ 2314338814 FuelPress "NMEA2000";
BA_ "SigType" SG_ 2314338814 FuelPress 1;
BA_ "SAEDocument" SG_ 2314338814 EngCoolantPress_ "NMEA2000";
BA_ "SigType" SG_ 2314338814 EngCoolantPress_ 1;
BA_ "SAEDocument" SG_ 2314338814 TotalEngHours "NMEA2000";
BA_ "SigType" SG_ 2314338814 TotalEngHours 1;
BA_ "SAEDocument" SG_ 2314338814 FuelRate "NMEA2000";
BA_ "SigType" SG_ 2314338814 FuelRate 2;
BA_ "SAEDocument" SG_ 2314338814 AltPotential "NMEA2000";
BA_ "SigType" SG_ 2314338814 AltPotential 2;
BA_ "SAEDocument" SG_ 2314338814 EngTemp "NMEA2000";
BA_ "SigType" SG_ 2314338814 EngTemp 1;
BA_ "SAEDocument" SG_ 2314338814 EngOilTemp "NMEA2000";
BA_ "SigType" SG_ 2314338814 EngOilTemp 1;
BA_ "SAEDocument" SG_ 2314338814 EngOilPress_ "NMEA2000";
BA_ "SigType" SG_ 2314338814 EngOilPress_ 1;
BA_ "SAEDocument" SG_ 2314338814 EngInstance "NMEA2000";
BA_ "SigType" SG_ 2314338814 EngInstance 1;
BA_ "SAEDocument" SG_ 2582975486 DistanceSinceLastReset "NMEA2000";
BA_ "SigType" SG_ 2582975486 DistanceSinceLastReset 1;
BA_ "SAEDocument" SG_ 2582975486 TotalCumulativeDistance "NMEA2000";
BA_ "SigType" SG_ 2582975486 TotalCumulativeDistance 1;
BA_ "SAEDocument" SG_ 2582975486 MeasurementTime "NMEA2000";
BA_ "SigType" SG_ 2582975486 MeasurementTime 1;
BA_ "SAEDocument" SG_ 2582975486 MeasurementDate "NMEA2000";
BA_ "SigType" SG_ 2582975486 MeasurementDate 1;
BA_ "SAEDocument" SG_ 2382238206 Drift "NMEA2000";
BA_ "SigType" SG_ 2382238206 Drift 1;
BA_ "SAEDocument" SG_ 2382238206 Set "NMEA2000";
BA_ "SigType" SG_ 2382238206 Set 1;
BA_ "SAEDocument" SG_ 2382238206 SpeedThroughWater "NMEA2000";
BA_ "SigType" SG_ 2382238206 SpeedThroughWater 1;
BA_ "SAEDocument" SG_ 2382238206 Heading "NMEA2000";
BA_ "SigType" SG_ 2382238206 Heading 1;
BA_ "SAEDocument" SG_ 2382238206 SpeedOverGround "NMEA2000";
BA_ "SigType" SG_ 2382238206 SpeedOverGround 1;
BA_ "SAEDocument" SG_ 2382238206 CourseOverGround "NMEA2000";
BA_ "SigType" SG_ 2382238206 CourseOverGround 1;
BA_ "SAEDocument" SG_ 2382238206 SID "NMEA2000";
BA_ "SigType" SG_ 2382238206 SID 1;
BA_ "SAEDocument" SG_ 2382238206 Set_COG_HeadingRef "NMEA2000";
BA_ "SigType" SG_ 2382238206 Set_COG_HeadingRef 4;
BA_ "SAEDocument" SG_ 2382238206 DataMode "NMEA2000";
BA_ "SAEDocument" SG_ 2583172350 LocalDatum "NMEA2000";
BA_ "SigType" SG_ 2583172350 LocalDatum 1;
BA_ "SAEDocument" SG_ 2449150206 DSCMsgAddress "NMEA2000";
BA_ "SigType" SG_ 2449150206 DSCMsgAddress 1;
BA_ "SAEDocument" SG_ 2449150206 DSCCategorySymbol "NMEA2000";
BA_ "SigType" SG_ 2449150206 DSCCategorySymbol 1;
BA_ "SAEDocument" SG_ 2449150206 DSCFormatSymbol "NMEA2000";
BA_ "SigType" SG_ 2449150206 DSCFormatSymbol 1;
BA_ "SAEDocument" SG_ 2583301630 IOD "NMEA2000";
BA_ "SigType" SG_ 2583301630 IOD 1;
BA_ "SAEDocument" SG_ 2583301630 UDRE "NMEA2000";
BA_ "SigType" SG_ 2583301630 UDRE 1;
BA_ "SAEDocument" SG_ 2583301630 RRC "NMEA2000";
BA_ "SigType" SG_ 2583301630 RRC 2;
BA_ "SAEDocument" SG_ 2583301630 PRC "NMEA2000";
BA_ "SigType" SG_ 2583301630 PRC 2;
BA_ "SAEDocument" SG_ 2583301630 SatelliteID "NMEA2000";
BA_ "SigType" SG_ 2583301630 SatelliteID 1;
BA_ "SAEDocument" SG_ 2583301630 StationHealth "NMEA2000";
BA_ "SAEDocument" SG_ 2583301630 TimeOfCorrections "NMEA2000";
BA_ "SigType" SG_ 2583301630 TimeOfCorrections 1;
BA_ "SAEDocument" SG_ 2583301630 ReferenceStationType "NMEA2000";
BA_ "SAEDocument" SG_ 2583301630 ReferenceStationID "NMEA2000";
BA_ "SigType" SG_ 2583301630 ReferenceStationID 1;
BA_ "SAEDocument" SG_ 2583301630 SequenceID_ "NMEA2000";
BA_ "SigType" SG_ 2583301630 SequenceID_ 1;
BA_ "SAEDocument" SG_ 2583499518 StationIDString "NMEA2000";
BA_ "SigType" SG_ 2583499518 StationIDString 1;
BA_ "SAEDocument" SG_ 2583499518 WaterTemp "NMEA2000";
BA_ "SigType" SG_ 2583499518 WaterTemp 1;
BA_ "SAEDocument" SG_ 2583499518 CurrentFlowDirection "NMEA2000";
BA_ "SigType" SG_ 2583499518 CurrentFlowDirection 1;
BA_ "SAEDocument" SG_ 2583499518 CurrentSpeed "NMEA2000";
BA_ "SigType" SG_ 2583499518 CurrentSpeed 1;
BA_ "SAEDocument" SG_ 2583499518 MeasurementDepth "NMEA2000";
BA_ "SigType" SG_ 2583499518 MeasurementDepth 1;
BA_ "SAEDocument" SG_ 2583499518 StationLocationLongitude "NMEA2000";
BA_ "SigType" SG_ 2583499518 StationLocationLongitude 2;
BA_ "SAEDocument" SG_ 2583499518 StationLocationLatitude "NMEA2000";
BA_ "SigType" SG_ 2583499518 StationLocationLatitude 2;
BA_ "SAEDocument" SG_ 2583499518 MeasurementTime "NMEA2000";
BA_ "SigType" SG_ 2583499518 MeasurementTime 1;
BA_ "SAEDocument" SG_ 2583499518 MeasurementDate "NMEA2000";
BA_ "SigType" SG_ 2583499518 MeasurementDate 1;
BA_ "SAEDocument" SG_ 2583499518 State "NMEA2000";
BA_ "SAEDocument" SG_ 2583499518 Mode "NMEA2000";
BA_ "SAEDocument" SG_ 2381906942 XTE "NMEA2000";
BA_ "SigType" SG_ 2381906942 XTE 2;
BA_ "SAEDocument" SG_ 2381906942 NavigationTerminated "NMEA2000";
BA_ "SigType" SG_ 2381906942 NavigationTerminated 4;
BA_ "SAEDocument" SG_ 2381906942 XTEMode "NMEA2000";
BA_ "SAEDocument" SG_ 2381906942 SID "NMEA2000";
BA_ "SigType" SG_ 2381906942 SID 1;
BA_ "SAEDocument" SG_ 2582648574 InstallationDescriptionField1 "NMEA2000";
BA_ "SigType" SG_ 2582648574 InstallationDescriptionField1 1;
BA_ "SAEDocument" SG_ 2583238398 DestinationMarkID "NMEA2000";
BA_ "SigType" SG_ 2583238398 DestinationMarkID 1;
BA_ "SAEDocument" SG_ 2583238398 OriginMarkId "NMEA2000";
BA_ "SigType" SG_ 2583238398 OriginMarkId 1;
BA_ "SAEDocument" SG_ 2583238398 DestinationMarkType "NMEA2000";
BA_ "SAEDocument" SG_ 2583238398 OriginMarkType "NMEA2000";
BA_ "SAEDocument" SG_ 2583238398 Distance "NMEA2000";
BA_ "SigType" SG_ 2583238398 Distance 2;
BA_ "SAEDocument" SG_ 2583238398 BearingiginToDestination "NMEA2000";
BA_ "SigType" SG_ 2583238398 BearingiginToDestination 1;
BA_ "SAEDocument" SG_ 2583238398 CalculationType "NMEA2000";
BA_ "SigType" SG_ 2583238398 CalculationType 4;
BA_ "SAEDocument" SG_ 2583238398 BearingRef "NMEA2000";
BA_ "SAEDocument" SG_ 2583238398 SID "NMEA2000";
BA_ "SigType" SG_ 2583238398 SID 1;
BA_ "SAEDocument" SG_ 2381450750 Indic28 "NMEA2000";
BA_ "SigType" SG_ 2381450750 Indic28 4;
BA_ "SAEDocument" SG_ 2381450750 Indic27 "NMEA2000";
BA_ "SigType" SG_ 2381450750 Indic27 4;
BA_ "SAEDocument" SG_ 2381450750 Indic26 "NMEA2000";
BA_ "SigType" SG_ 2381450750 Indic26 4;
BA_ "SAEDocument" SG_ 2381450750 Indic25 "NMEA2000";
BA_ "SigType" SG_ 2381450750 Indic25 4;
BA_ "SAEDocument" SG_ 2381450750 Indic24 "NMEA2000";
BA_ "SigType" SG_ 2381450750 Indic24 4;
BA_ "SAEDocument" SG_ 2381450750 Indic23 "NMEA2000";
BA_ "SigType" SG_ 2381450750 Indic23 4;
BA_ "SAEDocument" SG_ 2381450750 Indic22 "NMEA2000";
BA_ "SigType" SG_ 2381450750 Indic22 4;
BA_ "SAEDocument" SG_ 2381450750 Indic21 "NMEA2000";
BA_ "SigType" SG_ 2381450750 Indic21 4;
BA_ "SAEDocument" SG_ 2381450750 Indic20 "NMEA2000";
BA_ "SigType" SG_ 2381450750 Indic20 4;
BA_ "SAEDocument" SG_ 2381450750 Indic19 "NMEA2000";
BA_ "SigType" SG_ 2381450750 Indic19 4;
BA_ "SAEDocument" SG_ 2381450750 Indic18 "NMEA2000";
BA_ "SigType" SG_ 2381450750 Indic18 4;
BA_ "SAEDocument" SG_ 2381450750 Indic17 "NMEA2000";
BA_ "SigType" SG_ 2381450750 Indic17 4;
BA_ "SAEDocument" SG_ 2381450750 Indic16 "NMEA2000";
BA_ "SigType" SG_ 2381450750 Indic16 4;
BA_ "SAEDocument" SG_ 2381450750 Indic15 "NMEA2000";
BA_ "SigType" SG_ 2381450750 Indic15 4;
BA_ "SAEDocument" SG_ 2381450750 Indic14 "NMEA2000";
BA_ "SigType" SG_ 2381450750 Indic14 4;
BA_ "SAEDocument" SG_ 2381450750 Indic13 "NMEA2000";
BA_ "SigType" SG_ 2381450750 Indic13 4;
BA_ "SAEDocument" SG_ 2381450750 Indic12 "NMEA2000";
BA_ "SigType" SG_ 2381450750 Indic12 4;
BA_ "SAEDocument" SG_ 2381450750 Indic11 "NMEA2000";
BA_ "SigType" SG_ 2381450750 Indic11 4;
BA_ "SAEDocument" SG_ 2381450750 Indic10 "NMEA2000";
BA_ "SigType" SG_ 2381450750 Indic10 4;
BA_ "SAEDocument" SG_ 2381450750 Indic9 "NMEA2000";
BA_ "SigType" SG_ 2381450750 Indic9 4;
BA_ "SAEDocument" SG_ 2381450750 Indic8 "NMEA2000";
BA_ "SigType" SG_ 2381450750 Indic8 4;
BA_ "SAEDocument" SG_ 2381450750 Indic7 "NMEA2000";
BA_ "SigType" SG_ 2381450750 Indic7 4;
BA_ "SAEDocument" SG_ 2381450750 Indic6 "NMEA2000";
BA_ "SigType" SG_ 2381450750 Indic6 4;
BA_ "SAEDocument" SG_ 2381450750 Indic5 "NMEA2000";
BA_ "SigType" SG_ 2381450750 Indic5 4;
BA_ "SAEDocument" SG_ 2381450750 Indic4 "NMEA2000";
BA_ "SigType" SG_ 2381450750 Indic4 4;
BA_ "SAEDocument" SG_ 2381450750 Indic3 "NMEA2000";
BA_ "SigType" SG_ 2381450750 Indic3 4;
BA_ "SAEDocument" SG_ 2381450750 Indic2 "NMEA2000";
BA_ "SigType" SG_ 2381450750 Indic2 4;
BA_ "SAEDocument" SG_ 2381450750 Indic1 "NMEA2000";
BA_ "SigType" SG_ 2381450750 Indic1 4;
BA_ "SAEDocument" SG_ 2381450750 IndicatorBankInstance "NMEA2000";
BA_ "SigType" SG_ 2381450750 IndicatorBankInstance 1;
BA_ "SAEDocument" SG_ 2582779134 SID "NMEA2000";
BA_ "SigType" SG_ 2582779134 SID 1;
BA_ "SAEDocument" SG_ 2582779134 BatteryCaseTemp "NMEA2000";
BA_ "SigType" SG_ 2582779134 BatteryCaseTemp 1;
BA_ "SAEDocument" SG_ 2582779134 BatteryCurrent "NMEA2000";
BA_ "SigType" SG_ 2582779134 BatteryCurrent 2;
BA_ "SAEDocument" SG_ 2582779134 BatteryPotential "NMEA2000";
BA_ "SigType" SG_ 2582779134 BatteryPotential 2;
BA_ "SAEDocument" SG_ 2582779134 BatteryInstance "NMEA2000";
BA_ "SigType" SG_ 2582779134 BatteryInstance 1;
BA_ "SAEDocument" SG_ 2381388286 Roll "NMEA2000";
BA_ "SigType" SG_ 2381388286 Roll 2;
BA_ "SAEDocument" SG_ 2381388286 Pitch_ "NMEA2000";
BA_ "SigType" SG_ 2381388286 Pitch_ 1;
BA_ "SAEDocument" SG_ 2381388286 Yaw "NMEA2000";
BA_ "SigType" SG_ 2381388286 Yaw 2;
BA_ "SAEDocument" SG_ 2381388286 SID "NMEA2000";
BA_ "SigType" SG_ 2381388286 SID 1;
BA_ "SAEDocument" SG_ 2314732798 AltitudeDelta "NMEA2000";
BA_ "SigType" SG_ 2314732798 AltitudeDelta 2;
BA_ "SAEDocument" SG_ 2314732798 CourseOverGround "NMEA2000";
BA_ "SigType" SG_ 2314732798 CourseOverGround 1;
BA_ "SAEDocument" SG_ 2314732798 Direction "NMEA2000";
BA_ "SigType" SG_ 2314732798 Direction 4;
BA_ "SAEDocument" SG_ 2314732798 GNSSQuality "NMEA2000";
BA_ "SAEDocument" SG_ 2314732798 TimeDelta "NMEA2000";
BA_ "SigType" SG_ 2314732798 TimeDelta 1;
BA_ "SAEDocument" SG_ 2314732798 SequenceID_ "NMEA2000";
BA_ "SigType" SG_ 2314732798 SequenceID_ 1;
BA_ "SAEDocument" SG_ 2650474750 DestinationID "NMEA2000";
BA_ "SigType" SG_ 2650474750 DestinationID 1;
BA_ "SAEDocument" SG_ 2650474750 AISTransceiverInformation "NMEA2000";
BA_ "SAEDocument" SG_ 2650474750 SourceID "NMEA2000";
BA_ "SigType" SG_ 2650474750 SourceID 1;
BA_ "SAEDocument" SG_ 2650474750 RepeatIndicator "NMEA2000";
BA_ "SAEDocument" SG_ 2650474750 MsgID "NMEA2000";
BA_ "SAEDocument" SG_ 2650472958 TypeOfElectronicPosingDevice "NMEA2000";
BA_ "SAEDocument" SG_ 2650472958 PosDate "NMEA2000";
BA_ "SigType" SG_ 2650472958 PosDate 1;
BA_ "SAEDocument" SG_ 2650472958 AISTransceiverInformation "NMEA2000";
BA_ "SAEDocument" SG_ 2650472958 CommunicationState "NMEA2000";
BA_ "SigType" SG_ 2650472958 CommunicationState 1;
BA_ "SAEDocument" SG_ 2650472958 PosTime "NMEA2000";
BA_ "SigType" SG_ 2650472958 PosTime 1;
BA_ "SAEDocument" SG_ 2650472958 RAIMflag "NMEA2000";
BA_ "SAEDocument" SG_ 2650472958 PosAccuracy "NMEA2000";
BA_ "SAEDocument" SG_ 2650472958 Latitude_ "NMEA2000";
BA_ "SigType" SG_ 2650472958 Latitude_ 2;
BA_ "SAEDocument" SG_ 2650472958 Longitude_ "NMEA2000";
BA_ "SigType" SG_ 2650472958 Longitude_ 2;
BA_ "SAEDocument" SG_ 2650472958 UserID "NMEA2000";
BA_ "SigType" SG_ 2650472958 UserID 1;
BA_ "SAEDocument" SG_ 2650472958 RepeatIndicator "NMEA2000";
BA_ "SAEDocument" SG_ 2650472958 MsgID "NMEA2000";
BA_ "SAEDocument" SG_ 2650475262 SafetyRelatedText "NMEA2000";
BA_ "SigType" SG_ 2650475262 SafetyRelatedText 1;
BA_ "SAEDocument" SG_ 2650475262 AISTransceiverInformation "NMEA2000";
BA_ "SAEDocument" SG_ 2650475262 SourceID "NMEA2000";
BA_ "SigType" SG_ 2650475262 SourceID 1;
BA_ "SAEDocument" SG_ 2650475262 RepeatIndicator "NMEA2000";
BA_ "SAEDocument" SG_ 2650475262 MsgID "NMEA2000";
BA_ "SAEDocument" SG_ 2650474238 DataTerminalEquipment "NMEA2000";
BA_ "SAEDocument" SG_ 2650474238 Altitude_ "NMEA2000";
BA_ "SigType" SG_ 2650474238 Altitude_ 2;
BA_ "SAEDocument" SG_ 2650474238 AISTransceiverInformation "NMEA2000";
BA_ "SAEDocument" SG_ 2650474238 CommunicationState "NMEA2000";
BA_ "SigType" SG_ 2650474238 CommunicationState 1;
BA_ "SAEDocument" SG_ 2650474238 SOG "NMEA2000";
BA_ "SigType" SG_ 2650474238 SOG 1;
BA_ "SAEDocument" SG_ 2650474238 COG "NMEA2000";
BA_ "SigType" SG_ 2650474238 COG 1;
BA_ "SAEDocument" SG_ 2650474238 TimeStamp "NMEA2000";
BA_ "SAEDocument" SG_ 2650474238 RAIMFlag "NMEA2000";
BA_ "SAEDocument" SG_ 2650474238 PosAccuracy "NMEA2000";
BA_ "SAEDocument" SG_ 2650474238 Latitude_ "NMEA2000";
BA_ "SigType" SG_ 2650474238 Latitude_ 2;
BA_ "SAEDocument" SG_ 2650474238 Longitude_ "NMEA2000";
BA_ "SigType" SG_ 2650474238 Longitude_ 2;
BA_ "SAEDocument" SG_ 2650474238 UserID "NMEA2000";
BA_ "SigType" SG_ 2650474238 UserID 1;
BA_ "SAEDocument" SG_ 2650474238 RepeatIndicator "NMEA2000";
BA_ "SAEDocument" SG_ 2650474238 MsgID "NMEA2000";
BA_ "SAEDocument" SG_ 2650475518 SlotOffset21 "NMEA2000";
BA_ "SigType" SG_ 2650475518 SlotOffset21 1;
BA_ "SAEDocument" SG_ 2650475518 MsgID21 "NMEA2000";
BA_ "SAEDocument" SG_ 2650475518 DestinationID2 "NMEA2000";
BA_ "SigType" SG_ 2650475518 DestinationID2 1;
BA_ "SAEDocument" SG_ 2650475518 SlotOffset12 "NMEA2000";
BA_ "SigType" SG_ 2650475518 SlotOffset12 1;
BA_ "SAEDocument" SG_ 2650475518 MsgID12 "NMEA2000";
BA_ "SAEDocument" SG_ 2650475518 SlotOffset11 "NMEA2000";
BA_ "SigType" SG_ 2650475518 SlotOffset11 1;
BA_ "SAEDocument" SG_ 2650475518 MsgID11 "NMEA2000";
BA_ "SAEDocument" SG_ 2650475518 DestinationID1 "NMEA2000";
BA_ "SigType" SG_ 2650475518 DestinationID1 1;
BA_ "SAEDocument" SG_ 2650475518 AISTransceiverInformation "NMEA2000";
BA_ "SAEDocument" SG_ 2650475518 SourceID "NMEA2000";
BA_ "SigType" SG_ 2650475518 SourceID 1;
BA_ "SAEDocument" SG_ 2650475518 RepeatIndicator "NMEA2000";
BA_ "SAEDocument" SG_ 2650475518 MsgID "NMEA2000";
BA_ "SAEDocument" SG_ 2650476030 Increment4 "NMEA2000";
BA_ "SigType" SG_ 2650476030 Increment4 1;
BA_ "SAEDocument" SG_ 2650476030 TimeOut4 "NMEA2000";
BA_ "SigType" SG_ 2650476030 TimeOut4 1;
BA_ "SAEDocument" SG_ 2650476030 NumberOfSlots4 "NMEA2000";
BA_ "SigType" SG_ 2650476030 NumberOfSlots4 1;
BA_ "SAEDocument" SG_ 2650476030 OffsetNumber4 "NMEA2000";
BA_ "SigType" SG_ 2650476030 OffsetNumber4 1;
BA_ "SAEDocument" SG_ 2650476030 Increment3 "NMEA2000";
BA_ "SigType" SG_ 2650476030 Increment3 1;
BA_ "SAEDocument" SG_ 2650476030 TimeOut3 "NMEA2000";
BA_ "SigType" SG_ 2650476030 TimeOut3 1;
BA_ "SAEDocument" SG_ 2650476030 NumberOfSlots3 "NMEA2000";
BA_ "SigType" SG_ 2650476030 NumberOfSlots3 1;
BA_ "SAEDocument" SG_ 2650476030 OffsetNumber3 "NMEA2000";
BA_ "SigType" SG_ 2650476030 OffsetNumber3 1;
BA_ "SAEDocument" SG_ 2650476030 Increment2 "NMEA2000";
BA_ "SigType" SG_ 2650476030 Increment2 1;
BA_ "SAEDocument" SG_ 2650476030 TimeOut2 "NMEA2000";
BA_ "SigType" SG_ 2650476030 TimeOut2 1;
BA_ "SAEDocument" SG_ 2650476030 NumberOfSlots2 "NMEA2000";
BA_ "SigType" SG_ 2650476030 NumberOfSlots2 1;
BA_ "SAEDocument" SG_ 2650476030 OffsetNumber2 "NMEA2000";
BA_ "SigType" SG_ 2650476030 OffsetNumber2 1;
BA_ "SAEDocument" SG_ 2650476030 Increment1 "NMEA2000";
BA_ "SigType" SG_ 2650476030 Increment1 1;
BA_ "SAEDocument" SG_ 2650476030 TimeOut1 "NMEA2000";
BA_ "SigType" SG_ 2650476030 TimeOut1 1;
BA_ "SAEDocument" SG_ 2650476030 NumberOfSlots1 "NMEA2000";
BA_ "SigType" SG_ 2650476030 NumberOfSlots1 1;
BA_ "SAEDocument" SG_ 2650476030 OffsetNumber1 "NMEA2000";
BA_ "SigType" SG_ 2650476030 OffsetNumber1 1;
BA_ "SAEDocument" SG_ 2650476030 AISTransceiverInformation "NMEA2000";
BA_ "SAEDocument" SG_ 2650476030 SourceStationID "NMEA2000";
BA_ "SigType" SG_ 2650476030 SourceStationID 1;
BA_ "SAEDocument" SG_ 2650476030 RepeatIndicator "NMEA2000";
BA_ "SAEDocument" SG_ 2650476030 MsgID "NMEA2000";
BA_ "SAEDocument" SG_ 2583363838 NumberOfBitsInBinaryDataField "NMEA2000";
BA_ "SigType" SG_ 2583363838 NumberOfBitsInBinaryDataField 1;
BA_ "SAEDocument" SG_ 2583363838 Latitude_ "NMEA2000";
BA_ "SigType" SG_ 2583363838 Latitude_ 2;
BA_ "SAEDocument" SG_ 2583363838 Longitude_ "NMEA2000";
BA_ "SigType" SG_ 2583363838 Longitude_ 2;
BA_ "SAEDocument" SG_ 2583363838 AISTransceiverInformation "NMEA2000";
BA_ "SAEDocument" SG_ 2583363838 SourceID "NMEA2000";
BA_ "SigType" SG_ 2583363838 SourceID 1;
BA_ "SAEDocument" SG_ 2583363838 RepeatIndicator "NMEA2000";
BA_ "SAEDocument" SG_ 2583363838 MsgID "NMEA2000";
BA_ "SAEDocument" SG_ 2650473214 CallSign "NMEA2000";
BA_ "SigType" SG_ 2650473214 CallSign 1;
BA_ "SAEDocument" SG_ 2650473214 IMO "NMEA2000";
BA_ "SigType" SG_ 2650473214 IMO 1;
BA_ "SAEDocument" SG_ 2650473214 UserID "NMEA2000";
BA_ "SigType" SG_ 2650473214 UserID 1;
BA_ "SAEDocument" SG_ 2650473214 RepeatIndicator "NMEA2000";
BA_ "SAEDocument" SG_ 2650473214 MsgID "NMEA2000";
BA_ "SAEDocument" SG_ 2448953342 ComminicationStateSelectorFlag "NMEA2000";
BA_ "SAEDocument" SG_ 2448953342 TrueHeading "NMEA2000";
BA_ "SigType" SG_ 2448953342 TrueHeading 1;
BA_ "SAEDocument" SG_ 2448953342 AISTransceiverInformation "NMEA2000";
BA_ "SAEDocument" SG_ 2448953342 CommunicationState "NMEA2000";
BA_ "SigType" SG_ 2448953342 CommunicationState 1;
BA_ "SAEDocument" SG_ 2448953342 SOG "NMEA2000";
BA_ "SigType" SG_ 2448953342 SOG 1;
BA_ "SAEDocument" SG_ 2448953342 COG "NMEA2000";
BA_ "SigType" SG_ 2448953342 COG 1;
BA_ "SAEDocument" SG_ 2448953342 TimeStamp "NMEA2000";
BA_ "SAEDocument" SG_ 2448953342 RAIMflag "NMEA2000";
BA_ "SAEDocument" SG_ 2448953342 PosAccuracy "NMEA2000";
BA_ "SAEDocument" SG_ 2448953342 Latitude_ "NMEA2000";
BA_ "SigType" SG_ 2448953342 Latitude_ 2;
BA_ "SAEDocument" SG_ 2448953342 Longitude_ "NMEA2000";
BA_ "SigType" SG_ 2448953342 Longitude_ 2;
BA_ "SAEDocument" SG_ 2448953342 UserID "NMEA2000";
BA_ "SigType" SG_ 2448953342 UserID 1;
BA_ "SAEDocument" SG_ 2448953342 RepeatIndicator "NMEA2000";
BA_ "SAEDocument" SG_ 2448953342 MsgID "NMEA2000";
BA_ "SAEDocument" SG_ 2448953598 Name "NMEA2000";
BA_ "SigType" SG_ 2448953598 Name 1;
BA_ "SAEDocument" SG_ 2448953598 PosReferencePointAftOfShipsBow "NMEA2000";
BA_ "SigType" SG_ 2448953598 PosReferencePointAftOfShipsBow 1;
BA_ "SAEDocument" SG_ 2448953598 PosReferencePointFromStarboard "NMEA2000";
BA_ "SigType" SG_ 2448953598 PosReferencePointFromStarboard 1;
BA_ "SAEDocument" SG_ 2448953598 ShipBeam "NMEA2000";
BA_ "SigType" SG_ 2448953598 ShipBeam 1;
BA_ "SAEDocument" SG_ 2448953598 ShipLength "NMEA2000";
BA_ "SigType" SG_ 2448953598 ShipLength 1;
BA_ "SAEDocument" SG_ 2448953598 TypeOfElectronicPosingDevice "NMEA2000";
BA_ "SAEDocument" SG_ 2448953598 TrueHeading "NMEA2000";
BA_ "SigType" SG_ 2448953598 TrueHeading 1;
BA_ "SAEDocument" SG_ 2448953598 Ship_CargoType "NMEA2000";
BA_ "SigType" SG_ 2448953598 Ship_CargoType 1;
BA_ "SAEDocument" SG_ 2448953598 SOG "NMEA2000";
BA_ "SigType" SG_ 2448953598 SOG 1;
BA_ "SAEDocument" SG_ 2448953598 COG "NMEA2000";
BA_ "SigType" SG_ 2448953598 COG 1;
BA_ "SAEDocument" SG_ 2448953598 TimeStamp "NMEA2000";
BA_ "SAEDocument" SG_ 2448953598 RAIMflag "NMEA2000";
BA_ "SAEDocument" SG_ 2448953598 PosAccuracy "NMEA2000";
BA_ "SAEDocument" SG_ 2448953598 Latitude_ "NMEA2000";
BA_ "SigType" SG_ 2448953598 Latitude_ 2;
BA_ "SAEDocument" SG_ 2448953598 Longitude_ "NMEA2000";
BA_ "SigType" SG_ 2448953598 Longitude_ 2;
BA_ "SAEDocument" SG_ 2448953598 UserID "NMEA2000";
BA_ "SigType" SG_ 2448953598 UserID 1;
BA_ "SAEDocument" SG_ 2448953598 RepeatIndicator "NMEA2000";
BA_ "SAEDocument" SG_ 2448953598 MsgID "NMEA2000";
BA_ "SAEDocument" SG_ 2448953086 NavigationalStatus "NMEA2000";
BA_ "SAEDocument" SG_ 2448953086 RateOfTurn "NMEA2000";
BA_ "SigType" SG_ 2448953086 RateOfTurn 2;
BA_ "SAEDocument" SG_ 2448953086 TrueHeading "NMEA2000";
BA_ "SigType" SG_ 2448953086 TrueHeading 1;
BA_ "SAEDocument" SG_ 2448953086 AISTransceiverInformation "NMEA2000";
BA_ "SAEDocument" SG_ 2448953086 CommunicationState "NMEA2000";
BA_ "SigType" SG_ 2448953086 CommunicationState 1;
BA_ "SAEDocument" SG_ 2448953086 SOG "NMEA2000";
BA_ "SigType" SG_ 2448953086 SOG 1;
BA_ "SAEDocument" SG_ 2448953086 COG "NMEA2000";
BA_ "SigType" SG_ 2448953086 COG 1;
BA_ "SAEDocument" SG_ 2448953086 TimeStamp "NMEA2000";
BA_ "SAEDocument" SG_ 2448953086 RAIMflag "NMEA2000";
BA_ "SAEDocument" SG_ 2448953086 PosAccuracy "NMEA2000";
BA_ "SAEDocument" SG_ 2448953086 Latitude_ "NMEA2000";
BA_ "SigType" SG_ 2448953086 Latitude_ 2;
BA_ "SAEDocument" SG_ 2448953086 Longitude_ "NMEA2000";
BA_ "SigType" SG_ 2448953086 Longitude_ 2;
BA_ "SAEDocument" SG_ 2448953086 UserID "NMEA2000";
BA_ "SigType" SG_ 2448953086 UserID 1;
BA_ "SAEDocument" SG_ 2448953086 RepeatIndicator "NMEA2000";
BA_ "SAEDocument" SG_ 2448953086 MsgID "NMEA2000";
BA_ "SAEDocument" SG_ 2650473982 NumberOfBitsInBinaryDataField "NMEA2000";
BA_ "SigType" SG_ 2650473982 NumberOfBitsInBinaryDataField 1;
BA_ "SAEDocument" SG_ 2650473982 AISTransceiverInformation "NMEA2000";
BA_ "SAEDocument" SG_ 2650473982 SourceID "NMEA2000";
BA_ "SigType" SG_ 2650473982 SourceID 1;
BA_ "SAEDocument" SG_ 2650473982 RepeatIndicator "NMEA2000";
BA_ "SAEDocument" SG_ 2650473982 MsgID "NMEA2000";
BA_ "SAEDocument" SG_ 2650475774 IncrementB "NMEA2000";
BA_ "SigType" SG_ 2650475774 IncrementB 1;
BA_ "SAEDocument" SG_ 2650475774 OffsetB "NMEA2000";
BA_ "SigType" SG_ 2650475774 OffsetB 1;
BA_ "SAEDocument" SG_ 2650475774 DestinationIDB "NMEA2000";
BA_ "SigType" SG_ 2650475774 DestinationIDB 1;
BA_ "SAEDocument" SG_ 2650475774 IncrementA "NMEA2000";
BA_ "SigType" SG_ 2650475774 IncrementA 1;
BA_ "SAEDocument" SG_ 2650475774 OffsetA "NMEA2000";
BA_ "SigType" SG_ 2650475774 OffsetA 1;
BA_ "SAEDocument" SG_ 2650475774 DestinationIDA "NMEA2000";
BA_ "SigType" SG_ 2650475774 DestinationIDA 1;
BA_ "SAEDocument" SG_ 2650475774 AISTransceiverInformation "NMEA2000";
BA_ "SAEDocument" SG_ 2650475774 SourceID "NMEA2000";
BA_ "SigType" SG_ 2650475774 SourceID 1;
BA_ "SAEDocument" SG_ 2650475774 RepeatIndicator "NMEA2000";
BA_ "SAEDocument" SG_ 2650475774 MsgID "NMEA2000";
BA_ "SAEDocument" SG_ 2650475006 SafetyRelatedText "NMEA2000";
BA_ "SigType" SG_ 2650475006 SafetyRelatedText 1;
BA_ "SAEDocument" SG_ 2650475006 RetransmitFlag "NMEA2000";
BA_ "SAEDocument" SG_ 2650475006 DestinationID "NMEA2000";
BA_ "SigType" SG_ 2650475006 DestinationID 1;
BA_ "SAEDocument" SG_ 2650475006 SequenceNumber_ "NMEA2000";
BA_ "SigType" SG_ 2650475006 SequenceNumber_ 4;
BA_ "SAEDocument" SG_ 2650475006 AISTransceiverInformation "NMEA2000";
BA_ "SAEDocument" SG_ 2650475006 SourceID "NMEA2000";
BA_ "SigType" SG_ 2650475006 SourceID 1;
BA_ "SAEDocument" SG_ 2650475006 RepeatIndicator "NMEA2000";
BA_ "SAEDocument" SG_ 2650475006 MsgID "NMEA2000";
BA_ "SAEDocument" SG_ 2650473470 NumberOfBitsInBinaryDataField "NMEA2000";
BA_ "SigType" SG_ 2650473470 NumberOfBitsInBinaryDataField 1;
BA_ "SAEDocument" SG_ 2650473470 RetransmitFlag "NMEA2000";
BA_ "SAEDocument" SG_ 2650473470 DestinationID "NMEA2000";
BA_ "SigType" SG_ 2650473470 DestinationID 1;
BA_ "SAEDocument" SG_ 2650473470 SequenceNumber_ "NMEA2000";
BA_ "SigType" SG_ 2650473470 SequenceNumber_ 4;
BA_ "SAEDocument" SG_ 2650473470 AISTransceiverInformation "NMEA2000";
BA_ "SAEDocument" SG_ 2650473470 SourceID "NMEA2000";
BA_ "SigType" SG_ 2650473470 SourceID 1;
BA_ "SAEDocument" SG_ 2650473470 RepeatIndicator "NMEA2000";
BA_ "SAEDocument" SG_ 2650473470 MsgID "NMEA2000";
BA_ "SAEDocument" SG_ 2650473726 SequenceNumberForIDn "NMEA2000";
BA_ "SigType" SG_ 2650473726 SequenceNumberForIDn 4;
BA_ "SAEDocument" SG_ 2650473726 SequenceNumberForID1 "NMEA2000";
BA_ "SigType" SG_ 2650473726 SequenceNumberForID1 4;
BA_ "SAEDocument" SG_ 2650473726 DestinationID1 "NMEA2000";
BA_ "SigType" SG_ 2650473726 DestinationID1 1;
BA_ "SAEDocument" SG_ 2650473726 AISTransceiverInformation "NMEA2000";
BA_ "SAEDocument" SG_ 2650473726 SourceID "NMEA2000";
BA_ "SigType" SG_ 2650473726 SourceID 1;
BA_ "SAEDocument" SG_ 2650473726 RepeatIndicator "NMEA2000";
BA_ "SAEDocument" SG_ 2650473726 MsgID "NMEA2000";
BA_ "SPN" SG_ 2365475070 WheelBasedMachineSpeed 1862;
BA_ "SigType" SG_ 2365475070 WheelBasedMachineSpeed 1;
BA_ "SPN" SG_ 2365475070 WheelBasedMachineDistance 1863;
BA_ "SigType" SG_ 2365475070 WheelBasedMachineDistance 1;
BA_ "SPN" SG_ 2365475070 MaxTimeOfTractorPower 1866;
BA_ "SigType" SG_ 2365475070 MaxTimeOfTractorPower 1;
BA_ "SPN" SG_ 2365475070 WheelBasedMachineDirection 1864;
BA_ "SigType" SG_ 2365475070 WheelBasedMachineDirection 4;
BA_ "SPN" SG_ 2365475070 KeySwitchState 1865;
BA_ "SigType" SG_ 2365475070 KeySwitchState 4;
BA_ "SPN" SG_ 2365475070 StartStopState 5203;
BA_ "SigType" SG_ 2365475070 StartStopState 4;
BA_ "SPN" SG_ 2365475070 OperatorDirectionReversed 5244;
BA_ "SigType" SG_ 2365475070 OperatorDirectionReversed 5;
VAL_ 2583299326 PRNStatusN 6 "Reserved14Error15NoSelection" 5 "usedWithDiffCorrections" 4 "TrackedWithDiffCorrections" 3 "DiffCorrectionsAvailable" 2 "UsdInSltnWithoutDiffCorrections" 1 "TrackedButNotUsedInSolution" 0 "Not Tracked" ;
VAL_ 2583299326 PRNN 96 "GLONASSFrGLONASSStlltsArIdntfdBy" 64 "SBASStlltBsdAgmentationSystem65" 1 "GPS, 

33-" 0 "value not used" ;
VAL_ 2583299326 PRNStatus1 6 "Reserved14Error15NoSelection" 5 "usedWithDiffCorrections" 4 "TrackedWithDiffCorrections" 3 "DiffCorrectionsAvailable" 2 "UsdInSltnWithoutDiffCorrections" 1 "TrackedButNotUsedInSolution" 0 "Not Tracked" ;
VAL_ 2583299326 PRN1 96 "GLONASSFrGLONASSStlltsArIdntfdBy" 64 "SBASStlltBsdAgmentationSystem65" 1 "GPS, 

33-" 0 "value not used" ;
VAL_ 2583299326 SID 255 "nVldPsFxTTItTRng0T250FrVldPstnFx" ;
VAL_ 2583299326 RangeResidualMode 3 "Null" 2 "Error" 1 "RangeResidualCalculateddAfterPos" 0 "RangeResidualWereUsedtoCalcData" ;
VAL_ 2583300606 SVIDOfMostLikelyFailedSat 96 "GLONASSFrGLONASSStlltsArIdntfdBy" 64 "SBASStlltBsdAgmentationSystem65" 1 "GPS, 

33-" 0 "value not used" ;
VAL_ 2583300606 IntegrityFlag 3 "UnsfMnsRcvrDsNtHvThisCapability" 2 "Caution" 1 "Safe" 0 "No Integrity checking,*" ;
VAL_ 2583300606 SequenceID_ 255 "nVldPsFxTTItTRng0T250FrVldPstnFx" ;
VAL_ 2583299838 SID 255 "nVldPsFxTTItTRng0T250FrVldPstnFx" ;
VAL_ 2583301118 SequenceID_ 255 "nVldPsFxTTItTRng0T250FrVldPstnFx" ;
VAL_ 2381841918 ReferenceStationTypeN 15 "Null" 14 "Error" 13 "Reserved" 1 "GLONASS; 

0x3 to" 0 "GPS" ;
VAL_ 2381841918 ReferenceStationType1 15 "Null" 14 "Error" 13 "Reserved" 1 "GLONASS; 

0x3 to" 0 "GPS" ;
VAL_ 2381841918 Integrity 3 "UnsfMnsRcvrDsNtHvThisCapability" 2 "Caution" 1 "Safe" 0 "No Integrity checking,*" ;
VAL_ 2381841918 MethodGNSS 15 "NllPrcsGNSSMnsNDlbrtDgrdtnAndHgh" 14 "Error" 9 "Reserved" 8 "Simulate mode" 7 "Manual Input" 6 "Estimated (DR) mode" 5 "RTK Float" 4 "RTK Fixed Integer" 3 "Precise GNSS*" 2 "DGNSS fix" 1 "GNSS fix" 0 "no GPS" ;
VAL_ 2381841918 TypeOfSystem_ 21 "Reserved for future combinations" 4 "GPS+SBAS+GLONASS

0x05 -" 3 "GPS+SBAS(WAAS)" 2 "GPS+GLONASS" 1 "GLONASS" 0 "GPS" ;
VAL_ 2381841918 PosTime 0 "midnight,  time is in UTC" ;
VAL_ 2381841918 SID 255 "nVldPsFxTTItTRng0T250FrVldPstnFx" ;
VAL_ 2583301886 DiffOperationMode 15 "No Selection" 14 "Error" 3 "Reserved" 2 "Auto Range" 1 "Auto Power" 0 "Manual" ;
VAL_ 2583301886 DiffSource 15 "No Selection" 14 "Error" 8 "Reserved" 7 "Other Satellite" 6 "SBAS" 5 "Other Ground-based Radio" 4 "AIS" 3 "FM Subcarrier" 2 "MSK Beacon" 1 "Loran Communications" 0 "Auto Select" ;
VAL_ 2583301886 SerialInterfaceDetectionMode 7 "Null" 6 "Error" 2 "Reserved" 1 "Manual bit rate set" 0 "Auto bit rate set" ;
VAL_ 2583301886 SerialInterfaceBitRate 31 "Null" 30 "Error" 29 "Reserved" 12 "57600bps,

13-" 11 "38400bps" 10 "19200bps" 9 "9600bps" 8 "4800bps" 7 "2400bps" 6 "1200bps" 5 "500bps" 4 "300bps" 3 "200bps" 2 "100bps" 1 "50bps" 0 "25bps" ;
VAL_ 2583302142 DiffSource 15 "No Selection" 14 "Error" 8 "Reserved" 7 "Other Satellite" 6 "SBAS" 5 "Other Ground-based Radio" 4 "AIS" 3 "FM Subcarrier" 2 "MSK Beacon" 1 "Loran Communications" 0 "Auto Select" ;
VAL_ 2583302142 UsedAsCorrectionSource 3 "[Unavailable, Unknown]" 2 "Error" 1 "[Yes, On, Enabled, Set, '1']" 0 "[No, Off, Disabled, Reset, '0']" ;
VAL_ 2583302142 DiffSignalDetectionMode 7 "Null" 6 "Error" 2 "Reserved" 1 "Manual bit rate set" 0 "Auto bit rate set" ;
VAL_ 2583302142 DiffSignalBitRate 3 "200bps" 2 "100bps" 1 "50bps" 0 "25bps" 31 "Null" 30 "Error" 29 "Reserved" 12 "57600bps,

13-" 11 "38400bps" 10 "19200bps" 9 "9600bps" 8 "4800bps" 7 "2400bps" 6 "1200bps" 5 "500bps" 4 "300bps" ;
VAL_ 2583302142 StationType 15 "Null" 14 "Error" 13 "Reserved" 1 "GLONASS; 

0x3 to" 0 "GPS" ;
VAL_ 2583302142 SID 255 "nVldPsFxTTItTRng0T250FrVldPstnFx" ;
VAL_ 2583299070 OpMode 7 "Null" 6 "Error" 4 "Reserved" 3 "Auto" 2 "3D" 1 "2D" 0 "1D" ;
VAL_ 2583299070 SetMode 7 "Null" 6 "Error" 4 "Reserved" 3 "Auto" 2 "3D" 1 "2D" 0 "1D" ;
VAL_ 2583299070 SID 255 "nVldPsFxTTItTRng0T250FrVldPstnFx" ;
VAL_ 2583298814 UseAntennaAltitudeFor2DMode 3 "[Unavailable, Unknown]" 2 "Error" 1 "[Yes, On, Enabled, Set, '1']" 0 "[No, Off, Disabled, Reset, '0']" ;
VAL_ 2583298814 Pos_VelocityFilter 2 "Error" 1 "[Yes, On, Enabled, Set, '1']" 0 "[No, Off, Disabled, Reset, '0']" 3 "[Unavailable, Unknown]" ;
VAL_ 2583298814 DGNSSMode 7 "Null" 6 "Error" 5 "Reserved" 4 "RTK Differential Corrections" 3 "RTCA SC159 Network Corrections" 2 "RTCMSC104PseudorangeCorrections" 1 "Auto" 0 "Off" ;
VAL_ 2583298814 GNSSMode 7 "Null" 6 "Error" 4 "Reserved" 3 "Auto" 2 "3D" 1 "2D" 0 "1D" ;
VAL_ 2583303422 PRN 96 "GLONASSFrGLONASSStlltsArIdntfdBy" 64 "SBASStlltBsdAgmentationSystem65" 1 "GPS, 

33-" 0 "value not used" ;
VAL_ 2582778366 FluidType 15 "Data not available" 14 "Error" 13 "Reserved" 6 "Reserved,

  thru" 5 "Black Water (Sewage)" 4 "Oil" 3 "Live Well" 2 "Waste Water" 1 "Fresh Water" 0 "Fuel" ;
VAL_ 2582778366 FluidInstance 15 "Instance number 0 to 15" ;
VAL_ 2516387838 HumidityInstance 3 "Data Not Available" 2 "reserved" 1 "Outside Humidity" 0 "Inside Humidity" ;
VAL_ 2516387838 TempInstance 63 "Data Not Available" 62 "Reserve" 5 "Reserve,

 thru" 4 "Main Cabin Temperature" 3 "Engine Room Temperature" 2 "Inside Temperature" 1 "Outside Temperature" 0 "Sea Temperature" ;
VAL_ 2516387838 SequenceID_ 255 "nVldPsFxTTItTRng0T250FrVldPstnFx" ;
VAL_ 2516387582 SequenceID_ 255 "nVldPsFxTTItTRng0T250FrVldPstnFx" ;
VAL_ 2515667710 EngInstance 255 "Not available" 254 "Error" 253 "Reserve" 1 "DlEngStrBrdTStrnStrbrdNInstncNWh" 0 "SingleEngDualEnginePort" ;
VAL_ 2314338558 EngInstance 255 "Not available" 254 "Error" 253 "Reserve" 1 "DlEngStrBrdTStrnStrbrdNInstncNWh" 0 "SingleEngDualEnginePort" ;
VAL_ 2314338814 EngInstance 255 "Not available" 254 "Error" 253 "Reserve" 1 "DlEngStrBrdTStrnStrbrdNInstncNWh" 0 "SingleEngDualEnginePort" ;
VAL_ 2582975486 MeasurementTime 0 "midnight,  time is in UTC" ;
VAL_ 2382238206 SID 255 "nVldPsFxTTItTRng0T250FrVldPstnFx" ;
VAL_ 2382238206 Set_COG_HeadingRef 3 "Null" 2 "Error" 1 "Magnetic" 0 "True" ;
VAL_ 2382238206 DataMode 15 "Data not available" 14 "Error" 4 "Manual mode" 3 "Simulator mode" 2 "Estimated mode" 1 "Differential, enhanced mode" 0 "Autonomous mode" ;
VAL_ 2583301630 SatelliteID 96 "GLONASSFrGLONASSStlltsArIdntfdBy" 64 "SBASStlltBsdAgmentationSystem65" 1 "GPS, 

33-" 0 "value not used" ;
VAL_ 2583301630 StationHealth 21 "Reserved" 4 "InTestModeDONOTUSE0x05" 3 "Healthy & in Test Mode" 2 "Healthy & Operational" 1 "Unmonitored" 0 "Not Working" ;
VAL_ 2583301630 ReferenceStationType 15 "Null" 14 "Error" 13 "Reserved" 1 "GLONASS; 

0x3 to" 0 "GPS" ;
VAL_ 2583301630 SequenceID_ 255 "nVldPsFxTTItTRng0T250FrVldPstnFx" ;
VAL_ 2583499518 MeasurementTime 0 "midnight,  time is in UTC" ;
VAL_ 2583499518 State 111 "Unavailable, Unknown" 110 "Error" 101 "Reserved" 10 "Ebb" 1 "Slack" 0 "Flood" ;
VAL_ 2583499518 Mode 15 "Data not available" 14 "Error" 4 "Manual mode" 3 "Simulator mode" 2 "Estimated mode" 1 "Differential, enhanced mode" 0 "Autonomous mode" ;
VAL_ 2381906942 NavigationTerminated 3 "[Unavailable, Unknown]" 2 "Error" 1 "[Yes, On, Enabled, Set, '1']" 0 "[No, Off, Disabled, Reset, '0']" ;
VAL_ 2381906942 XTEMode 15 "Data not available" 14 "Error" 4 "Manual mode" 3 "Simulator mode" 2 "Estimated mode" 1 "Differential, enhanced mode" 0 "Autonomous mode" ;
VAL_ 2381906942 SID 255 "nVldPsFxTTItTRng0T250FrVldPstnFx" ;
VAL_ 2583238398 DestinationMarkType 15 "Null" 14 "Error" 5 "Reserved" 4 "Waypoint" 3 "Wheelover" 2 "Reference (general)" 1 "Turning Point" 0 "Collision" ;
VAL_ 2583238398 OriginMarkType 15 "Null" 14 "Error" 5 "Reserved" 4 "Waypoint" 3 "Wheelover" 2 "Reference (general)" 1 "Turning Point" 0 "Collision" ;
VAL_ 2583238398 CalculationType 3 "Null" 2 "Error" 1 "Rhumb Line calculations" 0 "Great Circle calculations" ;
VAL_ 2583238398 BearingRef 3 "Null" 2 "Error" 1 "Magnetic" 0 "True" ;
VAL_ 2583238398 SID 255 "nVldPsFxTTItTRng0T250FrVldPstnFx" ;
VAL_ 2381450750 Indic28 3 "[Unavailable, Unknown]" 2 "Error" 1 "[Yes, On, Enabled, Set, '1']" 0 "[No, Off, Disabled, Reset, '0']" ;
VAL_ 2381450750 Indic27 3 "[Unavailable, Unknown]" 2 "Error" 1 "[Yes, On, Enabled, Set, '1']" 0 "[No, Off, Disabled, Reset, '0']" ;
VAL_ 2381450750 Indic26 3 "[Unavailable, Unknown]" 2 "Error" 1 "[Yes, On, Enabled, Set, '1']" 0 "[No, Off, Disabled, Reset, '0']" ;
VAL_ 2381450750 Indic25 3 "[Unavailable, Unknown]" 2 "Error" 1 "[Yes, On, Enabled, Set, '1']" 0 "[No, Off, Disabled, Reset, '0']" ;
VAL_ 2381450750 Indic24 3 "[Unavailable, Unknown]" 2 "Error" 1 "[Yes, On, Enabled, Set, '1']" 0 "[No, Off, Disabled, Reset, '0']" ;
VAL_ 2381450750 Indic23 3 "[Unavailable, Unknown]" 2 "Error" 1 "[Yes, On, Enabled, Set, '1']" 0 "[No, Off, Disabled, Reset, '0']" ;
VAL_ 2381450750 Indic22 3 "[Unavailable, Unknown]" 2 "Error" 1 "[Yes, On, Enabled, Set, '1']" 0 "[No, Off, Disabled, Reset, '0']" ;
VAL_ 2381450750 Indic21 3 "[Unavailable, Unknown]" 2 "Error" 1 "[Yes, On, Enabled, Set, '1']" 0 "[No, Off, Disabled, Reset, '0']" ;
VAL_ 2381450750 Indic20 3 "[Unavailable, Unknown]" 2 "Error" 1 "[Yes, On, Enabled, Set, '1']" 0 "[No, Off, Disabled, Reset, '0']" ;
VAL_ 2381450750 Indic19 3 "[Unavailable, Unknown]" 2 "Error" 1 "[Yes, On, Enabled, Set, '1']" 0 "[No, Off, Disabled, Reset, '0']" ;
VAL_ 2381450750 Indic18 3 "[Unavailable, Unknown]" 2 "Error" 1 "[Yes, On, Enabled, Set, '1']" 0 "[No, Off, Disabled, Reset, '0']" ;
VAL_ 2381450750 Indic17 3 "[Unavailable, Unknown]" 2 "Error" 1 "[Yes, On, Enabled, Set, '1']" 0 "[No, Off, Disabled, Reset, '0']" ;
VAL_ 2381450750 Indic16 3 "[Unavailable, Unknown]" 2 "Error" 1 "[Yes, On, Enabled, Set, '1']" 0 "[No, Off, Disabled, Reset, '0']" ;
VAL_ 2381450750 Indic15 3 "[Unavailable, Unknown]" 2 "Error" 1 "[Yes, On, Enabled, Set, '1']" 0 "[No, Off, Disabled, Reset, '0']" ;
VAL_ 2381450750 Indic14 3 "[Unavailable, Unknown]" 2 "Error" 1 "[Yes, On, Enabled, Set, '1']" 0 "[No, Off, Disabled, Reset, '0']" ;
VAL_ 2381450750 Indic13 3 "[Unavailable, Unknown]" 2 "Error" 1 "[Yes, On, Enabled, Set, '1']" 0 "[No, Off, Disabled, Reset, '0']" ;
VAL_ 2381450750 Indic12 3 "[Unavailable, Unknown]" 2 "Error" 1 "[Yes, On, Enabled, Set, '1']" 0 "[No, Off, Disabled, Reset, '0']" ;
VAL_ 2381450750 Indic11 3 "[Unavailable, Unknown]" 2 "Error" 1 "[Yes, On, Enabled, Set, '1']" 0 "[No, Off, Disabled, Reset, '0']" ;
VAL_ 2381450750 Indic10 3 "[Unavailable, Unknown]" 2 "Error" 1 "[Yes, On, Enabled, Set, '1']" 0 "[No, Off, Disabled, Reset, '0']" ;
VAL_ 2381450750 Indic9 3 "[Unavailable, Unknown]" 2 "Error" 1 "[Yes, On, Enabled, Set, '1']" 0 "[No, Off, Disabled, Reset, '0']" ;
VAL_ 2381450750 Indic8 3 "[Unavailable, Unknown]" 2 "Error" 1 "[Yes, On, Enabled, Set, '1']" 0 "[No, Off, Disabled, Reset, '0']" ;
VAL_ 2381450750 Indic7 3 "[Unavailable, Unknown]" 2 "Error" 1 "[Yes, On, Enabled, Set, '1']" 0 "[No, Off, Disabled, Reset, '0']" ;
VAL_ 2381450750 Indic6 3 "[Unavailable, Unknown]" 2 "Error" 1 "[Yes, On, Enabled, Set, '1']" 0 "[No, Off, Disabled, Reset, '0']" ;
VAL_ 2381450750 Indic5 3 "[Unavailable, Unknown]" 2 "Error" 1 "[Yes, On, Enabled, Set, '1']" 0 "[No, Off, Disabled, Reset, '0']" ;
VAL_ 2381450750 Indic4 3 "[Unavailable, Unknown]" 2 "Error" 1 "[Yes, On, Enabled, Set, '1']" 0 "[No, Off, Disabled, Reset, '0']" ;
VAL_ 2381450750 Indic3 3 "[Unavailable, Unknown]" 2 "Error" 1 "[Yes, On, Enabled, Set, '1']" 0 "[No, Off, Disabled, Reset, '0']" ;
VAL_ 2381450750 Indic2 3 "[Unavailable, Unknown]" 2 "Error" 1 "[Yes, On, Enabled, Set, '1']" 0 "[No, Off, Disabled, Reset, '0']" ;
VAL_ 2381450750 Indic1 3 "[Unavailable, Unknown]" 2 "Error" 1 "[Yes, On, Enabled, Set, '1']" 0 "[No, Off, Disabled, Reset, '0']" ;
VAL_ 2582779134 SID 255 "nVldPsFxTTItTRng0T250FrVldPstnFx" ;
VAL_ 2381388286 SID 255 "nVldPsFxTTItTRng0T250FrVldPstnFx" ;
VAL_ 2314732798 Direction 3 "Null" 2 "Error" 1 "Magnetic" 0 "True" ;
VAL_ 2314732798 GNSSQuality 15 "NllPrcsGNSSMnsNDlbrtDgrdtnAndHgh" 14 "Error" 9 "Reserved" 8 "Simulate mode" 7 "Manual Input" 6 "Estimated (DR) mode" 5 "RTK Float" 4 "RTK Fixed Integer" 3 "Precise GNSS*" 2 "DGNSS fix" 1 "GNSS fix" 0 "no GPS" ;
VAL_ 2314732798 SequenceID_ 255 "nVldPsFxTTItTRng0T250FrVldPstnFx" ;
VAL_ 2650474750 AISTransceiverInformation 4 "Own information not broadcast" 3 "Channel B VDL transmission" 5 "Reserved" 2 "Channel A VDL transmission" 1 "Channel B VDL reception" 0 "Channel A VDL reception" ;
VAL_ 2650474750 RepeatIndicator 3 "FnlRTrnsSITURM13711FrMrInfrmton" 2 "Second retransmission" 1 "First retransmission" 0 "Default" ;
VAL_ 2650472958 TypeOfElectronicPosingDevice 8 "RsrvFrFtrUsSITURM13711FrMrInfrmt" ;
VAL_ 2650472958 AISTransceiverInformation 4 "Own information not broadcast" 3 "Channel B VDL transmission" 5 "Reserved" 2 "Channel A VDL transmission" 1 "Channel B VDL reception" 0 "Channel A VDL reception" ;
VAL_ 2650472958 PosTime 0 "midnight,  time is in UTC" ;
VAL_ 2650472958 RAIMflag 1 "RAIMInUsSITURM13711FrMrInfrmton" 0 "RAIM not in use (default)" ;
VAL_ 2650472958 RepeatIndicator 3 "FnlRTrnsSITURM13711FrMrInfrmton" 2 "Second retransmission" 1 "First retransmission" 0 "Default" ;
VAL_ 2650475262 AISTransceiverInformation 4 "Own information not broadcast" 3 "Channel B VDL transmission" 5 "Reserved" 2 "Channel A VDL transmission" 1 "Channel B VDL reception" 0 "Channel A VDL reception" ;
VAL_ 2650475262 RepeatIndicator 3 "FnlRTrnsSITURM13711FrMrInfrmton" 2 "Second retransmission" 1 "First retransmission" 0 "Default" ;
VAL_ 2650474238 AISTransceiverInformation 4 "Own information not broadcast" 3 "Channel B VDL transmission" 5 "Reserved" 2 "Channel A VDL transmission" 1 "Channel B VDL reception" 0 "Channel A VDL reception" ;
VAL_ 2650474238 TimeStamp 63 "PsngSystmIsInprtvSITURM13711FrMr" 62 "ElctrncPsFxngSystmOprtsInEstMde" 61 "PosingSystemIsInManualInputMode" 60 "timeStampNotAvailable" 0 "UTCSecondWhenReportWasGenerated" ;
VAL_ 2650474238 RAIMFlag 1 "RAIMInUsSITURM13711FrMrInfrmton" 0 "RAIM not in use (default)" ;
VAL_ 2650474238 RepeatIndicator 3 "FnlRTrnsSITURM13711FrMrInfrmton" 2 "Second retransmission" 1 "First retransmission" 0 "Default" ;
VAL_ 2650475518 AISTransceiverInformation 4 "Own information not broadcast" 3 "Channel B VDL transmission" 5 "Reserved" 2 "Channel A VDL transmission" 1 "Channel B VDL reception" 0 "Channel A VDL reception" ;
VAL_ 2650475518 RepeatIndicator 3 "FnlRTrnsSITURM13711FrMrInfrmton" 2 "Second retransmission" 1 "First retransmission" 0 "Default" ;
VAL_ 2650476030 AISTransceiverInformation 4 "Own information not broadcast" 3 "Channel B VDL transmission" 5 "Reserved" 2 "Channel A VDL transmission" 1 "Channel B VDL reception" 0 "Channel A VDL reception" ;
VAL_ 2650476030 RepeatIndicator 3 "FnlRTrnsSITURM13711FrMrInfrmton" 2 "Second retransmission" 1 "First retransmission" 0 "Default" ;
VAL_ 2583363838 AISTransceiverInformation 4 "Own information not broadcast" 3 "Channel B VDL transmission" 5 "Reserved" 2 "Channel A VDL transmission" 1 "Channel B VDL reception" 0 "Channel A VDL reception" ;
VAL_ 2583363838 RepeatIndicator 3 "FnlRTrnsSITURM13711FrMrInfrmton" 2 "Second retransmission" 1 "First retransmission" 0 "Default" ;
VAL_ 2650473214 RepeatIndicator 3 "FnlRTrnsSITURM13711FrMrInfrmton" 2 "Second retransmission" 1 "First retransmission" 0 "Default" ;
VAL_ 2448953342 AISTransceiverInformation 4 "Own information not broadcast" 3 "Channel B VDL transmission" 5 "Reserved" 2 "Channel A VDL transmission" 1 "Channel B VDL reception" 0 "Channel A VDL reception" ;
VAL_ 2448953342 TimeStamp 63 "PsngSystmIsInprtvSITURM13711FrMr" 62 "ElctrncPsFxngSystmOprtsInEstMde" 61 "PosingSystemIsInManualInputMode" 60 "timeStampNotAvailable" 0 "UTCSecondWhenReportWasGenerated" ;
VAL_ 2448953342 RAIMflag 1 "RAIMInUsSITURM13711FrMrInfrmton" 0 "RAIM not in use (default)" ;
VAL_ 2448953342 RepeatIndicator 3 "FnlRTrnsSITURM13711FrMrInfrmton" 2 "Second retransmission" 1 "First retransmission" 0 "Default" ;
VAL_ 2448953598 TypeOfElectronicPosingDevice 8 "RsrvFrFtrUsSITURM13711FrMrInfrmt" ;
VAL_ 2448953598 Ship_CargoType 255 "ReservedForFuture" 199 "ReservedForRegional200" 1 "100" ;
VAL_ 2448953598 TimeStamp 63 "PsngSystmIsInprtvSITURM13711FrMr" 62 "ElctrncPsFxngSystmOprtsInEstMde" 61 "PosingSystemIsInManualInputMode" 60 "timeStampNotAvailable" 0 "UTCSecondWhenReportWasGenerated" ;
VAL_ 2448953598 RAIMflag 1 "RAIMInUsSITURM13711FrMrInfrmton" 0 "RAIM not in use (default)" ;
VAL_ 2448953598 RepeatIndicator 3 "FnlRTrnsSITURM13711FrMrInfrmton" 2 "Second retransmission" 1 "First retransmission" 0 "Default" ;
VAL_ 2448953086 NavigationalStatus 15 "ntDfndSITURM13711FrMrInfrmation" 14 "reserved for future use" 10 "rsrvdFrFtrAmndmntOfNvgtnlSttsFrS" 8 "under way sailing" 7 "engaged in fishing" 6 "aground" 5 "moored" 4 "constrained by her draught" 3 "restricted manoeuvrability" 2 "not under command" 1 "at anchor" 0 "under way using engine" ;
VAL_ 2448953086 AISTransceiverInformation 4 "Own information not broadcast" 3 "Channel B VDL transmission" 5 "Reserved" 2 "Channel A VDL transmission" 1 "Channel B VDL reception" 0 "Channel A VDL reception" ;
VAL_ 2448953086 TimeStamp 63 "PsngSystmIsInprtvSITURM13711FrMr" 62 "ElctrncPsFxngSystmOprtsInEstMde" 61 "PosingSystemIsInManualInputMode" 60 "timeStampNotAvailable" 0 "UTCSecondWhenReportWasGenerated" ;
VAL_ 2448953086 RAIMflag 1 "RAIMInUsSITURM13711FrMrInfrmton" 0 "RAIM not in use (default)" ;
VAL_ 2448953086 RepeatIndicator 3 "FnlRTrnsSITURM13711FrMrInfrmton" 2 "Second retransmission" 1 "First retransmission" 0 "Default" ;
VAL_ 2650473982 AISTransceiverInformation 4 "Own information not broadcast" 3 "Channel B VDL transmission" 5 "Reserved" 2 "Channel A VDL transmission" 1 "Channel B VDL reception" 0 "Channel A VDL reception" ;
VAL_ 2650473982 RepeatIndicator 3 "FnlRTrnsSITURM13711FrMrInfrmton" 2 "Second retransmission" 1 "First retransmission" 0 "Default" ;
VAL_ 2650475774 AISTransceiverInformation 4 "Own information not broadcast" 3 "Channel B VDL transmission" 5 "Reserved" 2 "Channel A VDL transmission" 1 "Channel B VDL reception" 0 "Channel A VDL reception" ;
VAL_ 2650475774 RepeatIndicator 3 "FnlRTrnsSITURM13711FrMrInfrmton" 2 "Second retransmission" 1 "First retransmission" 0 "Default" ;
VAL_ 2650475006 AISTransceiverInformation 4 "Own information not broadcast" 3 "Channel B VDL transmission" 5 "Reserved" 2 "Channel A VDL transmission" 1 "Channel B VDL reception" 0 "Channel A VDL reception" ;
VAL_ 2650475006 RepeatIndicator 3 "FnlRTrnsSITURM13711FrMrInfrmton" 2 "Second retransmission" 1 "First retransmission" 0 "Default" ;
VAL_ 2650473470 AISTransceiverInformation 4 "Own information not broadcast" 3 "Channel B VDL transmission" 5 "Reserved" 2 "Channel A VDL transmission" 1 "Channel B VDL reception" 0 "Channel A VDL reception" ;
VAL_ 2650473470 RepeatIndicator 3 "FnlRTrnsSITURM13711FrMrInfrmton" 2 "Second retransmission" 1 "First retransmission" 0 "Default" ;
VAL_ 2650473726 AISTransceiverInformation 4 "Own information not broadcast" 3 "Channel B VDL transmission" 5 "Reserved" 2 "Channel A VDL transmission" 1 "Channel B VDL reception" 0 "Channel A VDL reception" ;
VAL_ 2650473726 RepeatIndicator 3 "FnlRTrnsSITURM13711FrMrInfrmton" 2 "Second retransmission" 1 "First retransmission" 0 "Default" ;
VAL_ 2365475070 WheelBasedMachineDirection 0 "Reverse" 1 "Forward" 2 "ErrorIndicator" 3 "NotAvailable" ;
VAL_ 2365475070 KeySwitchState 0 "KeySwitchOff" 1 "KeySwitchNotOff" 2 "ErrorIndication" 3 "NotAvailable" ;
VAL_ 2365475070 StartStopState 0 "Stop or disable implement work" 1 "Start or enable implement work" 2 "Reserved" 3 "Don't Care" ;
VAL_ 2365475070 OperatorDirectionReversed 3 "Not available" 2 "Error" 1 "Reversed" 0 "Not reversed" ;
